[part 4 of 11: package /CANAnalyzer/CommunicationClusters]
AUTOSAR XML (schema 00051)
package /CANAnalyzer/CommunicationClusters  (continued)
  can cluster CAN_FD_IPB_41  (continued)
    can physical channel Channel  (continued)
      frame StatusBLEDeviceNameFBD_VR: id 0x28F, frame-length=32, can-addressing-mode=STANDARD, can-frame-rx-behavior=CAN-FD, can-frame-tx-behavior=CAN-FD
        pdu StatusBLEDeviceNameFBD_VR: length=32, unused-bit-pattern=0
          signal StatusBLEDeviceNameFBD_VR_Character00: start 0, 8 bit, little-endian, data-type-policy=OVERRIDE, base-type=uint8, compu {phys=raw}, range phys 0..252
          signal StatusBLEDeviceNameFBD_VR_Character01: start 8, 8 bit, little-endian, data-type-policy=OVERRIDE, base-type=uint8, compu {phys=raw}, range phys 0..252
          signal StatusBLEDeviceNameFBD_VR_Character02: start 16, 8 bit, little-endian, data-type-policy=OVERRIDE, base-type=uint8, compu {phys=raw}, range phys 0..252
          signal StatusBLEDeviceNameFBD_VR_Character03: start 24, 8 bit, little-endian, data-type-policy=OVERRIDE, base-type=uint8, compu {phys=raw}, range phys 0..252
          signal StatusBLEDeviceNameFBD_VR_Character04: start 32, 8 bit, little-endian, data-type-policy=OVERRIDE, base-type=uint8, compu {phys=raw}, range phys 0..252
          signal StatusBLEDeviceNameFBD_VR_Character05: start 40, 8 bit, little-endian, data-type-policy=OVERRIDE, base-type=uint8, compu {phys=raw}, range phys 0..252
          signal StatusBLEDeviceNameFBD_VR_Character06: start 48, 8 bit, little-endian, data-type-policy=OVERRIDE, base-type=uint8, compu {phys=raw}, range phys 0..252
          signal StatusBLEDeviceNameFBD_VR_Character07: start 56, 8 bit, little-endian, data-type-policy=OVERRIDE, base-type=uint8, compu {phys=raw}, range phys 0..252
          signal StatusBLEDeviceNameFBD_VR_Character08: start 64, 8 bit, little-endian, data-type-policy=OVERRIDE, base-type=uint8, compu {phys=raw}, range phys 0..252
          signal StatusBLEDeviceNameFBD_VR_Character09: start 72, 8 bit, little-endian, data-type-policy=OVERRIDE, base-type=uint8, compu {phys=raw}, range phys 0..252
          signal StatusBLEDeviceNameFBD_VR_Character10: start 80, 8 bit, little-endian, data-type-policy=OVERRIDE, base-type=uint8, compu {phys=raw}, range phys 0..252
          signal StatusBLEDeviceNameFBD_VR_Character11: start 88, 8 bit, little-endian, data-type-policy=OVERRIDE, base-type=uint8, compu {phys=raw}, range phys 0..252
          signal StatusBLEDeviceNameFBD_VR_Character12: start 96, 8 bit, little-endian, data-type-policy=OVERRIDE, base-type=uint8, compu {phys=raw}, range phys 0..252
          signal StatusBLEDeviceNameFBD_VR_Character13: start 104, 8 bit, little-endian, data-type-policy=OVERRIDE, base-type=uint8, compu {phys=raw}, range phys 0..252
          signal StatusBLEDeviceNameFBD_VR_Character14: start 112, 8 bit, little-endian, data-type-policy=OVERRIDE, base-type=uint8, compu {phys=raw}, range phys 0..252
          signal StatusBLEDeviceNameFBD_VR_Character15: start 120, 8 bit, little-endian, data-type-policy=OVERRIDE, base-type=uint8, compu {phys=raw}, range phys 0..252
          signal StatusBLEDeviceNameFBD_VR_Character16: start 128, 8 bit, little-endian, data-type-policy=OVERRIDE, base-type=uint8, compu {phys=raw}, range phys 0..252
          signal StatusBLEDeviceNameFBD_VR_Character17: start 136, 8 bit, little-endian, data-type-policy=OVERRIDE, base-type=uint8, compu {phys=raw}, range phys 0..252
          signal StatusBLEDeviceNameFBD_VR_Character18: start 144, 8 bit, little-endian, data-type-policy=OVERRIDE, base-type=uint8, compu {phys=raw}, range phys 0..252
          signal StatusBLEDeviceNameFBD_VR_Character19: start 152, 8 bit, little-endian, data-type-policy=OVERRIDE, base-type=uint8, compu {phys=raw}, range phys 0..252
          signal StatusBLEDeviceNameFBD_VR_Character20: start 160, 8 bit, little-endian, data-type-policy=OVERRIDE, base-type=uint8, compu {phys=raw}, range phys 0..252
          signal StatusBLEDeviceNameFBD_VR_Character21: start 168, 8 bit, little-endian, data-type-policy=OVERRIDE, base-type=uint8, compu {phys=raw}, range phys 0..252
          signal StatusBLEDeviceNameFBD_VR_Character22: start 176, 8 bit, little-endian, data-type-policy=OVERRIDE, base-type=uint8, compu {phys=raw}, range phys 0..252
          signal StatusBLEDeviceNameFBD_VR_Character23: start 184, 8 bit, little-endian, data-type-policy=OVERRIDE, base-type=uint8, compu {phys=raw}, range phys 0..252
          signal StatusBLEDeviceNameFBD_VR_Character24: start 192, 8 bit, little-endian, data-type-policy=OVERRIDE, base-type=uint8, compu {phys=raw}, range phys 0..252
          signal StatusBLEDeviceNameFBD_VR_Character25: start 200, 8 bit, little-endian, data-type-policy=OVERRIDE, base-type=uint8, compu {phys=raw}, range phys 0..252
          signal StatusBLEDeviceNameFBD_VR_Character26: start 208, 8 bit, little-endian, data-type-policy=OVERRIDE, base-type=uint8, compu {phys=raw}, range phys 0..252
          signal StatusBLEDeviceNameFBD_VR_Character27: start 216, 8 bit, little-endian, data-type-policy=OVERRIDE, base-type=uint8, compu {phys=raw}, range phys 0..252
          signal StatusBLEDeviceNameFBD_VR_Character28: start 224, 8 bit, little-endian, data-type-policy=OVERRIDE, base-type=uint8, compu {phys=raw}, range phys 0..252
          signal StatusBLEDeviceNameFBD_VR_Character29: start 232, 8 bit, little-endian, data-type-policy=OVERRIDE, base-type=uint8, compu {phys=raw}, range phys 0..252
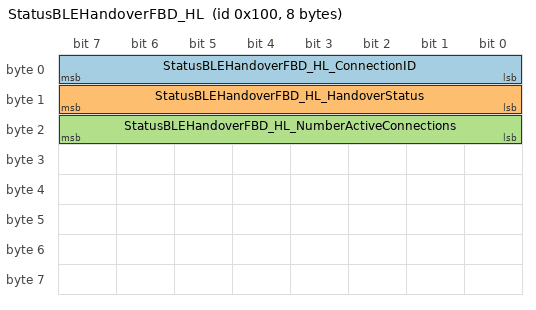
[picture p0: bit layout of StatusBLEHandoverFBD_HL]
      frame StatusBLEHandoverFBD_HL: id 0x100, frame-length=8, can-addressing-mode=STANDARD, can-frame-rx-behavior=CAN-20, can-frame-tx-behavior=CAN-20
        pdu StatusBLEHandoverFBD_HL: length=8, unused-bit-pattern=0
          signal StatusBLEHandoverFBD_HL_ConnectionID: start 0, 8 bit, little-endian, data-type-policy=OVERRIDE, base-type=uint8, compu {phys=raw}, range phys 0..252
          signal StatusBLEHandoverFBD_HL_HandoverStatus: start 8, 8 bit, little-endian, data-type-policy=OVERRIDE, compu {phys=raw}
          signal StatusBLEHandoverFBD_HL_NumberActiveConnections: start 16, 8 bit, little-endian, data-type-policy=OVERRIDE, base-type=uint8, compu {phys=raw}, range phys 0..252
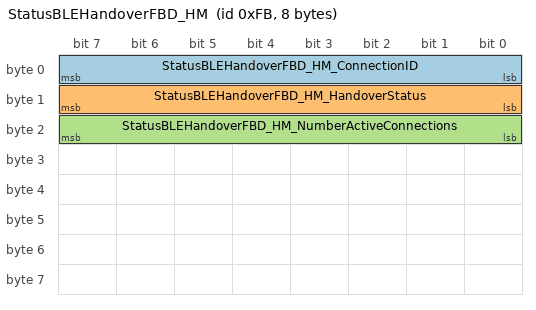
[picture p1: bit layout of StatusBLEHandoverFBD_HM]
      frame StatusBLEHandoverFBD_HM: id 0xFB, frame-length=8, can-addressing-mode=STANDARD, can-frame-rx-behavior=CAN-20, can-frame-tx-behavior=CAN-20
        pdu StatusBLEHandoverFBD_HM: length=8, unused-bit-pattern=0
          signal StatusBLEHandoverFBD_HM_ConnectionID: start 0, 8 bit, little-endian, data-type-policy=OVERRIDE, base-type=uint8, compu {phys=raw}, range phys 0..252
          signal StatusBLEHandoverFBD_HM_HandoverStatus: start 8, 8 bit, little-endian, data-type-policy=OVERRIDE, compu {phys=raw}
          signal StatusBLEHandoverFBD_HM_NumberActiveConnections: start 16, 8 bit, little-endian, data-type-policy=OVERRIDE, base-type=uint8, compu {phys=raw}, range phys 0..252
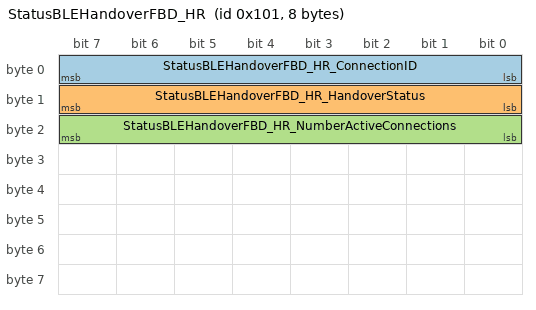
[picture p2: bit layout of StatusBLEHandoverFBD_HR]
      frame StatusBLEHandoverFBD_HR: id 0x101, frame-length=8, can-addressing-mode=STANDARD, can-frame-rx-behavior=CAN-20, can-frame-tx-behavior=CAN-20
        pdu StatusBLEHandoverFBD_HR: length=8, unused-bit-pattern=0
          signal StatusBLEHandoverFBD_HR_ConnectionID: start 0, 8 bit, little-endian, data-type-policy=OVERRIDE, base-type=uint8, compu {phys=raw}, range phys 0..252
          signal StatusBLEHandoverFBD_HR_HandoverStatus: start 8, 8 bit, little-endian, data-type-policy=OVERRIDE, compu {phys=raw}
          signal StatusBLEHandoverFBD_HR_NumberActiveConnections: start 16, 8 bit, little-endian, data-type-policy=OVERRIDE, base-type=uint8, compu {phys=raw}, range phys 0..252
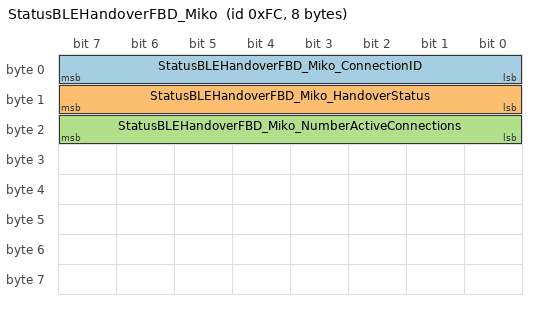
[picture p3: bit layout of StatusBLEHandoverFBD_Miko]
      frame StatusBLEHandoverFBD_Miko: id 0xFC, frame-length=8, can-addressing-mode=STANDARD, can-frame-rx-behavior=CAN-20, can-frame-tx-behavior=CAN-20
        pdu StatusBLEHandoverFBD_Miko: length=8, unused-bit-pattern=0
          signal StatusBLEHandoverFBD_Miko_ConnectionID: start 0, 8 bit, little-endian, data-type-policy=OVERRIDE, base-type=uint8, compu {phys=raw}, range phys 0..252
          signal StatusBLEHandoverFBD_Miko_HandoverStatus: start 8, 8 bit, little-endian, data-type-policy=OVERRIDE, compu {phys=raw}
          signal StatusBLEHandoverFBD_Miko_NumberActiveConnections: start 16, 8 bit, little-endian, data-type-policy=OVERRIDE, base-type=uint8, compu {phys=raw}, range phys 0..252
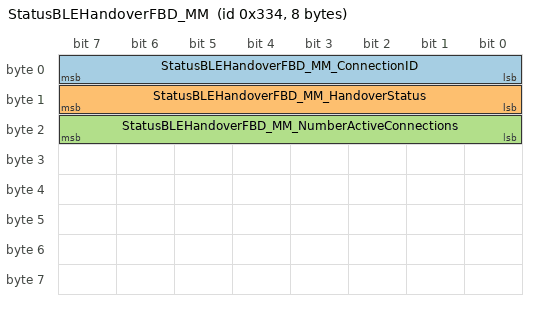
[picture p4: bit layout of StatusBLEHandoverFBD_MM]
      frame StatusBLEHandoverFBD_MM: id 0x334, frame-length=8, can-addressing-mode=STANDARD, can-frame-rx-behavior=CAN-20, can-frame-tx-behavior=CAN-20
        pdu StatusBLEHandoverFBD_MM: length=8, unused-bit-pattern=0
          signal StatusBLEHandoverFBD_MM_ConnectionID: start 0, 8 bit, little-endian, data-type-policy=OVERRIDE, base-type=uint8, compu {phys=raw}, range phys 0..252
          signal StatusBLEHandoverFBD_MM_HandoverStatus: start 8, 8 bit, little-endian, data-type-policy=OVERRIDE, compu {phys=raw}
          signal StatusBLEHandoverFBD_MM_NumberActiveConnections: start 16, 8 bit, little-endian, data-type-policy=OVERRIDE, base-type=uint8, compu {phys=raw}, range phys 0..252
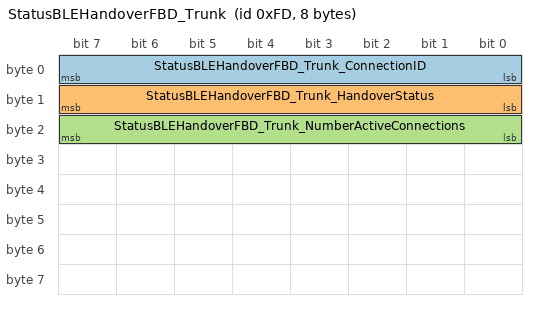
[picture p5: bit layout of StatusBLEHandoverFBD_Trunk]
      frame StatusBLEHandoverFBD_Trunk: id 0xFD, frame-length=8, can-addressing-mode=STANDARD, can-frame-rx-behavior=CAN-20, can-frame-tx-behavior=CAN-20
        pdu StatusBLEHandoverFBD_Trunk: length=8, unused-bit-pattern=0
          signal StatusBLEHandoverFBD_Trunk_ConnectionID: start 0, 8 bit, little-endian, data-type-policy=OVERRIDE, base-type=uint8, compu {phys=raw}, range phys 0..252
          signal StatusBLEHandoverFBD_Trunk_HandoverStatus: start 8, 8 bit, little-endian, data-type-policy=OVERRIDE, compu {phys=raw}
          signal StatusBLEHandoverFBD_Trunk_NumberActiveConnections: start 16, 8 bit, little-endian, data-type-policy=OVERRIDE, base-type=uint8, compu {phys=raw}, range phys 0..252
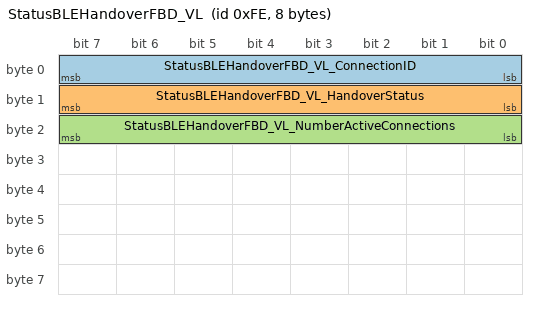
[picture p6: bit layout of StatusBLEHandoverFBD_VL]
      frame StatusBLEHandoverFBD_VL: id 0xFE, frame-length=8, can-addressing-mode=STANDARD, can-frame-rx-behavior=CAN-20, can-frame-tx-behavior=CAN-20
        pdu StatusBLEHandoverFBD_VL: length=8, unused-bit-pattern=0
          signal StatusBLEHandoverFBD_VL_ConnectionID: start 0, 8 bit, little-endian, data-type-policy=OVERRIDE, base-type=uint8, compu {phys=raw}, range phys 0..252
          signal StatusBLEHandoverFBD_VL_HandoverStatus: start 8, 8 bit, little-endian, data-type-policy=OVERRIDE, compu {phys=raw}
          signal StatusBLEHandoverFBD_VL_NumberActiveConnections: start 16, 8 bit, little-endian, data-type-policy=OVERRIDE, base-type=uint8, compu {phys=raw}, range phys 0..252
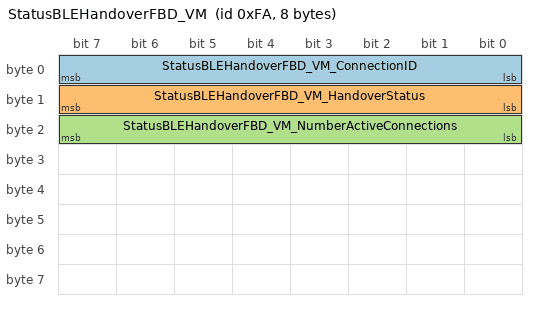
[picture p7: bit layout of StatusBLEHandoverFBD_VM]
      frame StatusBLEHandoverFBD_VM: id 0xFA, frame-length=8, can-addressing-mode=STANDARD, can-frame-rx-behavior=CAN-20, can-frame-tx-behavior=CAN-20
        pdu StatusBLEHandoverFBD_VM: length=8, unused-bit-pattern=0
          signal StatusBLEHandoverFBD_VM_ConnectionID: start 0, 8 bit, little-endian, data-type-policy=OVERRIDE, base-type=uint8, compu {phys=raw}, range phys 0..252
          signal StatusBLEHandoverFBD_VM_HandoverStatus: start 8, 8 bit, little-endian, data-type-policy=OVERRIDE, compu {phys=raw}
          signal StatusBLEHandoverFBD_VM_NumberActiveConnections: start 16, 8 bit, little-endian, data-type-policy=OVERRIDE, base-type=uint8, compu {phys=raw}, range phys 0..252
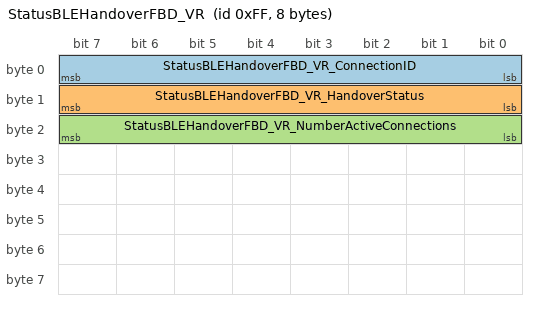
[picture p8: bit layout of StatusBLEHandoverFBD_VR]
      frame StatusBLEHandoverFBD_VR: id 0xFF, frame-length=8, can-addressing-mode=STANDARD, can-frame-rx-behavior=CAN-20, can-frame-tx-behavior=CAN-20
        pdu StatusBLEHandoverFBD_VR: length=8, unused-bit-pattern=0
          signal StatusBLEHandoverFBD_VR_ConnectionID: start 0, 8 bit, little-endian, data-type-policy=OVERRIDE, base-type=uint8, compu {phys=raw}, range phys 0..252
          signal StatusBLEHandoverFBD_VR_HandoverStatus: start 8, 8 bit, little-endian, data-type-policy=OVERRIDE, compu {phys=raw}
          signal StatusBLEHandoverFBD_VR_NumberActiveConnections: start 16, 8 bit, little-endian, data-type-policy=OVERRIDE, base-type=uint8, compu {phys=raw}, range phys 0..252
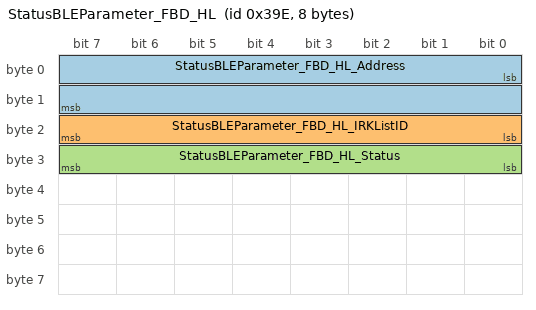
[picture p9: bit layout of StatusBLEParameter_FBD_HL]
      frame StatusBLEParameter_FBD_HL: id 0x39E, frame-length=8, can-addressing-mode=STANDARD, can-frame-rx-behavior=CAN-20, can-frame-tx-behavior=CAN-20
        pdu StatusBLEParameter_FBD_HL: length=8, unused-bit-pattern=0
          signal StatusBLEParameter_FBD_HL_Address: start 0, 16 bit, little-endian, data-type-policy=OVERRIDE, compu {phys=raw}
          signal StatusBLEParameter_FBD_HL_IRKListID: start 16, 8 bit, little-endian, data-type-policy=OVERRIDE, base-type=uint8, compu {phys=raw}, range phys 0..252
          signal StatusBLEParameter_FBD_HL_Status: start 24, 8 bit, little-endian, data-type-policy=OVERRIDE, base-type=uint8, compu {phys=raw}, range phys 0..255
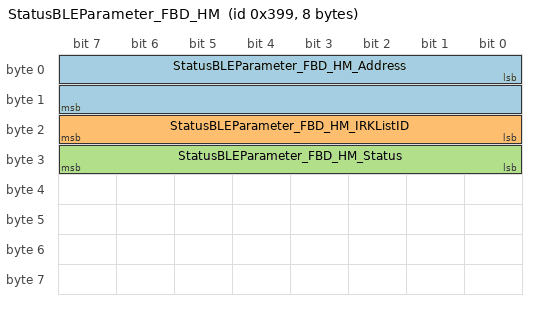
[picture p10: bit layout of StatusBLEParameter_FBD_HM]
      frame StatusBLEParameter_FBD_HM: id 0x399, frame-length=8, can-addressing-mode=STANDARD, can-frame-rx-behavior=CAN-20, can-frame-tx-behavior=CAN-20
        pdu StatusBLEParameter_FBD_HM: length=8, unused-bit-pattern=0
          signal StatusBLEParameter_FBD_HM_Address: start 0, 16 bit, little-endian, data-type-policy=OVERRIDE, compu {phys=raw}
          signal StatusBLEParameter_FBD_HM_IRKListID: start 16, 8 bit, little-endian, data-type-policy=OVERRIDE, base-type=uint8, compu {phys=raw}, range phys 0..252
          signal StatusBLEParameter_FBD_HM_Status: start 24, 8 bit, little-endian, data-type-policy=OVERRIDE, base-type=uint8, compu {phys=raw}, range phys 0..255
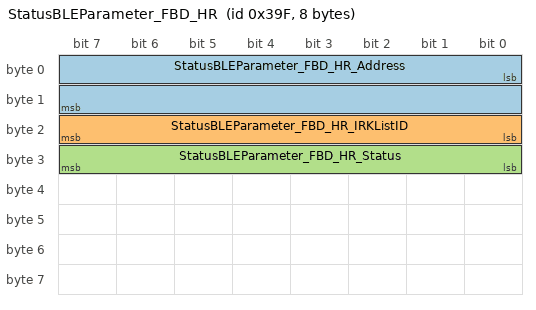
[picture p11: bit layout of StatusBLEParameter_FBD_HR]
      frame StatusBLEParameter_FBD_HR: id 0x39F, frame-length=8, can-addressing-mode=STANDARD, can-frame-rx-behavior=CAN-20, can-frame-tx-behavior=CAN-20
        pdu StatusBLEParameter_FBD_HR: length=8, unused-bit-pattern=0
          signal StatusBLEParameter_FBD_HR_Address: start 0, 16 bit, little-endian, data-type-policy=OVERRIDE, compu {phys=raw}
          signal StatusBLEParameter_FBD_HR_IRKListID: start 16, 8 bit, little-endian, data-type-policy=OVERRIDE, base-type=uint8, compu {phys=raw}, range phys 0..252
          signal StatusBLEParameter_FBD_HR_Status: start 24, 8 bit, little-endian, data-type-policy=OVERRIDE, base-type=uint8, compu {phys=raw}, range phys 0..255
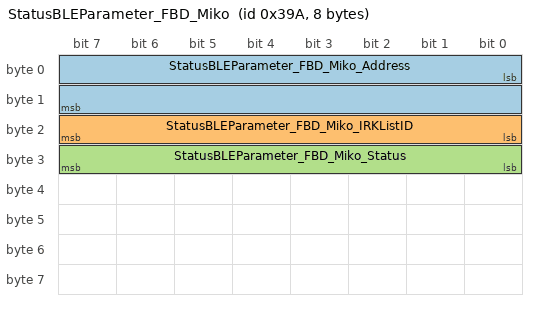
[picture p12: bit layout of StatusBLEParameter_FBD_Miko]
      frame StatusBLEParameter_FBD_Miko: id 0x39A, frame-length=8, can-addressing-mode=STANDARD, can-frame-rx-behavior=CAN-20, can-frame-tx-behavior=CAN-20
        pdu StatusBLEParameter_FBD_Miko: length=8, unused-bit-pattern=0
          signal StatusBLEParameter_FBD_Miko_Address: start 0, 16 bit, little-endian, data-type-policy=OVERRIDE, compu {phys=raw}
          signal StatusBLEParameter_FBD_Miko_IRKListID: start 16, 8 bit, little-endian, data-type-policy=OVERRIDE, base-type=uint8, compu {phys=raw}, range phys 0..252
          signal StatusBLEParameter_FBD_Miko_Status: start 24, 8 bit, little-endian, data-type-policy=OVERRIDE, base-type=uint8, compu {phys=raw}, range phys 0..255
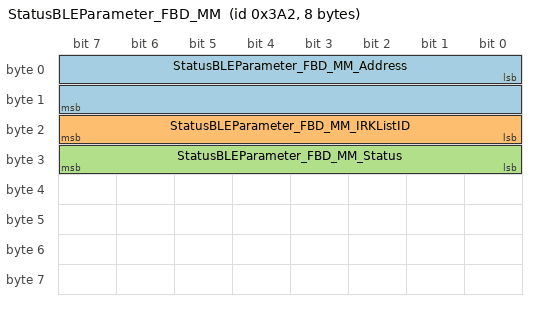
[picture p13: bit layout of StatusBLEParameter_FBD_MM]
      frame StatusBLEParameter_FBD_MM: id 0x3A2, frame-length=8, can-addressing-mode=STANDARD, can-frame-rx-behavior=CAN-20, can-frame-tx-behavior=CAN-20
        pdu StatusBLEParameter_FBD_MM: length=8, unused-bit-pattern=0
          signal StatusBLEParameter_FBD_MM_Address: start 0, 16 bit, little-endian, data-type-policy=OVERRIDE, compu {phys=raw}
          signal StatusBLEParameter_FBD_MM_IRKListID: start 16, 8 bit, little-endian, data-type-policy=OVERRIDE, base-type=uint8, compu {phys=raw}, range phys 0..252
          signal StatusBLEParameter_FBD_MM_Status: start 24, 8 bit, little-endian, data-type-policy=OVERRIDE, base-type=uint8, compu {phys=raw}, range phys 0..255
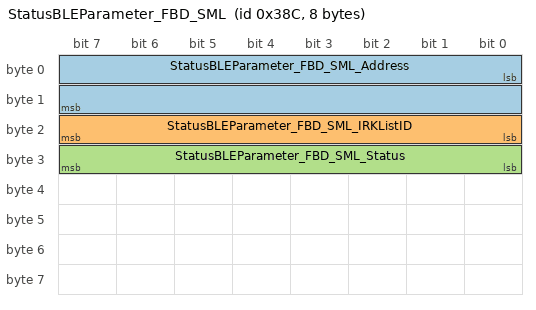
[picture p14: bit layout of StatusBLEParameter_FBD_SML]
      frame StatusBLEParameter_FBD_SML: id 0x38C, frame-length=8, can-addressing-mode=STANDARD, can-frame-rx-behavior=CAN-20, can-frame-tx-behavior=CAN-20
        pdu StatusBLEParameter_FBD_SML: length=8, unused-bit-pattern=0
          signal StatusBLEParameter_FBD_SML_Address: start 0, 16 bit, little-endian, data-type-policy=OVERRIDE, compu {phys=raw}
          signal StatusBLEParameter_FBD_SML_IRKListID: start 16, 8 bit, little-endian, data-type-policy=OVERRIDE, base-type=uint8, compu {phys=raw}, range phys 0..252
          signal StatusBLEParameter_FBD_SML_Status: start 24, 8 bit, little-endian, data-type-policy=OVERRIDE, base-type=uint8, compu {phys=raw}, range phys 0..255
      frame StatusBLEParameter_FBD_SMR: id 0x396, frame-length=8, can-addressing-mode=STANDARD, can-frame-rx-behavior=CAN-20, can-frame-tx-behavior=CAN-20
        pdu StatusBLEParameter_FBD_SMR: length=8, unused-bit-pattern=0
          signal StatusBLEParameter_FBD_SMR_Address: start 0, 16 bit, little-endian, data-type-policy=OVERRIDE, compu {phys=raw}
          signal StatusBLEParameter_FBD_SMR_IRKListID: start 16, 8 bit, little-endian, data-type-policy=OVERRIDE, base-type=uint8, compu {phys=raw}, range phys 0..252
          signal StatusBLEParameter_FBD_SMR_Status: start 24, 8 bit, little-endian, data-type-policy=OVERRIDE, base-type=uint8, compu {phys=raw}, range phys 0..255
      frame StatusBLEParameter_FBD_Trunk: id 0x39B, frame-length=8, can-addressing-mode=STANDARD, can-frame-rx-behavior=CAN-20, can-frame-tx-behavior=CAN-20
        pdu StatusBLEParameter_FBD_Trunk: length=8, unused-bit-pattern=0
          signal StatusBLEParameter_FBD_Trunk_Address: start 0, 16 bit, little-endian, data-type-policy=OVERRIDE, compu {phys=raw}
          signal StatusBLEParameter_FBD_Trunk_IRKListID: start 16, 8 bit, little-endian, data-type-policy=OVERRIDE, base-type=uint8, compu {phys=raw}, range phys 0..252
          signal StatusBLEParameter_FBD_Trunk_Status: start 24, 8 bit, little-endian, data-type-policy=OVERRIDE, base-type=uint8, compu {phys=raw}, range phys 0..255
      frame StatusBLEParameter_FBD_VL: id 0x39C, frame-length=8, can-addressing-mode=STANDARD, can-frame-rx-behavior=CAN-20, can-frame-tx-behavior=CAN-20
        pdu StatusBLEParameter_FBD_VL: length=8, unused-bit-pattern=0
          signal StatusBLEParameter_FBD_VL_Address: start 0, 16 bit, little-endian, data-type-policy=OVERRIDE, compu {phys=raw}
          signal StatusBLEParameter_FBD_VL_IRKListID: start 16, 8 bit, little-endian, data-type-policy=OVERRIDE, base-type=uint8, compu {phys=raw}, range phys 0..252
          signal StatusBLEParameter_FBD_VL_Status: start 24, 8 bit, little-endian, data-type-policy=OVERRIDE, base-type=uint8, compu {phys=raw}, range phys 0..255
      frame StatusBLEParameter_FBD_VM: id 0x398, frame-length=8, can-addressing-mode=STANDARD, can-frame-rx-behavior=CAN-20, can-frame-tx-behavior=CAN-20
        pdu StatusBLEParameter_FBD_VM: length=8, unused-bit-pattern=0
          signal StatusBLEParameter_FBD_VM_Address: start 0, 16 bit, little-endian, data-type-policy=OVERRIDE, compu {phys=raw}
          signal StatusBLEParameter_FBD_VM_IRKListID: start 16, 8 bit, little-endian, data-type-policy=OVERRIDE, base-type=uint8, compu {phys=raw}, range phys 0..252
          signal StatusBLEParameter_FBD_VM_Status: start 24, 8 bit, little-endian, data-type-policy=OVERRIDE, base-type=uint8, compu {phys=raw}, range phys 0..255
      frame StatusBLEParameter_FBD_VR: id 0x39D, frame-length=8, can-addressing-mode=STANDARD, can-frame-rx-behavior=CAN-20, can-frame-tx-behavior=CAN-20
        pdu StatusBLEParameter_FBD_VR: length=8, unused-bit-pattern=0
          signal StatusBLEParameter_FBD_VR_Address: start 0, 16 bit, little-endian, data-type-policy=OVERRIDE, compu {phys=raw}
          signal StatusBLEParameter_FBD_VR_IRKListID: start 16, 8 bit, little-endian, data-type-policy=OVERRIDE, base-type=uint8, compu {phys=raw}, range phys 0..252
          signal StatusBLEParameter_FBD_VR_Status: start 24, 8 bit, little-endian, data-type-policy=OVERRIDE, base-type=uint8, compu {phys=raw}, range phys 0..255
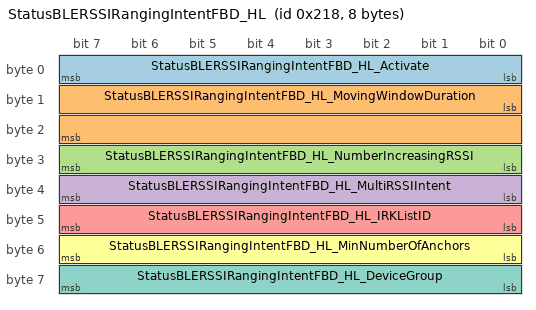
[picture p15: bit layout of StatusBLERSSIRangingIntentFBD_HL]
      frame StatusBLERSSIRangingIntentFBD_HL: id 0x218, frame-length=8, can-addressing-mode=STANDARD, can-frame-rx-behavior=CAN-20, can-frame-tx-behavior=CAN-20
        pdu StatusBLERSSIRangingIntentFBD_HL: length=8, unused-bit-pattern=0
          signal StatusBLERSSIRangingIntentFBD_HL_Activate: start 0, 8 bit, little-endian, data-type-policy=OVERRIDE, base-type=uint8, compu {phys=raw}, range phys 0..252
          signal StatusBLERSSIRangingIntentFBD_HL_MovingWindowDuration: start 8, 16 bit, little-endian, data-type-policy=OVERRIDE, base-type=uint16, compu {phys=raw; unit ms}, range phys 0..65532
          signal StatusBLERSSIRangingIntentFBD_HL_NumberIncreasingRSSI: start 24, 8 bit, little-endian, data-type-policy=OVERRIDE, base-type=uint8, compu {phys=raw}, range phys 0..252
          signal StatusBLERSSIRangingIntentFBD_HL_MultiRSSIIntent: start 32, 8 bit, little-endian, data-type-policy=OVERRIDE, base-type=uint8, compu {phys=raw}, range phys 0..252
          signal StatusBLERSSIRangingIntentFBD_HL_IRKListID: start 40, 8 bit, little-endian, data-type-policy=OVERRIDE, base-type=uint8, compu {phys=raw}, range phys 0..252
          signal StatusBLERSSIRangingIntentFBD_HL_MinNumberOfAnchors: start 48, 8 bit, little-endian, data-type-policy=OVERRIDE, base-type=uint8, compu {phys=raw}, range phys 0..252
          signal StatusBLERSSIRangingIntentFBD_HL_DeviceGroup: start 56, 8 bit, little-endian, data-type-policy=OVERRIDE, base-type=uint8, compu {phys=raw}, range phys 0..252
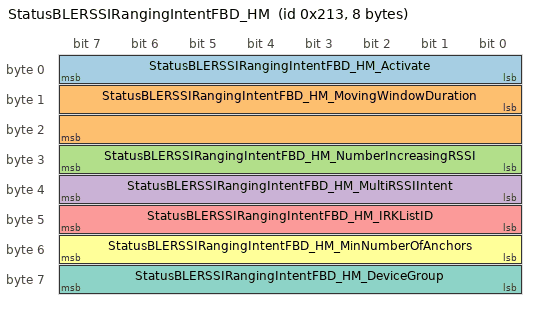
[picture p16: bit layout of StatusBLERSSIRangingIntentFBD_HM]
      frame StatusBLERSSIRangingIntentFBD_HM: id 0x213, frame-length=8, can-addressing-mode=STANDARD, can-frame-rx-behavior=CAN-20, can-frame-tx-behavior=CAN-20
        pdu StatusBLERSSIRangingIntentFBD_HM: length=8, unused-bit-pattern=0
          signal StatusBLERSSIRangingIntentFBD_HM_Activate: start 0, 8 bit, little-endian, data-type-policy=OVERRIDE, base-type=uint8, compu {phys=raw}, range phys 0..252
          signal StatusBLERSSIRangingIntentFBD_HM_MovingWindowDuration: start 8, 16 bit, little-endian, data-type-policy=OVERRIDE, base-type=uint16, compu {phys=raw; unit ms}, range phys 0..65532
          signal StatusBLERSSIRangingIntentFBD_HM_NumberIncreasingRSSI: start 24, 8 bit, little-endian, data-type-policy=OVERRIDE, base-type=uint8, compu {phys=raw}, range phys 0..252
          signal StatusBLERSSIRangingIntentFBD_HM_MultiRSSIIntent: start 32, 8 bit, little-endian, data-type-policy=OVERRIDE, base-type=uint8, compu {phys=raw}, range phys 0..252
          signal StatusBLERSSIRangingIntentFBD_HM_IRKListID: start 40, 8 bit, little-endian, data-type-policy=OVERRIDE, base-type=uint8, compu {phys=raw}, range phys 0..252
          signal StatusBLERSSIRangingIntentFBD_HM_MinNumberOfAnchors: start 48, 8 bit, little-endian, data-type-policy=OVERRIDE, base-type=uint8, compu {phys=raw}, range phys 0..252
          signal StatusBLERSSIRangingIntentFBD_HM_DeviceGroup: start 56, 8 bit, little-endian, data-type-policy=OVERRIDE, base-type=uint8, compu {phys=raw}, range phys 0..252
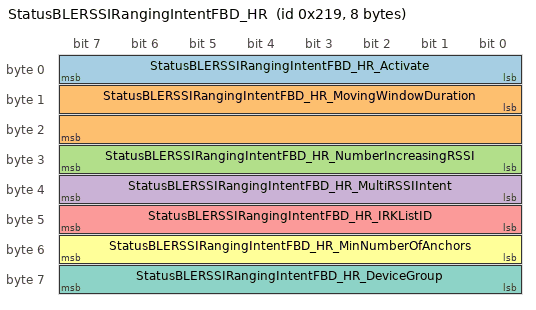
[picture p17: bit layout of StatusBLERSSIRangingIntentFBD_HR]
      frame StatusBLERSSIRangingIntentFBD_HR: id 0x219, frame-length=8, can-addressing-mode=STANDARD, can-frame-rx-behavior=CAN-20, can-frame-tx-behavior=CAN-20
        pdu StatusBLERSSIRangingIntentFBD_HR: length=8, unused-bit-pattern=0
          signal StatusBLERSSIRangingIntentFBD_HR_Activate: start 0, 8 bit, little-endian, data-type-policy=OVERRIDE, base-type=uint8, compu {phys=raw}, range phys 0..252
          signal StatusBLERSSIRangingIntentFBD_HR_MovingWindowDuration: start 8, 16 bit, little-endian, data-type-policy=OVERRIDE, base-type=uint16, compu {phys=raw; unit ms}, range phys 0..65532
          signal StatusBLERSSIRangingIntentFBD_HR_NumberIncreasingRSSI: start 24, 8 bit, little-endian, data-type-policy=OVERRIDE, base-type=uint8, compu {phys=raw}, range phys 0..252
          signal StatusBLERSSIRangingIntentFBD_HR_MultiRSSIIntent: start 32, 8 bit, little-endian, data-type-policy=OVERRIDE, base-type=uint8, compu {phys=raw}, range phys 0..252
          signal StatusBLERSSIRangingIntentFBD_HR_IRKListID: start 40, 8 bit, little-endian, data-type-policy=OVERRIDE, base-type=uint8, compu {phys=raw}, range phys 0..252
          signal StatusBLERSSIRangingIntentFBD_HR_MinNumberOfAnchors: start 48, 8 bit, little-endian, data-type-policy=OVERRIDE, base-type=uint8, compu {phys=raw}, range phys 0..252
          signal StatusBLERSSIRangingIntentFBD_HR_DeviceGroup: start 56, 8 bit, little-endian, data-type-policy=OVERRIDE, base-type=uint8, compu {phys=raw}, range phys 0..252
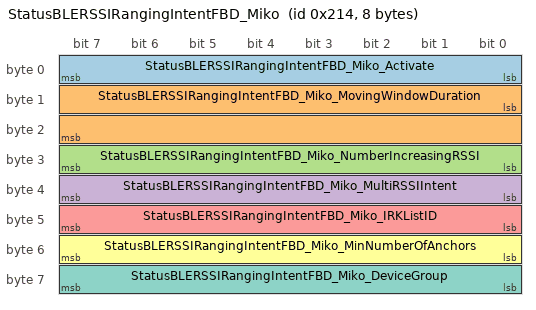
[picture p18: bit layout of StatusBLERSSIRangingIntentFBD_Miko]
      frame StatusBLERSSIRangingIntentFBD_Miko: id 0x214, frame-length=8, can-addressing-mode=STANDARD, can-frame-rx-behavior=CAN-20, can-frame-tx-behavior=CAN-20
        pdu StatusBLERSSIRangingIntentFBD_Miko: length=8, unused-bit-pattern=0
          signal StatusBLERSSIRangingIntentFBD_Miko_Activate: start 0, 8 bit, little-endian, data-type-policy=OVERRIDE, base-type=uint8, compu {phys=raw}, range phys 0..252
          signal StatusBLERSSIRangingIntentFBD_Miko_MovingWindowDuration: start 8, 16 bit, little-endian, data-type-policy=OVERRIDE, base-type=uint16, compu {phys=raw; unit ms}, range phys 0..65532
          signal StatusBLERSSIRangingIntentFBD_Miko_NumberIncreasingRSSI: start 24, 8 bit, little-endian, data-type-policy=OVERRIDE, base-type=uint8, compu {phys=raw}, range phys 0..252
          signal StatusBLERSSIRangingIntentFBD_Miko_MultiRSSIIntent: start 32, 8 bit, little-endian, data-type-policy=OVERRIDE, base-type=uint8, compu {phys=raw}, range phys 0..252
          signal StatusBLERSSIRangingIntentFBD_Miko_IRKListID: start 40, 8 bit, little-endian, data-type-policy=OVERRIDE, base-type=uint8, compu {phys=raw}, range phys 0..252
          signal StatusBLERSSIRangingIntentFBD_Miko_MinNumberOfAnchors: start 48, 8 bit, little-endian, data-type-policy=OVERRIDE, base-type=uint8, compu {phys=raw}, range phys 0..252
          signal StatusBLERSSIRangingIntentFBD_Miko_DeviceGroup: start 56, 8 bit, little-endian, data-type-policy=OVERRIDE, base-type=uint8, compu {phys=raw}, range phys 0..252
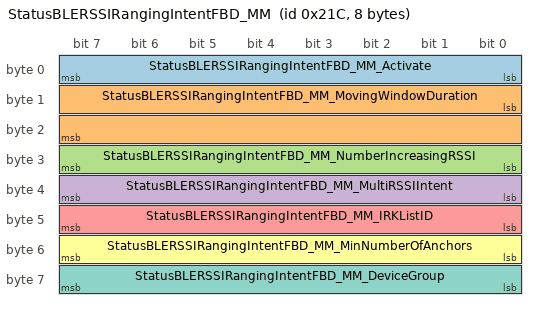
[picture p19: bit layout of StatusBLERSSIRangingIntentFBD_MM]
      frame StatusBLERSSIRangingIntentFBD_MM: id 0x21C, frame-length=8, can-addressing-mode=STANDARD, can-frame-rx-behavior=CAN-20, can-frame-tx-behavior=CAN-20
        pdu StatusBLERSSIRangingIntentFBD_MM: length=8, unused-bit-pattern=0
          signal StatusBLERSSIRangingIntentFBD_MM_Activate: start 0, 8 bit, little-endian, data-type-policy=OVERRIDE, base-type=uint8, compu {phys=raw}, range phys 0..252
          signal StatusBLERSSIRangingIntentFBD_MM_MovingWindowDuration: start 8, 16 bit, little-endian, data-type-policy=OVERRIDE, base-type=uint16, compu {phys=raw; unit ms}, range phys 0..65532
          signal StatusBLERSSIRangingIntentFBD_MM_NumberIncreasingRSSI: start 24, 8 bit, little-endian, data-type-policy=OVERRIDE, base-type=uint8, compu {phys=raw}, range phys 0..252
          signal StatusBLERSSIRangingIntentFBD_MM_MultiRSSIIntent: start 32, 8 bit, little-endian, data-type-policy=OVERRIDE, base-type=uint8, compu {phys=raw}, range phys 0..252
          signal StatusBLERSSIRangingIntentFBD_MM_IRKListID: start 40, 8 bit, little-endian, data-type-policy=OVERRIDE, base-type=uint8, compu {phys=raw}, range phys 0..252
          signal StatusBLERSSIRangingIntentFBD_MM_MinNumberOfAnchors: start 48, 8 bit, little-endian, data-type-policy=OVERRIDE, base-type=uint8, compu {phys=raw}, range phys 0..252
          signal StatusBLERSSIRangingIntentFBD_MM_DeviceGroup: start 56, 8 bit, little-endian, data-type-policy=OVERRIDE, base-type=uint8, compu {phys=raw}, range phys 0..252
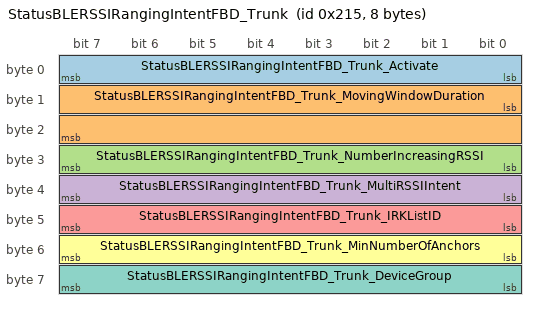
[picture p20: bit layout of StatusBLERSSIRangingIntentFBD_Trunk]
      frame StatusBLERSSIRangingIntentFBD_Trunk: id 0x215, frame-length=8, can-addressing-mode=STANDARD, can-frame-rx-behavior=CAN-20, can-frame-tx-behavior=CAN-20
        pdu StatusBLERSSIRangingIntentFBD_Trunk: length=8, unused-bit-pattern=0
          signal StatusBLERSSIRangingIntentFBD_Trunk_Activate: start 0, 8 bit, little-endian, data-type-policy=OVERRIDE, base-type=uint8, compu {phys=raw}, range phys 0..252
          signal StatusBLERSSIRangingIntentFBD_Trunk_MovingWindowDuration: start 8, 16 bit, little-endian, data-type-policy=OVERRIDE, base-type=uint16, compu {phys=raw; unit ms}, range phys 0..65532
          signal StatusBLERSSIRangingIntentFBD_Trunk_NumberIncreasingRSSI: start 24, 8 bit, little-endian, data-type-policy=OVERRIDE, base-type=uint8, compu {phys=raw}, range phys 0..252
          signal StatusBLERSSIRangingIntentFBD_Trunk_MultiRSSIIntent: start 32, 8 bit, little-endian, data-type-policy=OVERRIDE, base-type=uint8, compu {phys=raw}, range phys 0..252
          signal StatusBLERSSIRangingIntentFBD_Trunk_IRKListID: start 40, 8 bit, little-endian, data-type-policy=OVERRIDE, base-type=uint8, compu {phys=raw}, range phys 0..252
          signal StatusBLERSSIRangingIntentFBD_Trunk_MinNumberOfAnchors: start 48, 8 bit, little-endian, data-type-policy=OVERRIDE, base-type=uint8, compu {phys=raw}, range phys 0..252
          signal StatusBLERSSIRangingIntentFBD_Trunk_DeviceGroup: start 56, 8 bit, little-endian, data-type-policy=OVERRIDE, base-type=uint8, compu {phys=raw}, range phys 0..252
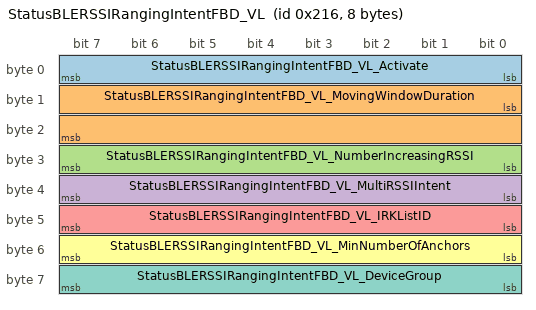
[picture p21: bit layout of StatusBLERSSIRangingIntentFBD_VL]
      frame StatusBLERSSIRangingIntentFBD_VL: id 0x216, frame-length=8, can-addressing-mode=STANDARD, can-frame-rx-behavior=CAN-20, can-frame-tx-behavior=CAN-20
        pdu StatusBLERSSIRangingIntentFBD_VL: length=8, unused-bit-pattern=0
          signal StatusBLERSSIRangingIntentFBD_VL_Activate: start 0, 8 bit, little-endian, data-type-policy=OVERRIDE, base-type=uint8, compu {phys=raw}, range phys 0..252
          signal StatusBLERSSIRangingIntentFBD_VL_MovingWindowDuration: start 8, 16 bit, little-endian, data-type-policy=OVERRIDE, base-type=uint16, compu {phys=raw; unit ms}, range phys 0..65532
          signal StatusBLERSSIRangingIntentFBD_VL_NumberIncreasingRSSI: start 24, 8 bit, little-endian, data-type-policy=OVERRIDE, base-type=uint8, compu {phys=raw}, range phys 0..252
          signal StatusBLERSSIRangingIntentFBD_VL_MultiRSSIIntent: start 32, 8 bit, little-endian, data-type-policy=OVERRIDE, base-type=uint8, compu {phys=raw}, range phys 0..252
          signal StatusBLERSSIRangingIntentFBD_VL_IRKListID: start 40, 8 bit, little-endian, data-type-policy=OVERRIDE, base-type=uint8, compu {phys=raw}, range phys 0..252
          signal StatusBLERSSIRangingIntentFBD_VL_MinNumberOfAnchors: start 48, 8 bit, little-endian, data-type-policy=OVERRIDE, base-type=uint8, compu {phys=raw}, range phys 0..252
          signal StatusBLERSSIRangingIntentFBD_VL_DeviceGroup: start 56, 8 bit, little-endian, data-type-policy=OVERRIDE, base-type=uint8, compu {phys=raw}, range phys 0..252
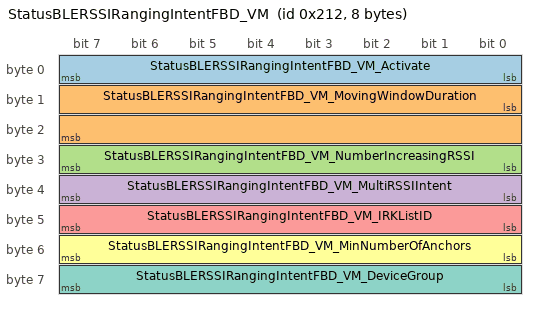
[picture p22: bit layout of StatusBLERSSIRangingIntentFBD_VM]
      frame StatusBLERSSIRangingIntentFBD_VM: id 0x212, frame-length=8, can-addressing-mode=STANDARD, can-frame-rx-behavior=CAN-20, can-frame-tx-behavior=CAN-20
        pdu StatusBLERSSIRangingIntentFBD_VM: length=8, unused-bit-pattern=0
          signal StatusBLERSSIRangingIntentFBD_VM_Activate: start 0, 8 bit, little-endian, data-type-policy=OVERRIDE, base-type=uint8, compu {phys=raw}, range phys 0..252
          signal StatusBLERSSIRangingIntentFBD_VM_MovingWindowDuration: start 8, 16 bit, little-endian, data-type-policy=OVERRIDE, base-type=uint16, compu {phys=raw; unit ms}, range phys 0..65532
          signal StatusBLERSSIRangingIntentFBD_VM_NumberIncreasingRSSI: start 24, 8 bit, little-endian, data-type-policy=OVERRIDE, base-type=uint8, compu {phys=raw}, range phys 0..252
          signal StatusBLERSSIRangingIntentFBD_VM_MultiRSSIIntent: start 32, 8 bit, little-endian, data-type-policy=OVERRIDE, base-type=uint8, compu {phys=raw}, range phys 0..252
          signal StatusBLERSSIRangingIntentFBD_VM_IRKListID: start 40, 8 bit, little-endian, data-type-policy=OVERRIDE, base-type=uint8, compu {phys=raw}, range phys 0..252
          signal StatusBLERSSIRangingIntentFBD_VM_MinNumberOfAnchors: start 48, 8 bit, little-endian, data-type-policy=OVERRIDE, base-type=uint8, compu {phys=raw}, range phys 0..252
          signal StatusBLERSSIRangingIntentFBD_VM_DeviceGroup: start 56, 8 bit, little-endian, data-type-policy=OVERRIDE, base-type=uint8, compu {phys=raw}, range phys 0..252
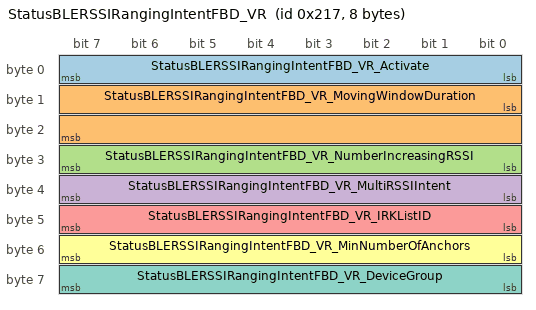
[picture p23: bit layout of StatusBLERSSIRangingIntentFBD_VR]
      frame StatusBLERSSIRangingIntentFBD_VR: id 0x217, frame-length=8, can-addressing-mode=STANDARD, can-frame-rx-behavior=CAN-20, can-frame-tx-behavior=CAN-20
        pdu StatusBLERSSIRangingIntentFBD_VR: length=8, unused-bit-pattern=0
          signal StatusBLERSSIRangingIntentFBD_VR_Activate: start 0, 8 bit, little-endian, data-type-policy=OVERRIDE, base-type=uint8, compu {phys=raw}, range phys 0..252
          signal StatusBLERSSIRangingIntentFBD_VR_MovingWindowDuration: start 8, 16 bit, little-endian, data-type-policy=OVERRIDE, base-type=uint16, compu {phys=raw; unit ms}, range phys 0..65532
          signal StatusBLERSSIRangingIntentFBD_VR_NumberIncreasingRSSI: start 24, 8 bit, little-endian, data-type-policy=OVERRIDE, base-type=uint8, compu {phys=raw}, range phys 0..252
          signal StatusBLERSSIRangingIntentFBD_VR_MultiRSSIIntent: start 32, 8 bit, little-endian, data-type-policy=OVERRIDE, base-type=uint8, compu {phys=raw}, range phys 0..252
          signal StatusBLERSSIRangingIntentFBD_VR_IRKListID: start 40, 8 bit, little-endian, data-type-policy=OVERRIDE, base-type=uint8, compu {phys=raw}, range phys 0..252
          signal StatusBLERSSIRangingIntentFBD_VR_MinNumberOfAnchors: start 48, 8 bit, little-endian, data-type-policy=OVERRIDE, base-type=uint8, compu {phys=raw}, range phys 0..252
          signal StatusBLERSSIRangingIntentFBD_VR_DeviceGroup: start 56, 8 bit, little-endian, data-type-policy=OVERRIDE, base-type=uint8, compu {phys=raw}, range phys 0..252
      frame StatusBLESettingsFBD_HL: id 0xD8, frame-length=20, can-addressing-mode=STANDARD, can-frame-rx-behavior=CAN-FD, can-frame-tx-behavior=CAN-FD
        pdu StatusBLESettingsFBD_HL: length=20, unused-bit-pattern=0
          signal StatusBLESettingsFBD_HL_BLEOperationMode: start 0, 8 bit, little-endian, data-type-policy=OVERRIDE, compu {phys=raw}
          signal StatusBLESettingsFBD_HL_AdvertisingInterval: start 8, 16 bit, little-endian, data-type-policy=OVERRIDE, base-type=uint16, compu {phys=raw}, range phys 0..65532
          signal StatusBLESettingsFBD_HL_ConnectionInterval: start 24, 16 bit, little-endian, data-type-policy=OVERRIDE, base-type=uint16, compu {phys=raw}, range phys 0..65532
          signal StatusBLESettingsFBD_HL_IRKListID: start 40, 8 bit, little-endian, data-type-policy=OVERRIDE, base-type=uint8, compu {phys=raw}, range phys 0..252
          signal StatusBLESettingsFBD_HL_SettingsBLELELRMode: start 48, 8 bit, little-endian, data-type-policy=OVERRIDE, compu {phys=raw}
          signal StatusBLESettingsFBD_HL_LR500_AdvertisingInterval: start 56, 16 bit, little-endian, data-type-policy=OVERRIDE, base-type=uint16, compu {phys=raw}, range phys 0..65532
          signal StatusBLESettingsFBD_HL_LR125_AdvertisingInterval: start 72, 16 bit, little-endian, data-type-policy=OVERRIDE, base-type=uint16, compu {phys=raw}, range phys 0..65532
          signal StatusBLESettingsFBD_HL_ExtendedAdvertising: start 88, 8 bit, little-endian, data-type-policy=OVERRIDE, compu {phys=raw}
          signal StatusBLESettingsFBD_HL_TxPower: start 96, 8 bit, little-endian, data-type-policy=OVERRIDE, base-type=uint8, compu {phys=raw}, range phys 0..252
          signal StatusBLESettingsFBD_HL_PSM: start 104, 8 bit, little-endian, data-type-policy=OVERRIDE, base-type=uint8, compu {phys=raw}, range phys 0..252
          signal StatusBLESettingsFBD_HL_RPAFrequency: start 112, 8 bit, little-endian, data-type-policy=OVERRIDE, base-type=uint8, compu {phys=raw}, range phys 0..252
          signal StatusBLESettingsFBD_HL_DCKVersion: start 120, 8 bit, little-endian, data-type-policy=OVERRIDE, base-type=uint8, compu {phys=raw}, range phys 0..252
          signal StatusBLESettingsFBD_HL_ScanRequest: start 128, 8 bit, little-endian, data-type-policy=OVERRIDE, compu {phys=raw}
      frame StatusBLESettingsFBD_HM: id 0xD3, frame-length=20, can-addressing-mode=STANDARD, can-frame-rx-behavior=CAN-FD, can-frame-tx-behavior=CAN-FD
        pdu StatusBLESettingsFBD_HM: length=20, unused-bit-pattern=0
          signal StatusBLESettingsFBD_HM_BLEOperationMode: start 0, 8 bit, little-endian, data-type-policy=OVERRIDE, compu {phys=raw}
          signal StatusBLESettingsFBD_HM_AdvertisingInterval: start 8, 16 bit, little-endian, data-type-policy=OVERRIDE, base-type=uint16, compu {phys=raw}, range phys 0..65532
          signal StatusBLESettingsFBD_HM_ConnectionInterval: start 24, 16 bit, little-endian, data-type-policy=OVERRIDE, base-type=uint16, compu {phys=raw}, range phys 0..65532
          signal StatusBLESettingsFBD_HM_IRKListID: start 40, 8 bit, little-endian, data-type-policy=OVERRIDE, base-type=uint8, compu {phys=raw}, range phys 0..252
          signal StatusBLESettingsFBD_HM_SettingsBLELELRMode: start 48, 8 bit, little-endian, data-type-policy=OVERRIDE, compu {phys=raw}
          signal StatusBLESettingsFBD_HM_LR500_AdvertisingInterval: start 56, 16 bit, little-endian, data-type-policy=OVERRIDE, base-type=uint16, compu {phys=raw}, range phys 0..65532
          signal StatusBLESettingsFBD_HM_LR125_AdvertisingInterval: start 72, 16 bit, little-endian, data-type-policy=OVERRIDE, base-type=uint16, compu {phys=raw}, range phys 0..65532
          signal StatusBLESettingsFBD_HM_ExtendedAdvertising: start 88, 8 bit, little-endian, data-type-policy=OVERRIDE, compu {phys=raw}
          signal StatusBLESettingsFBD_HM_TxPower: start 96, 8 bit, little-endian, data-type-policy=OVERRIDE, base-type=uint8, compu {phys=raw}, range phys 0..252
          signal StatusBLESettingsFBD_HM_PSM: start 104, 8 bit, little-endian, data-type-policy=OVERRIDE, base-type=uint8, compu {phys=raw}, range phys 0..252
          signal StatusBLESettingsFBD_HM_RPAFrequency: start 112, 8 bit, little-endian, data-type-policy=OVERRIDE, base-type=uint8, compu {phys=raw}, range phys 0..252
          signal StatusBLESettingsFBD_HM_DCKVersion: start 120, 8 bit, little-endian, data-type-policy=OVERRIDE, base-type=uint8, compu {phys=raw}, range phys 0..252
          signal StatusBLESettingsFBD_HM_ScanRequest: start 128, 8 bit, little-endian, data-type-policy=OVERRIDE, compu {phys=raw}
      frame StatusBLESettingsFBD_HR: id 0xD9, frame-length=20, can-addressing-mode=STANDARD, can-frame-rx-behavior=CAN-FD, can-frame-tx-behavior=CAN-FD
        pdu StatusBLESettingsFBD_HR: length=20, unused-bit-pattern=0
          signal StatusBLESettingsFBD_HR_BLEOperationMode: start 0, 8 bit, little-endian, data-type-policy=OVERRIDE, compu {phys=raw}
          signal StatusBLESettingsFBD_HR_AdvertisingInterval: start 8, 16 bit, little-endian, data-type-policy=OVERRIDE, base-type=uint16, compu {phys=raw}, range phys 0..65532
          signal StatusBLESettingsFBD_HR_ConnectionInterval: start 24, 16 bit, little-endian, data-type-policy=OVERRIDE, base-type=uint16, compu {phys=raw}, range phys 0..65532
          signal StatusBLESettingsFBD_HR_IRKListID: start 40, 8 bit, little-endian, data-type-policy=OVERRIDE, base-type=uint8, compu {phys=raw}, range phys 0..252
          signal StatusBLESettingsFBD_HR_SettingsBLELELRMode: start 48, 8 bit, little-endian, data-type-policy=OVERRIDE, compu {phys=raw}
          signal StatusBLESettingsFBD_HR_LR500_AdvertisingInterval: start 56, 16 bit, little-endian, data-type-policy=OVERRIDE, base-type=uint16, compu {phys=raw}, range phys 0..65532
          signal StatusBLESettingsFBD_HR_LR125_AdvertisingInterval: start 72, 16 bit, little-endian, data-type-policy=OVERRIDE, base-type=uint16, compu {phys=raw}, range phys 0..65532
          signal StatusBLESettingsFBD_HR_ExtendedAdvertising: start 88, 8 bit, little-endian, data-type-policy=OVERRIDE, compu {phys=raw}
          signal StatusBLESettingsFBD_HR_TxPower: start 96, 8 bit, little-endian, data-type-policy=OVERRIDE, base-type=uint8, compu {phys=raw}, range phys 0..252
          signal StatusBLESettingsFBD_HR_PSM: start 104, 8 bit, little-endian, data-type-policy=OVERRIDE, base-type=uint8, compu {phys=raw}, range phys 0..252
          signal StatusBLESettingsFBD_HR_RPAFrequency: start 112, 8 bit, little-endian, data-type-policy=OVERRIDE, base-type=uint8, compu {phys=raw}, range phys 0..252
          signal StatusBLESettingsFBD_HR_DCKVersion: start 120, 8 bit, little-endian, data-type-policy=OVERRIDE, base-type=uint8, compu {phys=raw}, range phys 0..252
          signal StatusBLESettingsFBD_HR_ScanRequest: start 128, 8 bit, little-endian, data-type-policy=OVERRIDE, compu {phys=raw}
      frame StatusBLESettingsFBD_Miko: id 0xD4, frame-length=20, can-addressing-mode=STANDARD, can-frame-rx-behavior=CAN-FD, can-frame-tx-behavior=CAN-FD
        pdu StatusBLESettingsFBD_Miko: length=20, unused-bit-pattern=0
          signal StatusBLESettingsFBD_Miko_BLEOperationMode: start 0, 8 bit, little-endian, data-type-policy=OVERRIDE, compu {phys=raw}
          signal StatusBLESettingsFBD_Miko_AdvertisingInterval: start 8, 16 bit, little-endian, data-type-policy=OVERRIDE, base-type=uint16, compu {phys=raw}, range phys 0..65532
          signal StatusBLESettingsFBD_Miko_ConnectionInterval: start 24, 16 bit, little-endian, data-type-policy=OVERRIDE, base-type=uint16, compu {phys=raw}, range phys 0..65532
          signal StatusBLESettingsFBD_Miko_IRKListID: start 40, 8 bit, little-endian, data-type-policy=OVERRIDE, compu {phys=raw}
          signal StatusBLESettingsFBD_Miko_SettingsBLELELRMode: start 48, 8 bit, little-endian, data-type-policy=OVERRIDE, base-type=uint8, compu {phys=raw}, range phys 0..252
          signal StatusBLESettingsFBD_Miko_LR500_AdvertisingInterval: start 56, 16 bit, little-endian, data-type-policy=OVERRIDE, base-type=uint16, compu {phys=raw}, range phys 0..65532
          signal StatusBLESettingsFBD_Miko_LR125_AdvertisingInterval: start 72, 16 bit, little-endian, data-type-policy=OVERRIDE, base-type=uint16, compu {phys=raw}, range phys 0..65532
          signal StatusBLESettingsFBD_Miko_ExtendedAdvertising: start 88, 8 bit, little-endian, data-type-policy=OVERRIDE, compu {phys=raw}
          signal StatusBLESettingsFBD_Miko_TxPower: start 96, 8 bit, little-endian, data-type-policy=OVERRIDE, base-type=uint8, compu {phys=raw}, range phys 0..252
          signal StatusBLESettingsFBD_Miko_PSM: start 104, 8 bit, little-endian, data-type-policy=OVERRIDE, base-type=uint8, compu {phys=raw}, range phys 0..252
          signal StatusBLESettingsFBD_Miko_RPAFrequency: start 112, 8 bit, little-endian, data-type-policy=OVERRIDE, base-type=uint8, compu {phys=raw}, range phys 0..252
          signal StatusBLESettingsFBD_Miko_DCKVersion: start 120, 8 bit, little-endian, data-type-policy=OVERRIDE, base-type=uint8, compu {phys=raw}, range phys 0..252
          signal StatusBLESettingsFBD_Miko_ScanRequest: start 128, 8 bit, little-endian, data-type-policy=OVERRIDE, compu {phys=raw}
      frame StatusBLESettingsFBD_MM: id 0xF0, frame-length=20, can-addressing-mode=STANDARD, can-frame-rx-behavior=CAN-FD, can-frame-tx-behavior=CAN-FD
        pdu StatusBLESettingsFBD_MM: length=20, unused-bit-pattern=0
          signal StatusBLESettingsFBD_MM_BLEOperationMode: start 0, 8 bit, little-endian, data-type-policy=OVERRIDE, compu {phys=raw}
          signal StatusBLESettingsFBD_MM_AdvertisingInterval: start 8, 16 bit, little-endian, data-type-policy=OVERRIDE, base-type=uint16, compu {phys=raw}, range phys 0..65532
          signal StatusBLESettingsFBD_MM_ConnectionInterval: start 24, 16 bit, little-endian, data-type-policy=OVERRIDE, base-type=uint16, compu {phys=raw}, range phys 0..65532
          signal StatusBLESettingsFBD_MM_IRKListID: start 40, 8 bit, little-endian, data-type-policy=OVERRIDE, base-type=uint8, compu {phys=raw}, range phys 0..252
          signal StatusBLESettingsFBD_MM_SettingsBLELELRMode: start 48, 8 bit, little-endian, data-type-policy=OVERRIDE, compu {phys=raw}
          signal StatusBLESettingsFBD_MM_LR500_AdvertisingInterval: start 56, 16 bit, little-endian, data-type-policy=OVERRIDE, base-type=uint16, compu {phys=raw}, range phys 0..65532
          signal StatusBLESettingsFBD_MM_LR125_AdvertisingInterval: start 72, 16 bit, little-endian, data-type-policy=OVERRIDE, base-type=uint16, compu {phys=raw}, range phys 0..65532
          signal StatusBLESettingsFBD_MM_ExtendedAdvertising: start 88, 8 bit, little-endian, data-type-policy=OVERRIDE, compu {phys=raw}
          signal StatusBLESettingsFBD_MM_TxPower: start 96, 8 bit, little-endian, data-type-policy=OVERRIDE, base-type=uint8, compu {phys=raw}, range phys 0..252
          signal StatusBLESettingsFBD_MM_PSM: start 104, 8 bit, little-endian, data-type-policy=OVERRIDE, base-type=uint8, compu {phys=raw}, range phys 0..252
          signal StatusBLESettingsFBD_MM_RPAFrequency: start 112, 8 bit, little-endian, data-type-policy=OVERRIDE, base-type=uint8, compu {phys=raw}, range phys 0..252
          signal StatusBLESettingsFBD_MM_DCKVersion: start 120, 8 bit, little-endian, data-type-policy=OVERRIDE, base-type=uint8, compu {phys=raw}, range phys 0..252
          signal StatusBLESettingsFBD_MM_ScanRequest: start 128, 8 bit, little-endian, data-type-policy=OVERRIDE, compu {phys=raw}
      frame StatusBLESettingsFBD_Trunk: id 0xD5, frame-length=20, can-addressing-mode=STANDARD, can-frame-rx-behavior=CAN-FD, can-frame-tx-behavior=CAN-FD
        pdu StatusBLESettingsFBD_Trunk: length=20, unused-bit-pattern=0
          signal StatusBLESettingsFBD_Trunk_BLEOperationMode: start 0, 8 bit, little-endian, data-type-policy=OVERRIDE, compu {phys=raw}
          signal StatusBLESettingsFBD_Trunk_AdvertisingInterval: start 8, 16 bit, little-endian, data-type-policy=OVERRIDE, base-type=uint16, compu {phys=raw}, range phys 0..65532
          signal StatusBLESettingsFBD_Trunk_ConnectionInterval: start 24, 16 bit, little-endian, data-type-policy=OVERRIDE, base-type=uint16, compu {phys=raw}, range phys 0..65532
          signal StatusBLESettingsFBD_Trunk_IRKListID: start 40, 8 bit, little-endian, data-type-policy=OVERRIDE, compu {phys=raw}
          signal StatusBLESettingsFBD_Trunk_SettingsBLELELRMode: start 48, 8 bit, little-endian, data-type-policy=OVERRIDE, base-type=uint8, compu {phys=raw}, range phys 0..252
          signal StatusBLESettingsFBD_Trunk_LR500_AdvertisingInterval: start 56, 16 bit, little-endian, data-type-policy=OVERRIDE, base-type=uint16, compu {phys=raw}, range phys 0..65532
          signal StatusBLESettingsFBD_Trunk_LR125_AdvertisingInterval: start 72, 16 bit, little-endian, data-type-policy=OVERRIDE, base-type=uint16, compu {phys=raw}, range phys 0..65532
          signal StatusBLESettingsFBD_Trunk_ExtendedAdvertising: start 88, 8 bit, little-endian, data-type-policy=OVERRIDE, compu {phys=raw}
          signal StatusBLESettingsFBD_Trunk_TxPower: start 96, 8 bit, little-endian, data-type-policy=OVERRIDE, base-type=uint8, compu {phys=raw}, range phys 0..252
          signal StatusBLESettingsFBD_Trunk_PSM: start 104, 8 bit, little-endian, data-type-policy=OVERRIDE, base-type=uint8, compu {phys=raw}, range phys 0..252
          signal StatusBLESettingsFBD_Trunk_RPAFrequency: start 112, 8 bit, little-endian, data-type-policy=OVERRIDE, base-type=uint8, compu {phys=raw}, range phys 0..252
          signal StatusBLESettingsFBD_Trunk_DCKVersion: start 120, 8 bit, little-endian, data-type-policy=OVERRIDE, base-type=uint8, compu {phys=raw}, range phys 0..252
          signal StatusBLESettingsFBD_Trunk_ScanRequest: start 128, 8 bit, little-endian, data-type-policy=OVERRIDE, compu {phys=raw}
      frame StatusBLESettingsFBD_VL: id 0xD6, frame-length=20, can-addressing-mode=STANDARD, can-frame-rx-behavior=CAN-FD, can-frame-tx-behavior=CAN-FD
        pdu StatusBLESettingsFBD_VL: length=20, unused-bit-pattern=0
          signal StatusBLESettingsFBD_VL_BLEOperationMode: start 0, 8 bit, little-endian, data-type-policy=OVERRIDE, compu {phys=raw}
          signal StatusBLESettingsFBD_VL_AdvertisingInterval: start 8, 16 bit, little-endian, data-type-policy=OVERRIDE, base-type=uint16, compu {phys=raw}, range phys 0..65532
          signal StatusBLESettingsFBD_VL_ConnectionInterval: start 24, 16 bit, little-endian, data-type-policy=OVERRIDE, base-type=uint16, compu {phys=raw}, range phys 0..65532
          signal StatusBLESettingsFBD_VL_IRKListID: start 40, 8 bit, little-endian, data-type-policy=OVERRIDE, base-type=uint8, compu {phys=raw}, range phys 0..252
          signal StatusBLESettingsFBD_VL_SettingsBLELELRMode: start 48, 8 bit, little-endian, data-type-policy=OVERRIDE, compu {phys=raw}
          signal StatusBLESettingsFBD_VL_LR500_AdvertisingInterval: start 56, 16 bit, little-endian, data-type-policy=OVERRIDE, base-type=uint16, compu {phys=raw}, range phys 0..65532
          signal StatusBLESettingsFBD_VL_LR125_AdvertisingInterval: start 72, 16 bit, little-endian, data-type-policy=OVERRIDE, base-type=uint16, compu {phys=raw}, range phys 0..65532
          signal StatusBLESettingsFBD_VL_ExtendedAdvertising: start 88, 8 bit, little-endian, data-type-policy=OVERRIDE, compu {phys=raw}
          signal StatusBLESettingsFBD_VL_TxPower: start 96, 8 bit, little-endian, data-type-policy=OVERRIDE, base-type=uint8, compu {phys=raw}, range phys 0..252
          signal StatusBLESettingsFBD_VL_PSM: start 104, 8 bit, little-endian, data-type-policy=OVERRIDE, base-type=uint8, compu {phys=raw}, range phys 0..252
          signal StatusBLESettingsFBD_VL_RPAFrequency: start 112, 8 bit, little-endian, data-type-policy=OVERRIDE, base-type=uint8, compu {phys=raw}, range phys 0..252
          signal StatusBLESettingsFBD_VL_DCKVersion: start 120, 8 bit, little-endian, data-type-policy=OVERRIDE, base-type=uint8, compu {phys=raw}, range phys 0..252
          signal StatusBLESettingsFBD_VL_ScanRequest: start 128, 8 bit, little-endian, data-type-policy=OVERRIDE, compu {phys=raw}
      frame StatusBLESettingsFBD_VM: id 0xD2, frame-length=20, can-addressing-mode=STANDARD, can-frame-rx-behavior=CAN-FD, can-frame-tx-behavior=CAN-FD
        pdu StatusBLESettingsFBD_VM: length=20, unused-bit-pattern=0
          signal StatusBLESettingsFBD_VM_BLEOperationMode: start 0, 8 bit, little-endian, data-type-policy=OVERRIDE, compu {phys=raw}
          signal StatusBLESettingsFBD_VM_AdvertisingInterval: start 8, 16 bit, little-endian, data-type-policy=OVERRIDE, base-type=uint16, compu {phys=raw}, range phys 0..65532
          signal StatusBLESettingsFBD_VM_ConnectionInterval: start 24, 16 bit, little-endian, data-type-policy=OVERRIDE, base-type=uint16, compu {phys=raw}, range phys 0..65532
          signal StatusBLESettingsFBD_VM_IRKListID: start 40, 8 bit, little-endian, data-type-policy=OVERRIDE, compu {phys=raw}
          signal StatusBLESettingsFBD_VM_SettingsBLELELRMode: start 48, 8 bit, little-endian, data-type-policy=OVERRIDE, compu {phys=raw}
          signal StatusBLESettingsFBD_VM_LR500_AdvertisingInterval: start 56, 16 bit, little-endian, data-type-policy=OVERRIDE, base-type=uint16, compu {phys=raw}, range phys 0..65532
          signal StatusBLESettingsFBD_VM_LR125_AdvertisingInterval: start 72, 16 bit, little-endian, data-type-policy=OVERRIDE, base-type=uint16, compu {phys=raw}, range phys 0..65532
          signal StatusBLESettingsFBD_VM_ExtendedAdvertising: start 88, 8 bit, little-endian, data-type-policy=OVERRIDE, compu {phys=raw}
          signal StatusBLESettingsFBD_VM_TxPower: start 96, 8 bit, little-endian, data-type-policy=OVERRIDE, base-type=uint8, compu {phys=raw}, range phys 0..252
          signal StatusBLESettingsFBD_VM_PSM: start 104, 8 bit, little-endian, data-type-policy=OVERRIDE, base-type=uint8, compu {phys=raw}, range phys 0..252
          signal StatusBLESettingsFBD_VM_RPAFrequency: start 112, 8 bit, little-endian, data-type-policy=OVERRIDE, base-type=uint8, compu {phys=raw}, range phys 0..252
          signal StatusBLESettingsFBD_VM_DCKVersion: start 120, 8 bit, little-endian, data-type-policy=OVERRIDE, base-type=uint8, compu {phys=raw}, range phys 0..252
          signal StatusBLESettingsFBD_VM_ScanRequest: start 128, 8 bit, little-endian, data-type-policy=OVERRIDE, compu {phys=raw}
      frame StatusBLESettingsFBD_VR: id 0xD7, frame-length=20, can-addressing-mode=STANDARD, can-frame-rx-behavior=CAN-FD, can-frame-tx-behavior=CAN-FD
        pdu StatusBLESettingsFBD_VR: length=20, unused-bit-pattern=0
          signal StatusBLESettingsFBD_VR_BLEOperationMode: start 0, 8 bit, little-endian, data-type-policy=OVERRIDE, compu {phys=raw}
          signal StatusBLESettingsFBD_VR_AdvertisingInterval: start 8, 16 bit, little-endian, data-type-policy=OVERRIDE, base-type=uint16, compu {phys=raw}, range phys 0..65532
          signal StatusBLESettingsFBD_VR_ConnectionInterval: start 24, 16 bit, little-endian, data-type-policy=OVERRIDE, base-type=uint16, compu {phys=raw}, range phys 0..65532
          signal StatusBLESettingsFBD_VR_IRKListID: start 40, 8 bit, little-endian, data-type-policy=OVERRIDE, compu {phys=raw}
          signal StatusBLESettingsFBD_VR_SettingsBLELELRMode: start 48, 8 bit, little-endian, data-type-policy=OVERRIDE, compu {phys=raw}
          signal StatusBLESettingsFBD_VR_LR500_AdvertisingInterval: start 56, 16 bit, little-endian, data-type-policy=OVERRIDE, base-type=uint16, compu {phys=raw}, range phys 0..65532
          signal StatusBLESettingsFBD_VR_LR125_AdvertisingInterval: start 72, 16 bit, little-endian, data-type-policy=OVERRIDE, base-type=uint16, compu {phys=raw}, range phys 0..65532
          signal StatusBLESettingsFBD_VR_ExtendedAdvertising: start 88, 8 bit, little-endian, data-type-policy=OVERRIDE, compu {phys=raw}
          signal StatusBLESettingsFBD_VR_TxPower: start 96, 8 bit, little-endian, data-type-policy=OVERRIDE, base-type=uint8, compu {phys=raw}, range phys 0..252
          signal StatusBLESettingsFBD_VR_PSM: start 104, 8 bit, little-endian, data-type-policy=OVERRIDE, base-type=uint8, compu {phys=raw}, range phys 0..252
          signal StatusBLESettingsFBD_VR_RPAFrequency: start 112, 8 bit, little-endian, data-type-policy=OVERRIDE, base-type=uint8, compu {phys=raw}, range phys 0..252
          signal StatusBLESettingsFBD_VR_DCKVersion: start 120, 8 bit, little-endian, data-type-policy=OVERRIDE, base-type=uint8, compu {phys=raw}, range phys 0..252
          signal StatusBLESettingsFBD_VR_ScanRequest: start 128, 8 bit, little-endian, data-type-policy=OVERRIDE, compu {phys=raw}
      frame StatusBLESettingsPriorityFBD_HL: id 0x18C, frame-length=20, can-addressing-mode=STANDARD, can-frame-rx-behavior=CAN-FD, can-frame-tx-behavior=CAN-FD
        pdu StatusBLESettingsPriorityFBD_HL: length=20, unused-bit-pattern=0
          signal StatusBLESettingsPriorityFBD_HL_NumberActiveConnections: start 0, 8 bit, little-endian, data-type-policy=OVERRIDE, base-type=uint8, compu {phys=raw}, range phys 0..252
          signal StatusBLESettingsPriorityFBD_HL_ConnectionID1: start 8, 8 bit, little-endian, data-type-policy=OVERRIDE, base-type=uint8, compu {phys=raw}, range phys 0..252
          signal StatusBLESettingsPriorityFBD_HL_Level1: start 16, 8 bit, little-endian, data-type-policy=OVERRIDE, compu {phys=raw}
          signal StatusBLESettingsPriorityFBD_HL_ConnectionID2: start 24, 8 bit, little-endian, data-type-policy=OVERRIDE, base-type=uint8, compu {phys=raw}, range phys 0..252
          signal StatusBLESettingsPriorityFBD_HL_Level2: start 32, 8 bit, little-endian, data-type-policy=OVERRIDE, compu {phys=raw}
          signal StatusBLESettingsPriorityFBD_HL_ConnectionID3: start 40, 8 bit, little-endian, data-type-policy=OVERRIDE, base-type=uint8, compu {phys=raw}, range phys 0..252
          signal StatusBLESettingsPriorityFBD_HL_Level3: start 48, 8 bit, little-endian, data-type-policy=OVERRIDE, compu {phys=raw}
          signal StatusBLESettingsPriorityFBD_HL_ConnectionID4: start 56, 8 bit, little-endian, data-type-policy=OVERRIDE, base-type=uint8, compu {phys=raw}, range phys 0..252
          signal StatusBLESettingsPriorityFBD_HL_Level4: start 64, 8 bit, little-endian, data-type-policy=OVERRIDE, compu {phys=raw}
          signal StatusBLESettingsPriorityFBD_HL_ConnectionID5: start 72, 8 bit, little-endian, data-type-policy=OVERRIDE, base-type=uint8, compu {phys=raw}, range phys 0..252
          signal StatusBLESettingsPriorityFBD_HL_Level5: start 80, 8 bit, little-endian, data-type-policy=OVERRIDE, compu {phys=raw}
          signal StatusBLESettingsPriorityFBD_HL_ConnectionID6: start 88, 8 bit, little-endian, data-type-policy=OVERRIDE, base-type=uint8, compu {phys=raw}, range phys 0..252
          signal StatusBLESettingsPriorityFBD_HL_Level6: start 96, 8 bit, little-endian, data-type-policy=OVERRIDE, compu {phys=raw}
          signal StatusBLESettingsPriorityFBD_HL_ConnectionID7: start 104, 8 bit, little-endian, data-type-policy=OVERRIDE, base-type=uint8, compu {phys=raw}, range phys 0..252
          signal StatusBLESettingsPriorityFBD_HL_Level7: start 112, 8 bit, little-endian, data-type-policy=OVERRIDE, compu {phys=raw}
          signal StatusBLESettingsPriorityFBD_HL_ConnectionID8: start 120, 8 bit, little-endian, data-type-policy=OVERRIDE, base-type=uint8, compu {phys=raw}, range phys 0..252
          signal StatusBLESettingsPriorityFBD_HL_Level8: start 128, 8 bit, little-endian, data-type-policy=OVERRIDE, compu {phys=raw}
      frame StatusBLESettingsPriorityFBD_HM: id 0x187, frame-length=20, can-addressing-mode=STANDARD, can-frame-rx-behavior=CAN-FD, can-frame-tx-behavior=CAN-FD
        pdu StatusBLESettingsPriorityFBD_HM: length=20, unused-bit-pattern=0
          signal StatusBLESettingsPriorityFBD_HM_NumberActiveConnections: start 0, 8 bit, little-endian, data-type-policy=OVERRIDE, base-type=uint8, compu {phys=raw}, range phys 0..252
          signal StatusBLESettingsPriorityFBD_HM_ConnectionID1: start 8, 8 bit, little-endian, data-type-policy=OVERRIDE, base-type=uint8, compu {phys=raw}, range phys 0..252
          signal StatusBLESettingsPriorityFBD_HM_Level1: start 16, 8 bit, little-endian, data-type-policy=OVERRIDE, compu {phys=raw}
          signal StatusBLESettingsPriorityFBD_HM_ConnectionID2: start 24, 8 bit, little-endian, data-type-policy=OVERRIDE, base-type=uint8, compu {phys=raw}, range phys 0..252
          signal StatusBLESettingsPriorityFBD_HM_Level2: start 32, 8 bit, little-endian, data-type-policy=OVERRIDE, compu {phys=raw}
          signal StatusBLESettingsPriorityFBD_HM_ConnectionID3: start 40, 8 bit, little-endian, data-type-policy=OVERRIDE, base-type=uint8, compu {phys=raw}, range phys 0..252
          signal StatusBLESettingsPriorityFBD_HM_Level3: start 48, 8 bit, little-endian, data-type-policy=OVERRIDE, compu {phys=raw}
          signal StatusBLESettingsPriorityFBD_HM_ConnectionID4: start 56, 8 bit, little-endian, data-type-policy=OVERRIDE, base-type=uint8, compu {phys=raw}, range phys 0..252
          signal StatusBLESettingsPriorityFBD_HM_Level4: start 64, 8 bit, little-endian, data-type-policy=OVERRIDE, compu {phys=raw}
          signal StatusBLESettingsPriorityFBD_HM_ConnectionID5: start 72, 8 bit, little-endian, data-type-policy=OVERRIDE, base-type=uint8, compu {phys=raw}, range phys 0..252
          signal StatusBLESettingsPriorityFBD_HM_Level5: start 80, 8 bit, little-endian, data-type-policy=OVERRIDE, compu {phys=raw}
          signal StatusBLESettingsPriorityFBD_HM_ConnectionID6: start 88, 8 bit, little-endian, data-type-policy=OVERRIDE, base-type=uint8, compu {phys=raw}, range phys 0..252
          signal StatusBLESettingsPriorityFBD_HM_Level6: start 96, 8 bit, little-endian, data-type-policy=OVERRIDE, compu {phys=raw}
          signal StatusBLESettingsPriorityFBD_HM_ConnectionID7: start 104, 8 bit, little-endian, data-type-policy=OVERRIDE, base-type=uint8, compu {phys=raw}, range phys 0..252
          signal StatusBLESettingsPriorityFBD_HM_Level7: start 112, 8 bit, little-endian, data-type-policy=OVERRIDE, compu {phys=raw}
          signal StatusBLESettingsPriorityFBD_HM_ConnectionID8: start 120, 8 bit, little-endian, data-type-policy=OVERRIDE, base-type=uint8, compu {phys=raw}, range phys 0..252
          signal StatusBLESettingsPriorityFBD_HM_Level8: start 128, 8 bit, little-endian, data-type-policy=OVERRIDE, compu {phys=raw}
      frame StatusBLESettingsPriorityFBD_HR: id 0x18D, frame-length=20, can-addressing-mode=STANDARD, can-frame-rx-behavior=CAN-FD, can-frame-tx-behavior=CAN-FD
        pdu StatusBLESettingsPriorityFBD_HR: length=20, unused-bit-pattern=0
          signal StatusBLESettingsPriorityFBD_HR_NumberActiveConnections: start 0, 8 bit, little-endian, data-type-policy=OVERRIDE, base-type=uint8, compu {phys=raw}, range phys 0..252
          signal StatusBLESettingsPriorityFBD_HR_ConnectionID1: start 8, 8 bit, little-endian, data-type-policy=OVERRIDE, base-type=uint8, compu {phys=raw}, range phys 0..252
          signal StatusBLESettingsPriorityFBD_HR_Level1: start 16, 8 bit, little-endian, data-type-policy=OVERRIDE, compu {phys=raw}
          signal StatusBLESettingsPriorityFBD_HR_ConnectionID2: start 24, 8 bit, little-endian, data-type-policy=OVERRIDE, base-type=uint8, compu {phys=raw}, range phys 0..252
          signal StatusBLESettingsPriorityFBD_HR_Level2: start 32, 8 bit, little-endian, data-type-policy=OVERRIDE, compu {phys=raw}
          signal StatusBLESettingsPriorityFBD_HR_ConnectionID3: start 40, 8 bit, little-endian, data-type-policy=OVERRIDE, base-type=uint8, compu {phys=raw}, range phys 0..252
          signal StatusBLESettingsPriorityFBD_HR_Level3: start 48, 8 bit, little-endian, data-type-policy=OVERRIDE, compu {phys=raw}
          signal StatusBLESettingsPriorityFBD_HR_ConnectionID4: start 56, 8 bit, little-endian, data-type-policy=OVERRIDE, base-type=uint8, compu {phys=raw}, range phys 0..252
          signal StatusBLESettingsPriorityFBD_HR_Level4: start 64, 8 bit, little-endian, data-type-policy=OVERRIDE, compu {phys=raw}
          signal StatusBLESettingsPriorityFBD_HR_ConnectionID5: start 72, 8 bit, little-endian, data-type-policy=OVERRIDE, base-type=uint8, compu {phys=raw}, range phys 0..252
          signal StatusBLESettingsPriorityFBD_HR_Level5: start 80, 8 bit, little-endian, data-type-policy=OVERRIDE, compu {phys=raw}
          signal StatusBLESettingsPriorityFBD_HR_ConnectionID6: start 88, 8 bit, little-endian, data-type-policy=OVERRIDE, base-type=uint8, compu {phys=raw}, range phys 0..252
          signal StatusBLESettingsPriorityFBD_HR_Level6: start 96, 8 bit, little-endian, data-type-policy=OVERRIDE, compu {phys=raw}
          signal StatusBLESettingsPriorityFBD_HR_ConnectionID7: start 104, 8 bit, little-endian, data-type-policy=OVERRIDE, base-type=uint8, compu {phys=raw}, range phys 0..252
          signal StatusBLESettingsPriorityFBD_HR_Level7: start 112, 8 bit, little-endian, data-type-policy=OVERRIDE, compu {phys=raw}
          signal StatusBLESettingsPriorityFBD_HR_ConnectionID8: start 120, 8 bit, little-endian, data-type-policy=OVERRIDE, base-type=uint8, compu {phys=raw}, range phys 0..252
          signal StatusBLESettingsPriorityFBD_HR_Level8: start 128, 8 bit, little-endian, data-type-policy=OVERRIDE, compu {phys=raw}
      frame StatusBLESettingsPriorityFBD_Miko: id 0x188, frame-length=20, can-addressing-mode=STANDARD, can-frame-rx-behavior=CAN-FD, can-frame-tx-behavior=CAN-FD
        pdu StatusBLESettingsPriorityFBD_Miko: length=20, unused-bit-pattern=0
          signal StatusBLESettingsPriorityFBD_Miko_NumberActiveConnections: start 0, 8 bit, little-endian, data-type-policy=OVERRIDE, base-type=uint8, compu {phys=raw}, range phys 0..252
          signal StatusBLESettingsPriorityFBD_Miko_ConnectionID1: start 8, 8 bit, little-endian, data-type-policy=OVERRIDE, base-type=uint8, compu {phys=raw}, range phys 0..252
          signal StatusBLESettingsPriorityFBD_Miko_Level1: start 16, 8 bit, little-endian, data-type-policy=OVERRIDE, compu {phys=raw}
          signal StatusBLESettingsPriorityFBD_Miko_ConnectionID2: start 24, 8 bit, little-endian, data-type-policy=OVERRIDE, base-type=uint8, compu {phys=raw}, range phys 0..252
          signal StatusBLESettingsPriorityFBD_Miko_Level2: start 32, 8 bit, little-endian, data-type-policy=OVERRIDE, compu {phys=raw}
          signal StatusBLESettingsPriorityFBD_Miko_ConnectionID3: start 40, 8 bit, little-endian, data-type-policy=OVERRIDE, base-type=uint8, compu {phys=raw}, range phys 0..252
          signal StatusBLESettingsPriorityFBD_Miko_Level3: start 48, 8 bit, little-endian, data-type-policy=OVERRIDE, compu {phys=raw}
          signal StatusBLESettingsPriorityFBD_Miko_ConnectionID4: start 56, 8 bit, little-endian, data-type-policy=OVERRIDE, base-type=uint8, compu {phys=raw}, range phys 0..252
          signal StatusBLESettingsPriorityFBD_Miko_Level4: start 64, 8 bit, little-endian, data-type-policy=OVERRIDE, compu {phys=raw}
          signal StatusBLESettingsPriorityFBD_Miko_ConnectionID5: start 72, 8 bit, little-endian, data-type-policy=OVERRIDE, base-type=uint8, compu {phys=raw}, range phys 0..252
          signal StatusBLESettingsPriorityFBD_Miko_Level5: start 80, 8 bit, little-endian, data-type-policy=OVERRIDE, compu {phys=raw}
          signal StatusBLESettingsPriorityFBD_Miko_ConnectionID6: start 88, 8 bit, little-endian, data-type-policy=OVERRIDE, base-type=uint8, compu {phys=raw}, range phys 0..252
          signal StatusBLESettingsPriorityFBD_Miko_Level6: start 96, 8 bit, little-endian, data-type-policy=OVERRIDE, compu {phys=raw}
          signal StatusBLESettingsPriorityFBD_Miko_ConnectionID7: start 104, 8 bit, little-endian, data-type-policy=OVERRIDE, base-type=uint8, compu {phys=raw}, range phys 0..252
          signal StatusBLESettingsPriorityFBD_Miko_Level7: start 112, 8 bit, little-endian, data-type-policy=OVERRIDE, compu {phys=raw}
          signal StatusBLESettingsPriorityFBD_Miko_ConnectionID8: start 120, 8 bit, little-endian, data-type-policy=OVERRIDE, base-type=uint8, compu {phys=raw}, range phys 0..252
          signal StatusBLESettingsPriorityFBD_Miko_Level8: start 128, 8 bit, little-endian, data-type-policy=OVERRIDE, compu {phys=raw}
      frame StatusBLESettingsPriorityFBD_MM: id 0x337, frame-length=20, can-addressing-mode=STANDARD, can-frame-rx-behavior=CAN-FD, can-frame-tx-behavior=CAN-FD
        pdu StatusBLESettingsPriorityFBD_MM: length=20, unused-bit-pattern=0
          signal StatusBLESettingsPriorityFBD_MM_NumberActiveConnections: start 0, 8 bit, little-endian, data-type-policy=OVERRIDE, base-type=uint8, compu {phys=raw}, range phys 0..252
          signal StatusBLESettingsPriorityFBD_MM_ConnectionID1: start 8, 8 bit, little-endian, data-type-policy=OVERRIDE, base-type=uint8, compu {phys=raw}, range phys 0..252
          signal StatusBLESettingsPriorityFBD_MM_Level1: start 16, 8 bit, little-endian, data-type-policy=OVERRIDE, compu {phys=raw}
          signal StatusBLESettingsPriorityFBD_MM_ConnectionID2: start 24, 8 bit, little-endian, data-type-policy=OVERRIDE, base-type=uint8, compu {phys=raw}, range phys 0..252
          signal StatusBLESettingsPriorityFBD_MM_Level2: start 32, 8 bit, little-endian, data-type-policy=OVERRIDE, compu {phys=raw}
          signal StatusBLESettingsPriorityFBD_MM_ConnectionID3: start 40, 8 bit, little-endian, data-type-policy=OVERRIDE, base-type=uint8, compu {phys=raw}, range phys 0..252
          signal StatusBLESettingsPriorityFBD_MM_Level3: start 48, 8 bit, little-endian, data-type-policy=OVERRIDE, compu {phys=raw}
          signal StatusBLESettingsPriorityFBD_MM_ConnectionID4: start 56, 8 bit, little-endian, data-type-policy=OVERRIDE, base-type=uint8, compu {phys=raw}, range phys 0..252
          signal StatusBLESettingsPriorityFBD_MM_Level4: start 64, 8 bit, little-endian, data-type-policy=OVERRIDE, compu {phys=raw}
          signal StatusBLESettingsPriorityFBD_MM_ConnectionID5: start 72, 8 bit, little-endian, data-type-policy=OVERRIDE, base-type=uint8, compu {phys=raw}, range phys 0..252
          signal StatusBLESettingsPriorityFBD_MM_Level5: start 80, 8 bit, little-endian, data-type-policy=OVERRIDE, compu {phys=raw}
          signal StatusBLESettingsPriorityFBD_MM_ConnectionID6: start 88, 8 bit, little-endian, data-type-policy=OVERRIDE, base-type=uint8, compu {phys=raw}, range phys 0..252
          signal StatusBLESettingsPriorityFBD_MM_Level6: start 96, 8 bit, little-endian, data-type-policy=OVERRIDE, compu {phys=raw}
          signal StatusBLESettingsPriorityFBD_MM_ConnectionID7: start 104, 8 bit, little-endian, data-type-policy=OVERRIDE, base-type=uint8, compu {phys=raw}, range phys 0..252
          signal StatusBLESettingsPriorityFBD_MM_Level7: start 112, 8 bit, little-endian, data-type-policy=OVERRIDE, compu {phys=raw}
          signal StatusBLESettingsPriorityFBD_MM_ConnectionID8: start 120, 8 bit, little-endian, data-type-policy=OVERRIDE, base-type=uint8, compu {phys=raw}, range phys 0..252
          signal StatusBLESettingsPriorityFBD_MM_Level8: start 128, 8 bit, little-endian, data-type-policy=OVERRIDE, compu {phys=raw}
      frame StatusBLESettingsPriorityFBD_Trunk: id 0x189, frame-length=20, can-addressing-mode=STANDARD, can-frame-rx-behavior=CAN-FD, can-frame-tx-behavior=CAN-FD
        pdu StatusBLESettingsPriorityFBD_Trunk: length=20, unused-bit-pattern=0
          signal StatusBLESettingsPriorityFBD_Trunk_NumberActiveConnections: start 0, 8 bit, little-endian, data-type-policy=OVERRIDE, base-type=uint8, compu {phys=raw}, range phys 0..252
          signal StatusBLESettingsPriorityFBD_Trunk_ConnectionID1: start 8, 8 bit, little-endian, data-type-policy=OVERRIDE, base-type=uint8, compu {phys=raw}, range phys 0..252
          signal StatusBLESettingsPriorityFBD_Trunk_Level1: start 16, 8 bit, little-endian, data-type-policy=OVERRIDE, compu {phys=raw}
          signal StatusBLESettingsPriorityFBD_Trunk_ConnectionID2: start 24, 8 bit, little-endian, data-type-policy=OVERRIDE, base-type=uint8, compu {phys=raw}, range phys 0..252
          signal StatusBLESettingsPriorityFBD_Trunk_Level2: start 32, 8 bit, little-endian, data-type-policy=OVERRIDE, compu {phys=raw}
          signal StatusBLESettingsPriorityFBD_Trunk_ConnectionID3: start 40, 8 bit, little-endian, data-type-policy=OVERRIDE, base-type=uint8, compu {phys=raw}, range phys 0..252
          signal StatusBLESettingsPriorityFBD_Trunk_Level3: start 48, 8 bit, little-endian, data-type-policy=OVERRIDE, compu {phys=raw}
          signal StatusBLESettingsPriorityFBD_Trunk_ConnectionID4: start 56, 8 bit, little-endian, data-type-policy=OVERRIDE, base-type=uint8, compu {phys=raw}, range phys 0..252
          signal StatusBLESettingsPriorityFBD_Trunk_Level4: start 64, 8 bit, little-endian, data-type-policy=OVERRIDE, compu {phys=raw}
          signal StatusBLESettingsPriorityFBD_Trunk_ConnectionID5: start 72, 8 bit, little-endian, data-type-policy=OVERRIDE, base-type=uint8, compu {phys=raw}, range phys 0..252
          signal StatusBLESettingsPriorityFBD_Trunk_Level5: start 80, 8 bit, little-endian, data-type-policy=OVERRIDE, compu {phys=raw}
          signal StatusBLESettingsPriorityFBD_Trunk_ConnectionID6: start 88, 8 bit, little-endian, data-type-policy=OVERRIDE, base-type=uint8, compu {phys=raw}, range phys 0..252
          signal StatusBLESettingsPriorityFBD_Trunk_Level6: start 96, 8 bit, little-endian, data-type-policy=OVERRIDE, compu {phys=raw}
          signal StatusBLESettingsPriorityFBD_Trunk_ConnectionID7: start 104, 8 bit, little-endian, data-type-policy=OVERRIDE, base-type=uint8, compu {phys=raw}, range phys 0..252
          signal StatusBLESettingsPriorityFBD_Trunk_Level7: start 112, 8 bit, little-endian, data-type-policy=OVERRIDE, compu {phys=raw}
          signal StatusBLESettingsPriorityFBD_Trunk_ConnectionID8: start 120, 8 bit, little-endian, data-type-policy=OVERRIDE, base-type=uint8, compu {phys=raw}, range phys 0..252
          signal StatusBLESettingsPriorityFBD_Trunk_Level8: start 128, 8 bit, little-endian, data-type-policy=OVERRIDE, compu {phys=raw}
      frame StatusBLESettingsPriorityFBD_VL: id 0x18A, frame-length=20, can-addressing-mode=STANDARD, can-frame-rx-behavior=CAN-FD, can-frame-tx-behavior=CAN-FD
        pdu StatusBLESettingsPriorityFBD_VL: length=20, unused-bit-pattern=0
          signal StatusBLESettingsPriorityFBD_VL_NumberActiveConnections: start 0, 8 bit, little-endian, data-type-policy=OVERRIDE, base-type=uint8, compu {phys=raw}, range phys 0..252
          signal StatusBLESettingsPriorityFBD_VL_ConnectionID1: start 8, 8 bit, little-endian, data-type-policy=OVERRIDE, base-type=uint8, compu {phys=raw}, range phys 0..252
          signal StatusBLESettingsPriorityFBD_VL_Level1: start 16, 8 bit, little-endian, data-type-policy=OVERRIDE, compu {phys=raw}
          signal StatusBLESettingsPriorityFBD_VL_ConnectionID2: start 24, 8 bit, little-endian, data-type-policy=OVERRIDE, base-type=uint8, compu {phys=raw}, range phys 0..252
          signal StatusBLESettingsPriorityFBD_VL_Level2: start 32, 8 bit, little-endian, data-type-policy=OVERRIDE, compu {phys=raw}
          signal StatusBLESettingsPriorityFBD_VL_ConnectionID3: start 40, 8 bit, little-endian, data-type-policy=OVERRIDE, base-type=uint8, compu {phys=raw}, range phys 0..252
          signal StatusBLESettingsPriorityFBD_VL_Level3: start 48, 8 bit, little-endian, data-type-policy=OVERRIDE, compu {phys=raw}
          signal StatusBLESettingsPriorityFBD_VL_ConnectionID4: start 56, 8 bit, little-endian, data-type-policy=OVERRIDE, base-type=uint8, compu {phys=raw}, range phys 0..252
          signal StatusBLESettingsPriorityFBD_VL_Level4: start 64, 8 bit, little-endian, data-type-policy=OVERRIDE, compu {phys=raw}
          signal StatusBLESettingsPriorityFBD_VL_ConnectionID5: start 72, 8 bit, little-endian, data-type-policy=OVERRIDE, base-type=uint8, compu {phys=raw}, range phys 0..252
          signal StatusBLESettingsPriorityFBD_VL_Level5: start 80, 8 bit, little-endian, data-type-policy=OVERRIDE, compu {phys=raw}
          signal StatusBLESettingsPriorityFBD_VL_ConnectionID6: start 88, 8 bit, little-endian, data-type-policy=OVERRIDE, base-type=uint8, compu {phys=raw}, range phys 0..252
          signal StatusBLESettingsPriorityFBD_VL_Level6: start 96, 8 bit, little-endian, data-type-policy=OVERRIDE, compu {phys=raw}
          signal StatusBLESettingsPriorityFBD_VL_ConnectionID7: start 104, 8 bit, little-endian, data-type-policy=OVERRIDE, base-type=uint8, compu {phys=raw}, range phys 0..252
          signal StatusBLESettingsPriorityFBD_VL_Level7: start 112, 8 bit, little-endian, data-type-policy=OVERRIDE, compu {phys=raw}
          signal StatusBLESettingsPriorityFBD_VL_ConnectionID8: start 120, 8 bit, little-endian, data-type-policy=OVERRIDE, base-type=uint8, compu {phys=raw}, range phys 0..252
          signal StatusBLESettingsPriorityFBD_VL_Level8: start 128, 8 bit, little-endian, data-type-policy=OVERRIDE, compu {phys=raw}
      frame StatusBLESettingsPriorityFBD_VM: id 0x186, frame-length=20, can-addressing-mode=STANDARD, can-frame-rx-behavior=CAN-FD, can-frame-tx-behavior=CAN-FD
        pdu StatusBLESettingsPriorityFBD_VM: length=20, unused-bit-pattern=0
          signal StatusBLESettingsPriorityFBD_VM_NumberActiveConnections: start 0, 8 bit, little-endian, data-type-policy=OVERRIDE, base-type=uint8, compu {phys=raw}, range phys 0..252
          signal StatusBLESettingsPriorityFBD_VM_ConnectionID1: start 8, 8 bit, little-endian, data-type-policy=OVERRIDE, base-type=uint8, compu {phys=raw}, range phys 0..252
          signal StatusBLESettingsPriorityFBD_VM_Level1: start 16, 8 bit, little-endian, data-type-policy=OVERRIDE, compu {phys=raw}
          signal StatusBLESettingsPriorityFBD_VM_ConnectionID2: start 24, 8 bit, little-endian, data-type-policy=OVERRIDE, base-type=uint8, compu {phys=raw}, range phys 0..252
          signal StatusBLESettingsPriorityFBD_VM_Level2: start 32, 8 bit, little-endian, data-type-policy=OVERRIDE, compu {phys=raw}
          signal StatusBLESettingsPriorityFBD_VM_ConnectionID3: start 40, 8 bit, little-endian, data-type-policy=OVERRIDE, base-type=uint8, compu {phys=raw}, range phys 0..252
          signal StatusBLESettingsPriorityFBD_VM_Level3: start 48, 8 bit, little-endian, data-type-policy=OVERRIDE, compu {phys=raw}
          signal StatusBLESettingsPriorityFBD_VM_ConnectionID4: start 56, 8 bit, little-endian, data-type-policy=OVERRIDE, base-type=uint8, compu {phys=raw}, range phys 0..252
          signal StatusBLESettingsPriorityFBD_VM_Level4: start 64, 8 bit, little-endian, data-type-policy=OVERRIDE, compu {phys=raw}
          signal StatusBLESettingsPriorityFBD_VM_ConnectionID5: start 72, 8 bit, little-endian, data-type-policy=OVERRIDE, base-type=uint8, compu {phys=raw}, range phys 0..252
          signal StatusBLESettingsPriorityFBD_VM_Level5: start 80, 8 bit, little-endian, data-type-policy=OVERRIDE, compu {phys=raw}
          signal StatusBLESettingsPriorityFBD_VM_ConnectionID6: start 88, 8 bit, little-endian, data-type-policy=OVERRIDE, base-type=uint8, compu {phys=raw}, range phys 0..252
          signal StatusBLESettingsPriorityFBD_VM_Level6: start 96, 8 bit, little-endian, data-type-policy=OVERRIDE, compu {phys=raw}
          signal StatusBLESettingsPriorityFBD_VM_ConnectionID7: start 104, 8 bit, little-endian, data-type-policy=OVERRIDE, base-type=uint8, compu {phys=raw}, range phys 0..252
          signal StatusBLESettingsPriorityFBD_VM_Level7: start 112, 8 bit, little-endian, data-type-policy=OVERRIDE, compu {phys=raw}
          signal StatusBLESettingsPriorityFBD_VM_ConnectionID8: start 120, 8 bit, little-endian, data-type-policy=OVERRIDE, base-type=uint8, compu {phys=raw}, range phys 0..252
          signal StatusBLESettingsPriorityFBD_VM_Level8: start 128, 8 bit, little-endian, data-type-policy=OVERRIDE, compu {phys=raw}
      frame StatusBLESettingsPriorityFBD_VR: id 0x18B, frame-length=20, can-addressing-mode=STANDARD, can-frame-rx-behavior=CAN-FD, can-frame-tx-behavior=CAN-FD
        pdu StatusBLESettingsPriorityFBD_VR: length=20, unused-bit-pattern=0
          signal StatusBLESettingsPriorityFBD_VR_NumberActiveConnections: start 0, 8 bit, little-endian, data-type-policy=OVERRIDE, base-type=uint8, compu {phys=raw}, range phys 0..252
          signal StatusBLESettingsPriorityFBD_VR_ConnectionID1: start 8, 8 bit, little-endian, data-type-policy=OVERRIDE, base-type=uint8, compu {phys=raw}, range phys 0..252
          signal StatusBLESettingsPriorityFBD_VR_Level1: start 16, 8 bit, little-endian, data-type-policy=OVERRIDE, compu {phys=raw}
          signal StatusBLESettingsPriorityFBD_VR_ConnectionID2: start 24, 8 bit, little-endian, data-type-policy=OVERRIDE, base-type=uint8, compu {phys=raw}, range phys 0..252
          signal StatusBLESettingsPriorityFBD_VR_Level2: start 32, 8 bit, little-endian, data-type-policy=OVERRIDE, compu {phys=raw}
          signal StatusBLESettingsPriorityFBD_VR_ConnectionID3: start 40, 8 bit, little-endian, data-type-policy=OVERRIDE, base-type=uint8, compu {phys=raw}, range phys 0..252
          signal StatusBLESettingsPriorityFBD_VR_Level3: start 48, 8 bit, little-endian, data-type-policy=OVERRIDE, compu {phys=raw}
          signal StatusBLESettingsPriorityFBD_VR_ConnectionID4: start 56, 8 bit, little-endian, data-type-policy=OVERRIDE, base-type=uint8, compu {phys=raw}, range phys 0..252
          signal StatusBLESettingsPriorityFBD_VR_Level4: start 64, 8 bit, little-endian, data-type-policy=OVERRIDE, compu {phys=raw}
          signal StatusBLESettingsPriorityFBD_VR_ConnectionID5: start 72, 8 bit, little-endian, data-type-policy=OVERRIDE, base-type=uint8, compu {phys=raw}, range phys 0..252
          signal StatusBLESettingsPriorityFBD_VR_Level5: start 80, 8 bit, little-endian, data-type-policy=OVERRIDE, compu {phys=raw}
          signal StatusBLESettingsPriorityFBD_VR_ConnectionID6: start 88, 8 bit, little-endian, data-type-policy=OVERRIDE, base-type=uint8, compu {phys=raw}, range phys 0..252
          signal StatusBLESettingsPriorityFBD_VR_Level6: start 96, 8 bit, little-endian, data-type-policy=OVERRIDE, compu {phys=raw}
          signal StatusBLESettingsPriorityFBD_VR_ConnectionID7: start 104, 8 bit, little-endian, data-type-policy=OVERRIDE, base-type=uint8, compu {phys=raw}, range phys 0..252
          signal StatusBLESettingsPriorityFBD_VR_Level7: start 112, 8 bit, little-endian, data-type-policy=OVERRIDE, compu {phys=raw}
          signal StatusBLESettingsPriorityFBD_VR_ConnectionID8: start 120, 8 bit, little-endian, data-type-policy=OVERRIDE, base-type=uint8, compu {phys=raw}, range phys 0..252
          signal StatusBLESettingsPriorityFBD_VR_Level8: start 128, 8 bit, little-endian, data-type-policy=OVERRIDE, compu {phys=raw}
      frame StatusConfigurationFBD_HL: id 0x268, frame-length=16, can-addressing-mode=STANDARD, can-frame-rx-behavior=CAN-FD, can-frame-tx-behavior=CAN-FD
        pdu StatusConfigurationFBD_HL: length=16, unused-bit-pattern=0
          signal StatusConfigurationFBD_HL_UWBAntenna: start 0, 8 bit, little-endian, data-type-policy=OVERRIDE, base-type=uint8, compu {phys=raw}, range phys 0..252
          signal StatusConfigurationFBD_HL_UWBDutyCycleLimitSec: start 8, 8 bit, little-endian, data-type-policy=OVERRIDE, base-type=uint8, compu {phys=raw*0.5; unit ms}, range phys 0..126
          signal StatusConfigurationFBD_HL_UWBDutyCycleLimitHour: start 16, 8 bit, little-endian, data-type-policy=OVERRIDE, base-type=uint8, compu {phys=raw*0.1; unit s}, range phys 0..25.2
          signal StatusConfigurationFBD_HL_UWBDutyCycleLimitOffMeanSec: start 24, 8 bit, little-endian, data-type-policy=OVERRIDE, base-type=uint8, compu {phys=raw*0.5; unit ms}, range phys 0..126
          signal StatusConfigurationFBD_HL_FBDonlyWUT: start 32, 8 bit, little-endian, data-type-policy=OVERRIDE, base-type=uint8, compu {phys=raw*0.1; unit m}, range phys 0..25.2
          signal StatusConfigurationFBD_HL_FBDonlyRIT: start 40, 8 bit, little-endian, data-type-policy=OVERRIDE, compu {phys=raw}
          signal StatusConfigurationFBD_HL_FBDonlyRSU: start 48, 8 bit, little-endian, data-type-policy=OVERRIDE, base-type=uint8, compu {phys=raw; unit s}, range phys 0..252
          signal StatusConfigurationFBD_HL_FBDonlyRSE: start 56, 8 bit, little-endian, data-type-policy=OVERRIDE, base-type=uint8, compu {phys=raw}, range phys 0..252
          signal StatusConfigurationFBD_HL_FBDonlyRSI: start 64, 8 bit, little-endian, data-type-policy=OVERRIDE, base-type=uint8, compu {phys=raw; unit s}, range phys 0..252
          signal StatusConfigurationFBD_HL_FBDonlyRSM: start 72, 8 bit, little-endian, data-type-policy=OVERRIDE, base-type=uint8, compu {phys=raw; unit s}, range phys 0..252
          signal StatusConfigurationFBD_HL_FBDonlyRTM: start 80, 8 bit, little-endian, data-type-policy=OVERRIDE, base-type=uint8, compu {phys=raw; unit min}, range phys 0..252
          signal StatusConfigurationFBD_HL_FBDonlyRAN: start 88, 8 bit, little-endian, data-type-policy=OVERRIDE, base-type=uint8, compu {phys=raw}, range phys 0..255
          signal StatusConfigurationFBD_HL_FBDonlyDataCollectionState: start 96, 8 bit, little-endian, data-type-policy=OVERRIDE, compu {phys=raw}
          signal StatusConfigurationFBD_HL_DeviceGroup: start 104, 8 bit, little-endian, data-type-policy=OVERRIDE, base-type=uint8, compu {phys=raw}, range phys 0..252
          signal StatusConfigurationFBD_HL_IRKListID: start 112, 8 bit, little-endian, data-type-policy=OVERRIDE, base-type=uint8, compu {phys=raw}, range phys 0..252
      frame StatusConfigurationFBD_HM: id 0x263, frame-length=16, can-addressing-mode=STANDARD, can-frame-rx-behavior=CAN-FD, can-frame-tx-behavior=CAN-FD
        pdu StatusConfigurationFBD_HM: length=16, unused-bit-pattern=0
          signal StatusConfigurationFBD_HM_UWBAntenna: start 0, 8 bit, little-endian, data-type-policy=OVERRIDE, base-type=uint8, compu {phys=raw}, range phys 0..252
          signal StatusConfigurationFBD_HM_UWBDutyCycleLimitSec: start 8, 8 bit, little-endian, data-type-policy=OVERRIDE, base-type=uint8, compu {phys=raw*0.5; unit ms}, range phys 0..126
          signal StatusConfigurationFBD_HM_UWBDutyCycleLimitHour: start 16, 8 bit, little-endian, data-type-policy=OVERRIDE, base-type=uint8, compu {phys=raw*0.1; unit s}, range phys 0..25.2
          signal StatusConfigurationFBD_HM_UWBDutyCycleLimitOffMeanSec: start 24, 8 bit, little-endian, data-type-policy=OVERRIDE, base-type=uint8, compu {phys=raw*0.5; unit ms}, range phys 0..126
          signal StatusConfigurationFBD_HM_FBDonlyWUT: start 32, 8 bit, little-endian, data-type-policy=OVERRIDE, base-type=uint8, compu {phys=raw*0.1; unit m}, range phys 0..25.2
          signal StatusConfigurationFBD_HM_FBDonlyRIT: start 40, 8 bit, little-endian, data-type-policy=OVERRIDE, compu {phys=raw}
          signal StatusConfigurationFBD_HM_FBDonlyRSU: start 48, 8 bit, little-endian, data-type-policy=OVERRIDE, base-type=uint8, compu {phys=raw; unit s}, range phys 0..252
          signal StatusConfigurationFBD_HM_FBDonlyRSE: start 56, 8 bit, little-endian, data-type-policy=OVERRIDE, base-type=uint8, compu {phys=raw}, range phys 0..252
          signal StatusConfigurationFBD_HM_FBDonlyRSI: start 64, 8 bit, little-endian, data-type-policy=OVERRIDE, base-type=uint8, compu {phys=raw; unit s}, range phys 0..252
          signal StatusConfigurationFBD_HM_FBDonlyRSM: start 72, 8 bit, little-endian, data-type-policy=OVERRIDE, base-type=uint8, compu {phys=raw; unit s}, range phys 0..252
          signal StatusConfigurationFBD_HM_FBDonlyRTM: start 80, 8 bit, little-endian, data-type-policy=OVERRIDE, base-type=uint8, compu {phys=raw; unit min}, range phys 0..252
          signal StatusConfigurationFBD_HM_FBDonlyRAN: start 88, 8 bit, little-endian, data-type-policy=OVERRIDE, base-type=uint8, compu {phys=raw}, range phys 0..255
          signal StatusConfigurationFBD_HM_FBDonlyDataCollectionState: start 96, 8 bit, little-endian, data-type-policy=OVERRIDE, compu {phys=raw}
          signal StatusConfigurationFBD_HM_DeviceGroup: start 104, 8 bit, little-endian, data-type-policy=OVERRIDE, base-type=uint8, compu {phys=raw}, range phys 0..252
          signal StatusConfigurationFBD_HM_IRKListID: start 112, 8 bit, little-endian, data-type-policy=OVERRIDE, base-type=uint8, compu {phys=raw}, range phys 0..252
      frame StatusConfigurationFBD_HR: id 0x269, frame-length=16, can-addressing-mode=STANDARD, can-frame-rx-behavior=CAN-FD, can-frame-tx-behavior=CAN-FD
        pdu StatusConfigurationFBD_HR: length=16, unused-bit-pattern=0
          signal StatusConfigurationFBD_HR_UWBAntenna: start 0, 8 bit, little-endian, data-type-policy=OVERRIDE, base-type=uint8, compu {phys=raw}, range phys 0..252
          signal StatusConfigurationFBD_HR_UWBDutyCycleLimitSec: start 8, 8 bit, little-endian, data-type-policy=OVERRIDE, base-type=uint8, compu {phys=raw*0.5; unit ms}, range phys 0..126
          signal StatusConfigurationFBD_HR_UWBDutyCycleLimitHour: start 16, 8 bit, little-endian, data-type-policy=OVERRIDE, base-type=uint8, compu {phys=raw*0.1; unit s}, range phys 0..25.2
          signal StatusConfigurationFBD_HR_UWBDutyCycleLimitOffMeanSec: start 24, 8 bit, little-endian, data-type-policy=OVERRIDE, base-type=uint8, compu {phys=raw*0.5; unit ms}, range phys 0..126
          signal StatusConfigurationFBD_HR_FBDonlyWUT: start 32, 8 bit, little-endian, data-type-policy=OVERRIDE, base-type=uint8, compu {phys=raw*0.1; unit m}, range phys 0..25.2
          signal StatusConfigurationFBD_HR_FBDonlyRIT: start 40, 8 bit, little-endian, data-type-policy=OVERRIDE, compu {phys=raw}
          signal StatusConfigurationFBD_HR_FBDonlyRSU: start 48, 8 bit, little-endian, data-type-policy=OVERRIDE, base-type=uint8, compu {phys=raw; unit s}, range phys 0..252
          signal StatusConfigurationFBD_HR_FBDonlyRSE: start 56, 8 bit, little-endian, data-type-policy=OVERRIDE, base-type=uint8, compu {phys=raw}, range phys 0..252
          signal StatusConfigurationFBD_HR_FBDonlyRSI: start 64, 8 bit, little-endian, data-type-policy=OVERRIDE, base-type=uint8, compu {phys=raw; unit s}, range phys 0..252
          signal StatusConfigurationFBD_HR_FBDonlyRSM: start 72, 8 bit, little-endian, data-type-policy=OVERRIDE, base-type=uint8, compu {phys=raw; unit s}, range phys 0..252
          signal StatusConfigurationFBD_HR_FBDonlyRTM: start 80, 8 bit, little-endian, data-type-policy=OVERRIDE, base-type=uint8, compu {phys=raw; unit min}, range phys 0..252
          signal StatusConfigurationFBD_HR_FBDonlyRAN: start 88, 8 bit, little-endian, data-type-policy=OVERRIDE, base-type=uint8, compu {phys=raw}, range phys 0..255
          signal StatusConfigurationFBD_HR_FBDonlyDataCollectionState: start 96, 8 bit, little-endian, data-type-policy=OVERRIDE, compu {phys=raw}
          signal StatusConfigurationFBD_HR_DeviceGroup: start 104, 8 bit, little-endian, data-type-policy=OVERRIDE, base-type=uint8, compu {phys=raw}, range phys 0..252
          signal StatusConfigurationFBD_HR_IRKListID: start 112, 8 bit, little-endian, data-type-policy=OVERRIDE, base-type=uint8, compu {phys=raw}, range phys 0..252
      frame StatusConfigurationFBD_Miko: id 0x264, frame-length=16, can-addressing-mode=STANDARD, can-frame-rx-behavior=CAN-FD, can-frame-tx-behavior=CAN-FD
        pdu StatusConfigurationFBD_Miko: length=16, unused-bit-pattern=0
          signal StatusConfigurationFBD_Miko_UWBAntenna: start 0, 8 bit, little-endian, data-type-policy=OVERRIDE, base-type=uint8, compu {phys=raw}, range phys 0..252
          signal StatusConfigurationFBD_Miko_UWBDutyCycleLimitSec: start 8, 8 bit, little-endian, data-type-policy=OVERRIDE, base-type=uint8, compu {phys=raw*0.5; unit ms}, range phys 0..126
          signal StatusConfigurationFBD_Miko_UWBDutyCycleLimitHour: start 16, 8 bit, little-endian, data-type-policy=OVERRIDE, base-type=uint8, compu {phys=raw*0.1; unit s}, range phys 0..25.2
          signal StatusConfigurationFBD_Miko_UWBDutyCycleLimitOffMeanSec: start 24, 8 bit, little-endian, data-type-policy=OVERRIDE, base-type=uint8, compu {phys=raw*0.5; unit ms}, range phys 0..126
          signal StatusConfigurationFBD_Miko_FBDonlyWUT: start 32, 8 bit, little-endian, data-type-policy=OVERRIDE, base-type=uint8, compu {phys=raw*0.1; unit m}, range phys 0..25.2
          signal StatusConfigurationFBD_Miko_FBDonlyRIT: start 40, 8 bit, little-endian, data-type-policy=OVERRIDE, compu {phys=raw}
          signal StatusConfigurationFBD_Miko_FBDonlyRSU: start 48, 8 bit, little-endian, data-type-policy=OVERRIDE, base-type=uint8, compu {phys=raw; unit s}, range phys 0..252
          signal StatusConfigurationFBD_Miko_FBDonlyRSE: start 56, 8 bit, little-endian, data-type-policy=OVERRIDE, base-type=uint8, compu {phys=raw}, range phys 0..252
          signal StatusConfigurationFBD_Miko_FBDonlyRSI: start 64, 8 bit, little-endian, data-type-policy=OVERRIDE, base-type=uint8, compu {phys=raw; unit s}, range phys 0..252
          signal StatusConfigurationFBD_Miko_FBDonlyRSM: start 72, 8 bit, little-endian, data-type-policy=OVERRIDE, base-type=uint8, compu {phys=raw; unit s}, range phys 0..252
          signal StatusConfigurationFBD_Miko_FBDonlyRTM: start 80, 8 bit, little-endian, data-type-policy=OVERRIDE, base-type=uint8, compu {phys=raw; unit min}, range phys 0..252
          signal StatusConfigurationFBD_Miko_FBDonlyRAN: start 88, 8 bit, little-endian, data-type-policy=OVERRIDE, base-type=uint8, compu {phys=raw}, range phys 0..255
          signal StatusConfigurationFBD_Miko_FBDonlyDataCollectionState: start 96, 8 bit, little-endian, data-type-policy=OVERRIDE, compu {phys=raw}
          signal StatusConfigurationFBD_Miko_DeviceGroup: start 104, 8 bit, little-endian, data-type-policy=OVERRIDE, base-type=uint8, compu {phys=raw}, range phys 0..252
          signal StatusConfigurationFBD_Miko_IRKListID: start 112, 8 bit, little-endian, data-type-policy=OVERRIDE, base-type=uint8, compu {phys=raw}, range phys 0..252
      frame StatusConfigurationFBD_MM: id 0x2B3, frame-length=16, can-addressing-mode=STANDARD, can-frame-rx-behavior=CAN-FD, can-frame-tx-behavior=CAN-FD
        pdu StatusConfigurationFBD_MM: length=16, unused-bit-pattern=0
          signal StatusConfigurationFBD_MM_UWBAntenna: start 0, 8 bit, little-endian, data-type-policy=OVERRIDE, base-type=uint8, compu {phys=raw}, range phys 0..252
          signal StatusConfigurationFBD_MM_UWBDutyCycleLimitSec: start 8, 8 bit, little-endian, data-type-policy=OVERRIDE, base-type=uint8, compu {phys=raw*0.5; unit ms}, range phys 0..126
          signal StatusConfigurationFBD_MM_UWBDutyCycleLimitHour: start 16, 8 bit, little-endian, data-type-policy=OVERRIDE, base-type=uint8, compu {phys=raw*0.1; unit s}, range phys 0..25.2
          signal StatusConfigurationFBD_MM_UWBDutyCycleLimitOffMeanSec: start 24, 8 bit, little-endian, data-type-policy=OVERRIDE, base-type=uint8, compu {phys=raw*0.5; unit ms}, range phys 0..126
          signal StatusConfigurationFBD_MM_FBDonlyWUT: start 32, 8 bit, little-endian, data-type-policy=OVERRIDE, base-type=uint8, compu {phys=raw*0.1; unit m}, range phys 0..25.2
          signal StatusConfigurationFBD_MM_FBDonlyRIT: start 40, 8 bit, little-endian, data-type-policy=OVERRIDE, compu {phys=raw}
          signal StatusConfigurationFBD_MM_FBDonlyRSU: start 48, 8 bit, little-endian, data-type-policy=OVERRIDE, base-type=uint8, compu {phys=raw; unit s}, range phys 0..252
          signal StatusConfigurationFBD_MM_FBDonlyRSE: start 56, 8 bit, little-endian, data-type-policy=OVERRIDE, base-type=uint8, compu {phys=raw; unit s}, range phys 0..252
          signal StatusConfigurationFBD_MM_FBDonlyRSI: start 64, 8 bit, little-endian, data-type-policy=OVERRIDE, base-type=uint8, compu {phys=raw; unit s}, range phys 0..252
          signal StatusConfigurationFBD_MM_FBDonlyRSM: start 72, 8 bit, little-endian, data-type-policy=OVERRIDE, base-type=uint8, compu {phys=raw; unit s}, range phys 0..252
          signal StatusConfigurationFBD_MM_FBDonlyRTM: start 80, 8 bit, little-endian, data-type-policy=OVERRIDE, base-type=uint8, compu {phys=raw; unit min}, range phys 0..252
          signal StatusConfigurationFBD_MM_FBDonlyRAN: start 88, 8 bit, little-endian, data-type-policy=OVERRIDE, base-type=uint8, compu {phys=raw}, range phys 0..255
          signal StatusConfigurationFBD_MM_FBDonlyDataCollectionState: start 96, 8 bit, little-endian, data-type-policy=OVERRIDE, compu {phys=raw}
          signal StatusConfigurationFBD_MM_DeviceGroup: start 104, 8 bit, little-endian, data-type-policy=OVERRIDE, base-type=uint8, compu {phys=raw}, range phys 0..252
          signal StatusConfigurationFBD_MM_IRKListID: start 112, 8 bit, little-endian, data-type-policy=OVERRIDE, base-type=uint8, compu {phys=raw}, range phys 0..252
      frame StatusConfigurationFBD_Trunk: id 0x265, frame-length=16, can-addressing-mode=STANDARD, can-frame-rx-behavior=CAN-FD, can-frame-tx-behavior=CAN-FD
        pdu StatusConfigurationFBD_Trunk: length=16, unused-bit-pattern=0
          signal StatusConfigurationFBD_Trunk_UWBAntenna: start 0, 8 bit, little-endian, data-type-policy=OVERRIDE, base-type=uint8, compu {phys=raw}, range phys 0..252
          signal StatusConfigurationFBD_Trunk_UWBDutyCycleLimitSec: start 8, 8 bit, little-endian, data-type-policy=OVERRIDE, base-type=uint8, compu {phys=raw*0.5; unit ms}, range phys 0..126
          signal StatusConfigurationFBD_Trunk_UWBDutyCycleLimitHour: start 16, 8 bit, little-endian, data-type-policy=OVERRIDE, base-type=uint8, compu {phys=raw*0.1; unit s}, range phys 0..25.2
          signal StatusConfigurationFBD_Trunk_UWBDutyCycleLimitOffMeanSec: start 24, 8 bit, little-endian, data-type-policy=OVERRIDE, base-type=uint8, compu {phys=raw*0.5; unit ms}, range phys 0..126
          signal StatusConfigurationFBD_Trunk_FBDonlyWUT: start 32, 8 bit, little-endian, data-type-policy=OVERRIDE, base-type=uint8, compu {phys=raw*0.1; unit m}, range phys 0..25.2
          signal StatusConfigurationFBD_Trunk_FBDonlyRIT: start 40, 8 bit, little-endian, data-type-policy=OVERRIDE, compu {phys=raw}
          signal StatusConfigurationFBD_Trunk_FBDonlyRSU: start 48, 8 bit, little-endian, data-type-policy=OVERRIDE, base-type=uint8, compu {phys=raw; unit s}, range phys 0..252
          signal StatusConfigurationFBD_Trunk_FBDonlyRSE: start 56, 8 bit, little-endian, data-type-policy=OVERRIDE, base-type=uint8, compu {phys=raw}, range phys 0..252
          signal StatusConfigurationFBD_Trunk_FBDonlyRSI: start 64, 8 bit, little-endian, data-type-policy=OVERRIDE, base-type=uint8, compu {phys=raw; unit s}, range phys 0..252
          signal StatusConfigurationFBD_Trunk_FBDonlyRSM: start 72, 8 bit, little-endian, data-type-policy=OVERRIDE, base-type=uint8, compu {phys=raw; unit s}, range phys 0..252
          signal StatusConfigurationFBD_Trunk_FBDonlyRTM: start 80, 8 bit, little-endian, data-type-policy=OVERRIDE, base-type=uint8, compu {phys=raw; unit min}, range phys 0..252
          signal StatusConfigurationFBD_Trunk_FBDonlyRAN: start 88, 8 bit, little-endian, data-type-policy=OVERRIDE, base-type=uint8, compu {phys=raw}, range phys 0..255
          signal StatusConfigurationFBD_Trunk_FBDonlyDataCollectionState: start 96, 8 bit, little-endian, data-type-policy=OVERRIDE, compu {phys=raw}
          signal StatusConfigurationFBD_Trunk_DeviceGroup: start 104, 8 bit, little-endian, data-type-policy=OVERRIDE, base-type=uint8, compu {phys=raw}, range phys 0..252
          signal StatusConfigurationFBD_Trunk_IRKListID: start 112, 8 bit, little-endian, data-type-policy=OVERRIDE, base-type=uint8, compu {phys=raw}, range phys 0..252
      frame StatusConfigurationFBD_VL: id 0x266, frame-length=16, can-addressing-mode=STANDARD, can-frame-rx-behavior=CAN-FD, can-frame-tx-behavior=CAN-FD
        pdu StatusConfigurationFBD_VL: length=16, unused-bit-pattern=0
          signal StatusConfigurationFBD_VL_UWBAntenna: start 0, 8 bit, little-endian, data-type-policy=OVERRIDE, base-type=uint8, compu {phys=raw}, range phys 0..252
          signal StatusConfigurationFBD_VL_UWBDutyCycleLimitSec: start 8, 8 bit, little-endian, data-type-policy=OVERRIDE, base-type=uint8, compu {phys=raw*0.5; unit ms}, range phys 0..126
          signal StatusConfigurationFBD_VL_UWBDutyCycleLimitHour: start 16, 8 bit, little-endian, data-type-policy=OVERRIDE, base-type=uint8, compu {phys=raw*0.1; unit s}, range phys 0..25.2
          signal StatusConfigurationFBD_VL_UWBDutyCycleLimitOffMeanSec: start 24, 8 bit, little-endian, data-type-policy=OVERRIDE, base-type=uint8, compu {phys=raw*0.5; unit ms}, range phys 0..126
          signal StatusConfigurationFBD_VL_FBDonlyWUT: start 32, 8 bit, little-endian, data-type-policy=OVERRIDE, base-type=uint8, compu {phys=raw*0.1; unit m}, range phys 0..25.2
          signal StatusConfigurationFBD_VL_FBDonlyRIT: start 40, 8 bit, little-endian, data-type-policy=OVERRIDE, compu {phys=raw}
          signal StatusConfigurationFBD_VL_FBDonlyRSU: start 48, 8 bit, little-endian, data-type-policy=OVERRIDE, base-type=uint8, compu {phys=raw; unit s}, range phys 0..252
          signal StatusConfigurationFBD_VL_FBDonlyRSE: start 56, 8 bit, little-endian, data-type-policy=OVERRIDE, base-type=uint8, compu {phys=raw}, range phys 0..252
          signal StatusConfigurationFBD_VL_FBDonlyRSI: start 64, 8 bit, little-endian, data-type-policy=OVERRIDE, base-type=uint8, compu {phys=raw; unit s}, range phys 0..252
          signal StatusConfigurationFBD_VL_FBDonlyRSM: start 72, 8 bit, little-endian, data-type-policy=OVERRIDE, base-type=uint8, compu {phys=raw; unit s}, range phys 0..252
          signal StatusConfigurationFBD_VL_FBDonlyRTM: start 80, 8 bit, little-endian, data-type-policy=OVERRIDE, base-type=uint8, compu {phys=raw; unit min}, range phys 0..252
          signal StatusConfigurationFBD_VL_FBDonlyRAN: start 88, 8 bit, little-endian, data-type-policy=OVERRIDE, base-type=uint8, compu {phys=raw}, range phys 0..255
          signal StatusConfigurationFBD_VL_FBDonlyDataCollectionState: start 96, 8 bit, little-endian, data-type-policy=OVERRIDE, compu {phys=raw}
          signal StatusConfigurationFBD_VL_DeviceGroup: start 104, 8 bit, little-endian, data-type-policy=OVERRIDE, base-type=uint8, compu {phys=raw}, range phys 0..252
          signal StatusConfigurationFBD_VL_IRKListID: start 112, 8 bit, little-endian, data-type-policy=OVERRIDE, base-type=uint8, compu {phys=raw}, range phys 0..252
      frame StatusConfigurationFBD_VM: id 0x262, frame-length=16, can-addressing-mode=STANDARD, can-frame-rx-behavior=CAN-FD, can-frame-tx-behavior=CAN-FD
        pdu StatusConfigurationFBD_VM: length=16, unused-bit-pattern=0
          signal StatusConfigurationFBD_VM_UWBAntenna: start 0, 8 bit, little-endian, data-type-policy=OVERRIDE, base-type=uint8, compu {phys=raw}, range phys 0..252
          signal StatusConfigurationFBD_VM_UWBDutyCycleLimitSec: start 8, 8 bit, little-endian, data-type-policy=OVERRIDE, base-type=uint8, compu {phys=raw*0.5; unit ms}, range phys 0..126
          signal StatusConfigurationFBD_VM_UWBDutyCycleLimitHour: start 16, 8 bit, little-endian, data-type-policy=OVERRIDE, base-type=uint8, compu {phys=raw*0.1; unit s}, range phys 0..25.2
          signal StatusConfigurationFBD_VM_UWBDutyCycleLimitOffMeanSec: start 24, 8 bit, little-endian, data-type-policy=OVERRIDE, base-type=uint8, compu {phys=raw*0.5; unit ms}, range phys 0..126
          signal StatusConfigurationFBD_VM_FBDonlyWUT: start 32, 8 bit, little-endian, data-type-policy=OVERRIDE, base-type=uint8, compu {phys=raw*0.1; unit m}, range phys 0..25.2
          signal StatusConfigurationFBD_VM_FBDonlyRIT: start 40, 8 bit, little-endian, data-type-policy=OVERRIDE, compu {phys=raw}
          signal StatusConfigurationFBD_VM_FBDonlyRSU: start 48, 8 bit, little-endian, data-type-policy=OVERRIDE, base-type=uint8, compu {phys=raw; unit s}, range phys 0..252
          signal StatusConfigurationFBD_VM_FBDonlyRSE: start 56, 8 bit, little-endian, data-type-policy=OVERRIDE, base-type=uint8, compu {phys=raw}, range phys 0..252
          signal StatusConfigurationFBD_VM_FBDonlyRSI: start 64, 8 bit, little-endian, data-type-policy=OVERRIDE, base-type=uint8, compu {phys=raw; unit s}, range phys 0..252
          signal StatusConfigurationFBD_VM_FBDonlyRSM: start 72, 8 bit, little-endian, data-type-policy=OVERRIDE, base-type=uint8, compu {phys=raw; unit s}, range phys 0..252
          signal StatusConfigurationFBD_VM_FBDonlyRTM: start 80, 8 bit, little-endian, data-type-policy=OVERRIDE, base-type=uint8, compu {phys=raw; unit min}, range phys 0..252
          signal StatusConfigurationFBD_VM_FBDonlyRAN: start 88, 8 bit, little-endian, data-type-policy=OVERRIDE, base-type=uint8, compu {phys=raw}, range phys 0..255
          signal StatusConfigurationFBD_VM_FBDonlyDataCollectionState: start 96, 8 bit, little-endian, data-type-policy=OVERRIDE, compu {phys=raw}
          signal StatusConfigurationFBD_VM_DeviceGroup: start 104, 8 bit, little-endian, data-type-policy=OVERRIDE, base-type=uint8, compu {phys=raw}, range phys 0..252
          signal StatusConfigurationFBD_VM_IRKListID: start 112, 8 bit, little-endian, data-type-policy=OVERRIDE, base-type=uint8, compu {phys=raw}, range phys 0..252
      frame StatusConfigurationFBD_VR: id 0x267, frame-length=16, can-addressing-mode=STANDARD, can-frame-rx-behavior=CAN-FD, can-frame-tx-behavior=CAN-FD
        pdu StatusConfigurationFBD_VR: length=16, unused-bit-pattern=0
          signal StatusConfigurationFBD_VR_UWBAntenna: start 0, 8 bit, little-endian, data-type-policy=OVERRIDE, base-type=uint8, compu {phys=raw}, range phys 0..252
          signal StatusConfigurationFBD_VR_UWBDutyCycleLimitSec: start 8, 8 bit, little-endian, data-type-policy=OVERRIDE, base-type=uint8, compu {phys=raw*0.5; unit ms}, range phys 0..126
          signal StatusConfigurationFBD_VR_UWBDutyCycleLimitHour: start 16, 8 bit, little-endian, data-type-policy=OVERRIDE, base-type=uint8, compu {phys=raw*0.1; unit s}, range phys 0..25.2
          signal StatusConfigurationFBD_VR_UWBDutyCycleLimitOffMeanSec: start 24, 8 bit, little-endian, data-type-policy=OVERRIDE, base-type=uint8, compu {phys=raw*0.5; unit ms}, range phys 0..126
          signal StatusConfigurationFBD_VR_FBDonlyWUT: start 32, 8 bit, little-endian, data-type-policy=OVERRIDE, base-type=uint8, compu {phys=raw*0.1; unit m}, range phys 0..25.2
          signal StatusConfigurationFBD_VR_FBDonlyRIT: start 40, 8 bit, little-endian, data-type-policy=OVERRIDE, compu {phys=raw}
          signal StatusConfigurationFBD_VR_FBDonlyRSU: start 48, 8 bit, little-endian, data-type-policy=OVERRIDE, base-type=uint8, compu {phys=raw; unit s}, range phys 0..252
          signal StatusConfigurationFBD_VR_FBDonlyRSE: start 56, 8 bit, little-endian, data-type-policy=OVERRIDE, base-type=uint8, compu {phys=raw}, range phys 0..252
          signal StatusConfigurationFBD_VR_FBDonlyRSI: start 64, 8 bit, little-endian, data-type-policy=OVERRIDE, base-type=uint8, compu {phys=raw; unit s}, range phys 0..252
          signal StatusConfigurationFBD_VR_FBDonlyRSM: start 72, 8 bit, little-endian, data-type-policy=OVERRIDE, base-type=uint8, compu {phys=raw; unit s}, range phys 0..252
          signal StatusConfigurationFBD_VR_FBDonlyRTM: start 80, 8 bit, little-endian, data-type-policy=OVERRIDE, base-type=uint8, compu {phys=raw; unit min}, range phys 0..252
          signal StatusConfigurationFBD_VR_FBDonlyRAN: start 88, 8 bit, little-endian, data-type-policy=OVERRIDE, base-type=uint8, compu {phys=raw}, range phys 0..255
          signal StatusConfigurationFBD_VR_FBDonlyDataCollectionState: start 96, 8 bit, little-endian, data-type-policy=OVERRIDE, compu {phys=raw}
          signal StatusConfigurationFBD_VR_DeviceGroup: start 104, 8 bit, little-endian, data-type-policy=OVERRIDE, base-type=uint8, compu {phys=raw}, range phys 0..252
          signal StatusConfigurationFBD_VR_IRKListID: start 112, 8 bit, little-endian, data-type-policy=OVERRIDE, base-type=uint8, compu {phys=raw}, range phys 0..252
      frame StatusCoordinatesFBD_HL: id 0x27C, frame-length=12, can-addressing-mode=STANDARD, can-frame-rx-behavior=CAN-FD, can-frame-tx-behavior=CAN-FD
        pdu StatusCoordinatesFBD_HL: length=12, unused-bit-pattern=0
          signal StatusCoordinatesFBD_HL_BodyFrontLeft_X: start 0, 10 bit, little-endian, data-type-policy=OVERRIDE, base-type=uint16, compu {phys=raw-250; unit cm}, range phys -250..770
          signal StatusCoordinatesFBD_HL_BodyFrontLeft_Y: start 10, 10 bit, little-endian, data-type-policy=OVERRIDE, base-type=uint16, compu {phys=raw-250; unit cm}, range phys -250..770
          signal StatusCoordinatesFBD_HL_BodyRearRight_X: start 20, 10 bit, little-endian, data-type-policy=OVERRIDE, base-type=uint16, compu {phys=raw-250; unit cm}, range phys -250..770
          signal StatusCoordinatesFBD_HL_BodyRearRight_Y: start 30, 10 bit, little-endian, data-type-policy=OVERRIDE, base-type=uint16, compu {phys=raw-250; unit cm}, range phys -250..770
          signal StatusCoordinatesFBD_HL_X: start 40, 10 bit, little-endian, data-type-policy=OVERRIDE, base-type=uint16, compu {phys=raw-250; unit cm}, range phys -250..770
          signal StatusCoordinatesFBD_HL_Y: start 50, 10 bit, little-endian, data-type-policy=OVERRIDE, base-type=uint16, compu {phys=raw-250; unit cm}, range phys -250..770
          signal StatusCoordinatesFBD_HL_Z: start 60, 10 bit, little-endian, data-type-policy=OVERRIDE, base-type=uint16, compu {phys=raw-250; unit cm}, range phys -250..770
          signal StatusCoordinatesFBD_HL_azimuth: start 70, 9 bit, little-endian, data-type-policy=OVERRIDE, base-type=uint16, compu {phys=raw-180; unit °}, range phys -180..180
          signal StatusCoordinatesFBD_HL_elevation: start 79, 8 bit, little-endian, data-type-policy=OVERRIDE, base-type=uint8, compu {phys=raw-100; unit °}, range phys -100..100
          signal StatusCoordinatesFBD_HL_InvalidConfiguration: start 88, 8 bit, little-endian, data-type-policy=OVERRIDE, base-type=uint8, compu {phys=raw}, range phys 0..252
      frame StatusCoordinatesFBD_HM: id 0x277, frame-length=12, can-addressing-mode=STANDARD, can-frame-rx-behavior=CAN-FD, can-frame-tx-behavior=CAN-FD
        pdu StatusCoordinatesFBD_HM: length=12, unused-bit-pattern=0
          signal StatusCoordinatesFBD_HM_BodyFrontLeft_X: start 0, 10 bit, little-endian, data-type-policy=OVERRIDE, base-type=uint16, compu {phys=raw-250; unit cm}, range phys -250..770
          signal StatusCoordinatesFBD_HM_BodyFrontLeft_Y: start 10, 10 bit, little-endian, data-type-policy=OVERRIDE, base-type=uint16, compu {phys=raw-250; unit cm}, range phys -250..770
          signal StatusCoordinatesFBD_HM_BodyRearRight_X: start 20, 10 bit, little-endian, data-type-policy=OVERRIDE, base-type=uint16, compu {phys=raw-250; unit cm}, range phys -250..770
          signal StatusCoordinatesFBD_HM_BodyRearRight_Y: start 30, 10 bit, little-endian, data-type-policy=OVERRIDE, base-type=uint16, compu {phys=raw-250; unit cm}, range phys -250..770
          signal StatusCoordinatesFBD_HM_X: start 40, 10 bit, little-endian, data-type-policy=OVERRIDE, base-type=uint16, compu {phys=raw-250; unit cm}, range phys -250..770
          signal StatusCoordinatesFBD_HM_Y: start 50, 10 bit, little-endian, data-type-policy=OVERRIDE, base-type=uint16, compu {phys=raw-250; unit cm}, range phys -250..770
          signal StatusCoordinatesFBD_HM_Z: start 60, 10 bit, little-endian, data-type-policy=OVERRIDE, base-type=uint16, compu {phys=raw-250; unit cm}, range phys -250..770
          signal StatusCoordinatesFBD_HM_azimuth: start 70, 9 bit, little-endian, data-type-policy=OVERRIDE, base-type=uint16, compu {phys=raw-180; unit °}, range phys -180..180
          signal StatusCoordinatesFBD_HM_elevation: start 79, 8 bit, little-endian, data-type-policy=OVERRIDE, base-type=uint8, compu {phys=raw-100; unit °}, range phys -100..100
          signal StatusCoordinatesFBD_HM_InvalidConfiguration: start 88, 8 bit, little-endian, data-type-policy=OVERRIDE, base-type=uint8, compu {phys=raw}, range phys 0..252
      frame StatusCoordinatesFBD_HR: id 0x27D, frame-length=12, can-addressing-mode=STANDARD, can-frame-rx-behavior=CAN-FD, can-frame-tx-behavior=CAN-FD
        pdu StatusCoordinatesFBD_HR: length=12, unused-bit-pattern=0
          signal StatusCoordinatesFBD_HR_BodyFrontLeft_X: start 0, 10 bit, little-endian, data-type-policy=OVERRIDE, base-type=uint16, compu {phys=raw-250; unit cm}, range phys -250..770
          signal StatusCoordinatesFBD_HR_BodyFrontLeft_Y: start 10, 10 bit, little-endian, data-type-policy=OVERRIDE, base-type=uint16, compu {phys=raw-250; unit cm}, range phys -250..770
          signal StatusCoordinatesFBD_HR_BodyRearRight_X: start 20, 10 bit, little-endian, data-type-policy=OVERRIDE, base-type=uint16, compu {phys=raw-250; unit cm}, range phys -250..770
          signal StatusCoordinatesFBD_HR_BodyRearRight_Y: start 30, 10 bit, little-endian, data-type-policy=OVERRIDE, base-type=uint16, compu {phys=raw-250; unit cm}, range phys -250..770
          signal StatusCoordinatesFBD_HR_X: start 40, 10 bit, little-endian, data-type-policy=OVERRIDE, base-type=uint16, compu {phys=raw-250; unit cm}, range phys -250..770
          signal StatusCoordinatesFBD_HR_Y: start 50, 10 bit, little-endian, data-type-policy=OVERRIDE, base-type=uint16, compu {phys=raw-250; unit cm}, range phys -250..770
          signal StatusCoordinatesFBD_HR_Z: start 60, 10 bit, little-endian, data-type-policy=OVERRIDE, base-type=uint16, compu {phys=raw-250; unit cm}, range phys -250..770
          signal StatusCoordinatesFBD_HR_azimuth: start 70, 9 bit, little-endian, data-type-policy=OVERRIDE, base-type=uint16, compu {phys=raw-180; unit °}, range phys -180..180
          signal StatusCoordinatesFBD_HR_elevation: start 79, 8 bit, little-endian, data-type-policy=OVERRIDE, base-type=uint8, compu {phys=raw-100; unit °}, range phys -100..100
          signal StatusCoordinatesFBD_HR_InvalidConfiguration: start 88, 8 bit, little-endian, data-type-policy=OVERRIDE, base-type=uint8, compu {phys=raw}, range phys 0..252
      frame StatusCoordinatesFBD_Miko: id 0x278, frame-length=12, can-addressing-mode=STANDARD, can-frame-rx-behavior=CAN-FD, can-frame-tx-behavior=CAN-FD
        pdu StatusCoordinatesFBD_Miko: length=12, unused-bit-pattern=0
          signal StatusCoordinatesFBD_Miko_BodyFrontLeft_X: start 0, 10 bit, little-endian, data-type-policy=OVERRIDE, base-type=uint16, compu {phys=raw-250; unit cm}, range phys -250..770
          signal StatusCoordinatesFBD_Miko_BodyFrontLeft_Y: start 10, 10 bit, little-endian, data-type-policy=OVERRIDE, base-type=uint16, compu {phys=raw-250; unit cm}, range phys -250..770
          signal StatusCoordinatesFBD_Miko_BodyRearRight_X: start 20, 10 bit, little-endian, data-type-policy=OVERRIDE, base-type=uint16, compu {phys=raw-250; unit cm}, range phys -250..770
          signal StatusCoordinatesFBD_Miko_BodyRearRight_Y: start 30, 10 bit, little-endian, data-type-policy=OVERRIDE, base-type=uint16, compu {phys=raw-250; unit cm}, range phys -250..770
          signal StatusCoordinatesFBD_Miko_X: start 40, 10 bit, little-endian, data-type-policy=OVERRIDE, base-type=uint16, compu {phys=raw-250; unit cm}, range phys -250..770
          signal StatusCoordinatesFBD_Miko_Y: start 50, 10 bit, little-endian, data-type-policy=OVERRIDE, base-type=uint16, compu {phys=raw-250; unit cm}, range phys -250..770
          signal StatusCoordinatesFBD_Miko_Z: start 60, 10 bit, little-endian, data-type-policy=OVERRIDE, base-type=uint16, compu {phys=raw-250; unit cm}, range phys -250..770
          signal StatusCoordinatesFBD_Miko_azimuth: start 70, 9 bit, little-endian, data-type-policy=OVERRIDE, base-type=uint16, compu {phys=raw-180; unit °}, range phys -180..180
          signal StatusCoordinatesFBD_Miko_elevation: start 79, 8 bit, little-endian, data-type-policy=OVERRIDE, base-type=uint8, compu {phys=raw-100; unit °}, range phys -100..100
          signal StatusCoordinatesFBD_Miko_InvalidConfiguration: start 88, 8 bit, little-endian, data-type-policy=OVERRIDE, base-type=uint8, compu {phys=raw}, range phys 0..252
      frame StatusCoordinatesFBD_MM: id 0x2B4, frame-length=12, can-addressing-mode=STANDARD, can-frame-rx-behavior=CAN-FD, can-frame-tx-behavior=CAN-FD
        pdu StatusCoordinatesFBD_MM: length=12, unused-bit-pattern=0
          signal StatusCoordinatesFBD_MM_BodyFrontLeft_X: start 0, 10 bit, little-endian, data-type-policy=OVERRIDE, base-type=uint16, compu {phys=raw-250; unit cm}, range phys -250..770
          signal StatusCoordinatesFBD_MM_BodyFrontLeft_Y: start 10, 10 bit, little-endian, data-type-policy=OVERRIDE, base-type=uint16, compu {phys=raw-250; unit cm}, range phys -250..770
          signal StatusCoordinatesFBD_MM_BodyRearRight_X: start 20, 10 bit, little-endian, data-type-policy=OVERRIDE, base-type=uint16, compu {phys=raw-250; unit cm}, range phys -250..770
          signal StatusCoordinatesFBD_MM_BodyRearRight_Y: start 30, 10 bit, little-endian, data-type-policy=OVERRIDE, base-type=uint16, compu {phys=raw-250; unit cm}, range phys -250..770
          signal StatusCoordinatesFBD_MM_X: start 40, 10 bit, little-endian, data-type-policy=OVERRIDE, base-type=uint16, compu {phys=raw-250; unit cm}, range phys -250..770
          signal StatusCoordinatesFBD_MM_Y: start 50, 10 bit, little-endian, data-type-policy=OVERRIDE, base-type=uint16, compu {phys=raw-250; unit cm}, range phys -250..770
          signal StatusCoordinatesFBD_MM_Z: start 60, 10 bit, little-endian, data-type-policy=OVERRIDE, base-type=uint16, compu {phys=raw-250; unit cm}, range phys -250..770
          signal StatusCoordinatesFBD_MM_azimuth: start 70, 9 bit, little-endian, data-type-policy=OVERRIDE, base-type=uint16, compu {phys=raw-180; unit °}, range phys -180..180
          signal StatusCoordinatesFBD_MM_elevation: start 79, 8 bit, little-endian, data-type-policy=OVERRIDE, base-type=uint8, compu {phys=raw-100; unit °}, range phys -100..100
          signal StatusCoordinatesFBD_MM_InvalidConfiguration: start 88, 8 bit, little-endian, data-type-policy=OVERRIDE, base-type=uint8, compu {phys=raw}, range phys 0..252
      frame StatusCoordinatesFBD_Trunk: id 0x279, frame-length=12, can-addressing-mode=STANDARD, can-frame-rx-behavior=CAN-FD, can-frame-tx-behavior=CAN-FD
        pdu StatusCoordinatesFBD_Trunk: length=12, unused-bit-pattern=0
          signal StatusCoordinatesFBD_Trunk_BodyFrontLeft_X: start 0, 10 bit, little-endian, data-type-policy=OVERRIDE, base-type=uint16, compu {phys=raw-250; unit cm}, range phys -250..770
          signal StatusCoordinatesFBD_Trunk_BodyFrontLeft_Y: start 10, 10 bit, little-endian, data-type-policy=OVERRIDE, base-type=uint16, compu {phys=raw-250; unit cm}, range phys -250..770
          signal StatusCoordinatesFBD_Trunk_BodyRearRight_X: start 20, 10 bit, little-endian, data-type-policy=OVERRIDE, base-type=uint16, compu {phys=raw-250; unit cm}, range phys -250..770
          signal StatusCoordinatesFBD_Trunk_BodyRearRight_Y: start 30, 10 bit, little-endian, data-type-policy=OVERRIDE, base-type=uint16, compu {phys=raw-250; unit cm}, range phys -250..770
          signal StatusCoordinatesFBD_Trunk_X: start 40, 10 bit, little-endian, data-type-policy=OVERRIDE, base-type=uint16, compu {phys=raw-250; unit cm}, range phys -250..770
          signal StatusCoordinatesFBD_Trunk_Y: start 50, 10 bit, little-endian, data-type-policy=OVERRIDE, base-type=uint16, compu {phys=raw-250; unit cm}, range phys -250..770
          signal StatusCoordinatesFBD_Trunk_Z: start 60, 10 bit, little-endian, data-type-policy=OVERRIDE, base-type=uint16, compu {phys=raw-250; unit cm}, range phys -250..770
          signal StatusCoordinatesFBD_Trunk_azimuth: start 70, 9 bit, little-endian, data-type-policy=OVERRIDE, base-type=uint16, compu {phys=raw-180; unit °}, range phys -180..180
          signal StatusCoordinatesFBD_Trunk_elevation: start 79, 8 bit, little-endian, data-type-policy=OVERRIDE, base-type=uint8, compu {phys=raw-100; unit °}, range phys -100..100
          signal StatusCoordinatesFBD_Trunk_InvalidConfiguration: start 88, 8 bit, little-endian, data-type-policy=OVERRIDE, base-type=uint8, compu {phys=raw}, range phys 0..252
      frame StatusCoordinatesFBD_VL: id 0x27A, frame-length=12, can-addressing-mode=STANDARD, can-frame-rx-behavior=CAN-FD, can-frame-tx-behavior=CAN-FD
        pdu StatusCoordinatesFBD_VL: length=12, unused-bit-pattern=0
          signal StatusCoordinatesFBD_VL_BodyFrontLeft_X: start 0, 10 bit, little-endian, data-type-policy=OVERRIDE, base-type=uint16, compu {phys=raw-250; unit cm}, range phys -250..770
          signal StatusCoordinatesFBD_VL_BodyFrontLeft_Y: start 10, 10 bit, little-endian, data-type-policy=OVERRIDE, base-type=uint16, compu {phys=raw-250; unit cm}, range phys -250..770
          signal StatusCoordinatesFBD_VL_BodyRearRight_X: start 20, 10 bit, little-endian, data-type-policy=OVERRIDE, base-type=uint16, compu {phys=raw-250; unit cm}, range phys -250..770
          signal StatusCoordinatesFBD_VL_BodyRearRight_Y: start 30, 10 bit, little-endian, data-type-policy=OVERRIDE, base-type=uint16, compu {phys=raw-250; unit cm}, range phys -250..770
          signal StatusCoordinatesFBD_VL_X: start 40, 10 bit, little-endian, data-type-policy=OVERRIDE, base-type=uint16, compu {phys=raw-250; unit cm}, range phys -250..770
          signal StatusCoordinatesFBD_VL_Y: start 50, 10 bit, little-endian, data-type-policy=OVERRIDE, base-type=uint16, compu {phys=raw-250; unit cm}, range phys -250..770
          signal StatusCoordinatesFBD_VL_Z: start 60, 10 bit, little-endian, data-type-policy=OVERRIDE, base-type=uint16, compu {phys=raw-250; unit cm}, range phys -250..770
          signal StatusCoordinatesFBD_VL_azimuth: start 70, 9 bit, little-endian, data-type-policy=OVERRIDE, base-type=uint16, compu {phys=raw-180; unit °}, range phys -180..180
          signal StatusCoordinatesFBD_VL_elevation: start 79, 8 bit, little-endian, data-type-policy=OVERRIDE, base-type=uint8, compu {phys=raw-100; unit °}, range phys -100..100
          signal StatusCoordinatesFBD_VL_InvalidConfiguration: start 88, 8 bit, little-endian, data-type-policy=OVERRIDE, base-type=uint8, compu {phys=raw}, range phys 0..252
      frame StatusCoordinatesFBD_VM: id 0x276, frame-length=12, can-addressing-mode=STANDARD, can-frame-rx-behavior=CAN-FD, can-frame-tx-behavior=CAN-FD
        pdu StatusCoordinatesFBD_VM: length=12, unused-bit-pattern=0
          signal StatusCoordinatesFBD_VM_BodyFrontLeft_X: start 0, 10 bit, little-endian, data-type-policy=OVERRIDE, base-type=uint16, compu {phys=raw-250; unit cm}, range phys -250..770
          signal StatusCoordinatesFBD_VM_BodyFrontLeft_Y: start 10, 10 bit, little-endian, data-type-policy=OVERRIDE, base-type=uint16, compu {phys=raw-250; unit cm}, range phys -250..770
          signal StatusCoordinatesFBD_VM_BodyRearRight_X: start 20, 10 bit, little-endian, data-type-policy=OVERRIDE, base-type=uint16, compu {phys=raw-250; unit cm}, range phys -250..770
          signal StatusCoordinatesFBD_VM_BodyRearRight_Y: start 30, 10 bit, little-endian, data-type-policy=OVERRIDE, base-type=uint16, compu {phys=raw-250; unit cm}, range phys -250..770
          signal StatusCoordinatesFBD_VM_X: start 40, 10 bit, little-endian, data-type-policy=OVERRIDE, base-type=uint16, compu {phys=raw-250; unit cm}, range phys -250..770
          signal StatusCoordinatesFBD_VM_Y: start 50, 10 bit, little-endian, data-type-policy=OVERRIDE, base-type=uint16, compu {phys=raw-250; unit cm}, range phys -250..770
          signal StatusCoordinatesFBD_VM_Z: start 60, 10 bit, little-endian, data-type-policy=OVERRIDE, base-type=uint16, compu {phys=raw-250; unit cm}, range phys -250..770
          signal StatusCoordinatesFBD_VM_azimuth: start 70, 9 bit, little-endian, data-type-policy=OVERRIDE, base-type=uint16, compu {phys=raw-180; unit °}, range phys -180..180
          signal StatusCoordinatesFBD_VM_elevation: start 79, 8 bit, little-endian, data-type-policy=OVERRIDE, base-type=uint8, compu {phys=raw-100; unit °}, range phys -100..100
          signal StatusCoordinatesFBD_VM_InvalidConfiguration: start 88, 8 bit, little-endian, data-type-policy=OVERRIDE, base-type=uint8, compu {phys=raw}, range phys 0..252
      frame StatusCoordinatesFBD_VR: id 0x27B, frame-length=12, can-addressing-mode=STANDARD, can-frame-rx-behavior=CAN-FD, can-frame-tx-behavior=CAN-FD
        pdu StatusCoordinatesFBD_VR: length=12, unused-bit-pattern=0
          signal StatusCoordinatesFBD_VR_BodyFrontLeft_X: start 0, 10 bit, little-endian, data-type-policy=OVERRIDE, base-type=uint16, compu {phys=raw-250; unit cm}, range phys -250..770
          signal StatusCoordinatesFBD_VR_BodyFrontLeft_Y: start 10, 10 bit, little-endian, data-type-policy=OVERRIDE, base-type=uint16, compu {phys=raw-250; unit cm}, range phys -250..770
          signal StatusCoordinatesFBD_VR_BodyRearRight_X: start 20, 10 bit, little-endian, data-type-policy=OVERRIDE, base-type=uint16, compu {phys=raw-250; unit cm}, range phys -250..770
          signal StatusCoordinatesFBD_VR_BodyRearRight_Y: start 30, 10 bit, little-endian, data-type-policy=OVERRIDE, base-type=uint16, compu {phys=raw-250; unit cm}, range phys -250..770
          signal StatusCoordinatesFBD_VR_X: start 40, 10 bit, little-endian, data-type-policy=OVERRIDE, base-type=uint16, compu {phys=raw-250; unit cm}, range phys -250..770
          signal StatusCoordinatesFBD_VR_Y: start 50, 10 bit, little-endian, data-type-policy=OVERRIDE, base-type=uint16, compu {phys=raw-250; unit cm}, range phys -250..770
          signal StatusCoordinatesFBD_VR_Z: start 60, 10 bit, little-endian, data-type-policy=OVERRIDE, base-type=uint16, compu {phys=raw-250; unit cm}, range phys -250..770
          signal StatusCoordinatesFBD_VR_azimuth: start 70, 9 bit, little-endian, data-type-policy=OVERRIDE, base-type=uint16, compu {phys=raw-180; unit °}, range phys -180..180
          signal StatusCoordinatesFBD_VR_elevation: start 79, 8 bit, little-endian, data-type-policy=OVERRIDE, base-type=uint8, compu {phys=raw-100; unit °}, range phys -100..100
          signal StatusCoordinatesFBD_VR_InvalidConfiguration: start 88, 8 bit, little-endian, data-type-policy=OVERRIDE, base-type=uint8, compu {phys=raw}, range phys 0..252
      frame StatusCPDData1FBD_HL: id 0x150, frame-length=64, can-addressing-mode=STANDARD, can-frame-rx-behavior=CAN-FD, can-frame-tx-behavior=CAN-FD
        pdu StatusCPDData1FBD_HL: length=64, unused-bit-pattern=0
          signal StatusCPDData1FBD_HL_MsgCounter: start 0, 8 bit, little-endian, data-type-policy=OVERRIDE, base-type=uint8, compu {phys=raw}, range phys 0..252
          signal StatusCPDData1FBD_HL_LinkID: start 8, 8 bit, little-endian, data-type-policy=OVERRIDE, base-type=uint8, compu {phys=raw}, range phys 0..252
          signal StatusCPDData1FBD_HL_AGCValue: start 16, 8 bit, little-endian, data-type-policy=OVERRIDE, base-type=uint8, compu {phys=raw}, range phys 0..252
          signal StatusCPDData1FBD_HL_Channel: start 24, 8 bit, little-endian, data-type-policy=OVERRIDE, base-type=uint8, compu {phys=raw}, range phys 0..252
          signal StatusCPDData1FBD_HL_CIRData00: start 32, 8 bit, little-endian, data-type-policy=OVERRIDE, base-type=uint8, compu {phys=raw}, range phys 0..255
          signal StatusCPDData1FBD_HL_CIRData01: start 40, 8 bit, little-endian, data-type-policy=OVERRIDE, base-type=uint8, compu {phys=raw}, range phys 0..255
          signal StatusCPDData1FBD_HL_CIRData02: start 48, 8 bit, little-endian, data-type-policy=OVERRIDE, base-type=uint8, compu {phys=raw}, range phys 0..255
          signal StatusCPDData1FBD_HL_CIRData03: start 56, 8 bit, little-endian, data-type-policy=OVERRIDE, base-type=uint8, compu {phys=raw}, range phys 0..255
          signal StatusCPDData1FBD_HL_CIRData04: start 64, 8 bit, little-endian, data-type-policy=OVERRIDE, base-type=uint8, compu {phys=raw}, range phys 0..255
          signal StatusCPDData1FBD_HL_CIRData05: start 72, 8 bit, little-endian, data-type-policy=OVERRIDE, base-type=uint8, compu {phys=raw}, range phys 0..255
          signal StatusCPDData1FBD_HL_CIRData06: start 80, 8 bit, little-endian, data-type-policy=OVERRIDE, base-type=uint8, compu {phys=raw}, range phys 0..255
          signal StatusCPDData1FBD_HL_CIRData07: start 88, 8 bit, little-endian, data-type-policy=OVERRIDE, base-type=uint8, compu {phys=raw}, range phys 0..255
          signal StatusCPDData1FBD_HL_CIRData08: start 96, 8 bit, little-endian, data-type-policy=OVERRIDE, base-type=uint8, compu {phys=raw}, range phys 0..255
          signal StatusCPDData1FBD_HL_CIRData09: start 104, 8 bit, little-endian, data-type-policy=OVERRIDE, base-type=uint8, compu {phys=raw}, range phys 0..255
          signal StatusCPDData1FBD_HL_CIRData10: start 112, 8 bit, little-endian, data-type-policy=OVERRIDE, base-type=uint8, compu {phys=raw}, range phys 0..255
          signal StatusCPDData1FBD_HL_CIRData11: start 120, 8 bit, little-endian, data-type-policy=OVERRIDE, base-type=uint8, compu {phys=raw}, range phys 0..255
          signal StatusCPDData1FBD_HL_CIRData12: start 128, 8 bit, little-endian, data-type-policy=OVERRIDE, base-type=uint8, compu {phys=raw}, range phys 0..255
          signal StatusCPDData1FBD_HL_CIRData13: start 136, 8 bit, little-endian, data-type-policy=OVERRIDE, base-type=uint8, compu {phys=raw}, range phys 0..255
          signal StatusCPDData1FBD_HL_CIRData14: start 144, 8 bit, little-endian, data-type-policy=OVERRIDE, base-type=uint8, compu {phys=raw}, range phys 0..255
          signal StatusCPDData1FBD_HL_CIRData15: start 152, 8 bit, little-endian, data-type-policy=OVERRIDE, base-type=uint8, compu {phys=raw}, range phys 0..255
          signal StatusCPDData1FBD_HL_CIRData16: start 160, 8 bit, little-endian, data-type-policy=OVERRIDE, base-type=uint8, compu {phys=raw}, range phys 0..255
          signal StatusCPDData1FBD_HL_CIRData17: start 168, 8 bit, little-endian, data-type-policy=OVERRIDE, base-type=uint8, compu {phys=raw}, range phys 0..255
          signal StatusCPDData1FBD_HL_CIRData18: start 176, 8 bit, little-endian, data-type-policy=OVERRIDE, base-type=uint8, compu {phys=raw}, range phys 0..255
          signal StatusCPDData1FBD_HL_CIRData19: start 184, 8 bit, little-endian, data-type-policy=OVERRIDE, base-type=uint8, compu {phys=raw}, range phys 0..255
          signal StatusCPDData1FBD_HL_CIRData20: start 192, 8 bit, little-endian, data-type-policy=OVERRIDE, base-type=uint8, compu {phys=raw}, range phys 0..255
          signal StatusCPDData1FBD_HL_CIRData21: start 200, 8 bit, little-endian, data-type-policy=OVERRIDE, base-type=uint8, compu {phys=raw}, range phys 0..255
          signal StatusCPDData1FBD_HL_CIRData22: start 208, 8 bit, little-endian, data-type-policy=OVERRIDE, base-type=uint8, compu {phys=raw}, range phys 0..255
          signal StatusCPDData1FBD_HL_CIRData23: start 216, 8 bit, little-endian, data-type-policy=OVERRIDE, base-type=uint8, compu {phys=raw}, range phys 0..255
          signal StatusCPDData1FBD_HL_CIRData24: start 224, 8 bit, little-endian, data-type-policy=OVERRIDE, base-type=uint8, compu {phys=raw}, range phys 0..255
          signal StatusCPDData1FBD_HL_CIRData25: start 232, 8 bit, little-endian, data-type-policy=OVERRIDE, base-type=uint8, compu {phys=raw}, range phys 0..255
          signal StatusCPDData1FBD_HL_CIRData26: start 240, 8 bit, little-endian, data-type-policy=OVERRIDE, base-type=uint8, compu {phys=raw}, range phys 0..255
          signal StatusCPDData1FBD_HL_CIRData27: start 248, 8 bit, little-endian, data-type-policy=OVERRIDE, base-type=uint8, compu {phys=raw}, range phys 0..255
          signal StatusCPDData1FBD_HL_CIRData28: start 256, 8 bit, little-endian, data-type-policy=OVERRIDE, base-type=uint8, compu {phys=raw}, range phys 0..255
          signal StatusCPDData1FBD_HL_CIRData29: start 264, 8 bit, little-endian, data-type-policy=OVERRIDE, base-type=uint8, compu {phys=raw}, range phys 0..255
          signal StatusCPDData1FBD_HL_CIRData30: start 272, 8 bit, little-endian, data-type-policy=OVERRIDE, base-type=uint8, compu {phys=raw}, range phys 0..255
          signal StatusCPDData1FBD_HL_CIRData31: start 280, 8 bit, little-endian, data-type-policy=OVERRIDE, base-type=uint8, compu {phys=raw}, range phys 0..255
          signal StatusCPDData1FBD_HL_CIRData32: start 288, 8 bit, little-endian, data-type-policy=OVERRIDE, base-type=uint8, compu {phys=raw}, range phys 0..255
          signal StatusCPDData1FBD_HL_CIRData33: start 296, 8 bit, little-endian, data-type-policy=OVERRIDE, base-type=uint8, compu {phys=raw}, range phys 0..255
          signal StatusCPDData1FBD_HL_CIRData34: start 304, 8 bit, little-endian, data-type-policy=OVERRIDE, base-type=uint8, compu {phys=raw}, range phys 0..255
          signal StatusCPDData1FBD_HL_CIRData35: start 312, 8 bit, little-endian, data-type-policy=OVERRIDE, base-type=uint8, compu {phys=raw}, range phys 0..255
          signal StatusCPDData1FBD_HL_CIRData36: start 320, 8 bit, little-endian, data-type-policy=OVERRIDE, base-type=uint8, compu {phys=raw}, range phys 0..255
          signal StatusCPDData1FBD_HL_CIRData37: start 328, 8 bit, little-endian, data-type-policy=OVERRIDE, base-type=uint8, compu {phys=raw}, range phys 0..255
          signal StatusCPDData1FBD_HL_CIRData38: start 336, 8 bit, little-endian, data-type-policy=OVERRIDE, base-type=uint8, compu {phys=raw}, range phys 0..255
          signal StatusCPDData1FBD_HL_CIRData39: start 344, 8 bit, little-endian, data-type-policy=OVERRIDE, base-type=uint8, compu {phys=raw}, range phys 0..255
          signal StatusCPDData1FBD_HL_CIRData40: start 352, 8 bit, little-endian, data-type-policy=OVERRIDE, base-type=uint8, compu {phys=raw}, range phys 0..255
          signal StatusCPDData1FBD_HL_CIRData41: start 360, 8 bit, little-endian, data-type-policy=OVERRIDE, base-type=uint8, compu {phys=raw}, range phys 0..255
          signal StatusCPDData1FBD_HL_CIRData42: start 368, 8 bit, little-endian, data-type-policy=OVERRIDE, base-type=uint8, compu {phys=raw}, range phys 0..255
          signal StatusCPDData1FBD_HL_CIRData43: start 376, 8 bit, little-endian, data-type-policy=OVERRIDE, base-type=uint8, compu {phys=raw}, range phys 0..255
          signal StatusCPDData1FBD_HL_CIRData44: start 384, 8 bit, little-endian, data-type-policy=OVERRIDE, base-type=uint8, compu {phys=raw}, range phys 0..255
          signal StatusCPDData1FBD_HL_CIRData45: start 392, 8 bit, little-endian, data-type-policy=OVERRIDE, base-type=uint8, compu {phys=raw}, range phys 0..255
          signal StatusCPDData1FBD_HL_CIRData46: start 400, 8 bit, little-endian, data-type-policy=OVERRIDE, base-type=uint8, compu {phys=raw}, range phys 0..255
          signal StatusCPDData1FBD_HL_CIRData47: start 408, 8 bit, little-endian, data-type-policy=OVERRIDE, base-type=uint8, compu {phys=raw}, range phys 0..255
          signal StatusCPDData1FBD_HL_CIRData48: start 416, 8 bit, little-endian, data-type-policy=OVERRIDE, base-type=uint8, compu {phys=raw}, range phys 0..255
          signal StatusCPDData1FBD_HL_CIRData49: start 424, 8 bit, little-endian, data-type-policy=OVERRIDE, base-type=uint8, compu {phys=raw}, range phys 0..255
          signal StatusCPDData1FBD_HL_CIRData50: start 432, 8 bit, little-endian, data-type-policy=OVERRIDE, base-type=uint8, compu {phys=raw}, range phys 0..255
          signal StatusCPDData1FBD_HL_CIRData51: start 440, 8 bit, little-endian, data-type-policy=OVERRIDE, base-type=uint8, compu {phys=raw}, range phys 0..255
          signal StatusCPDData1FBD_HL_CIRData52: start 448, 8 bit, little-endian, data-type-policy=OVERRIDE, base-type=uint8, compu {phys=raw}, range phys 0..255
          signal StatusCPDData1FBD_HL_CIRData53: start 456, 8 bit, little-endian, data-type-policy=OVERRIDE, base-type=uint8, compu {phys=raw}, range phys 0..255
          signal StatusCPDData1FBD_HL_CIRData54: start 464, 8 bit, little-endian, data-type-policy=OVERRIDE, base-type=uint8, compu {phys=raw}, range phys 0..255
          signal StatusCPDData1FBD_HL_CIRData55: start 472, 8 bit, little-endian, data-type-policy=OVERRIDE, base-type=uint8, compu {phys=raw}, range phys 0..255
          signal StatusCPDData1FBD_HL_CIRData56: start 480, 8 bit, little-endian, data-type-policy=OVERRIDE, base-type=uint8, compu {phys=raw}, range phys 0..255
          signal StatusCPDData1FBD_HL_CIRData57: start 488, 8 bit, little-endian, data-type-policy=OVERRIDE, base-type=uint8, compu {phys=raw}, range phys 0..255
          signal StatusCPDData1FBD_HL_CIRData58: start 496, 8 bit, little-endian, data-type-policy=OVERRIDE, base-type=uint8, compu {phys=raw}, range phys 0..255
          signal StatusCPDData1FBD_HL_CIRData59: start 504, 8 bit, little-endian, data-type-policy=OVERRIDE, base-type=uint8, compu {phys=raw}, range phys 0..255
      frame StatusCPDData1FBD_HM: id 0x14B, frame-length=64, can-addressing-mode=STANDARD, can-frame-rx-behavior=CAN-FD, can-frame-tx-behavior=CAN-FD
        pdu StatusCPDData1FBD_HM: length=64, unused-bit-pattern=0
          signal StatusCPDData1FBD_HM_MsgCounter: start 0, 8 bit, little-endian, data-type-policy=OVERRIDE, base-type=uint8, compu {phys=raw}, range phys 0..252
          signal StatusCPDData1FBD_HM_LinkID: start 8, 8 bit, little-endian, data-type-policy=OVERRIDE, base-type=uint8, compu {phys=raw}, range phys 0..252
          signal StatusCPDData1FBD_HM_AGCValue: start 16, 8 bit, little-endian, data-type-policy=OVERRIDE, base-type=uint8, compu {phys=raw}, range phys 0..252
          signal StatusCPDData1FBD_HM_Channel: start 24, 8 bit, little-endian, data-type-policy=OVERRIDE, base-type=uint8, compu {phys=raw}, range phys 0..252
          signal StatusCPDData1FBD_HM_CIRData00: start 32, 8 bit, little-endian, data-type-policy=OVERRIDE, base-type=uint8, compu {phys=raw}, range phys 0..255
          signal StatusCPDData1FBD_HM_CIRData01: start 40, 8 bit, little-endian, data-type-policy=OVERRIDE, base-type=uint8, compu {phys=raw}, range phys 0..255
          signal StatusCPDData1FBD_HM_CIRData02: start 48, 8 bit, little-endian, data-type-policy=OVERRIDE, base-type=uint8, compu {phys=raw}, range phys 0..255
          signal StatusCPDData1FBD_HM_CIRData03: start 56, 8 bit, little-endian, data-type-policy=OVERRIDE, base-type=uint8, compu {phys=raw}, range phys 0..255
          signal StatusCPDData1FBD_HM_CIRData04: start 64, 8 bit, little-endian, data-type-policy=OVERRIDE, base-type=uint8, compu {phys=raw}, range phys 0..255
          signal StatusCPDData1FBD_HM_CIRData05: start 72, 8 bit, little-endian, data-type-policy=OVERRIDE, base-type=uint8, compu {phys=raw}, range phys 0..255
          signal StatusCPDData1FBD_HM_CIRData06: start 80, 8 bit, little-endian, data-type-policy=OVERRIDE, base-type=uint8, compu {phys=raw}, range phys 0..255
          signal StatusCPDData1FBD_HM_CIRData07: start 88, 8 bit, little-endian, data-type-policy=OVERRIDE, base-type=uint8, compu {phys=raw}, range phys 0..255
          signal StatusCPDData1FBD_HM_CIRData08: start 96, 8 bit, little-endian, data-type-policy=OVERRIDE, base-type=uint8, compu {phys=raw}, range phys 0..255
          signal StatusCPDData1FBD_HM_CIRData09: start 104, 8 bit, little-endian, data-type-policy=OVERRIDE, base-type=uint8, compu {phys=raw}, range phys 0..255
          signal StatusCPDData1FBD_HM_CIRData10: start 112, 8 bit, little-endian, data-type-policy=OVERRIDE, base-type=uint8, compu {phys=raw}, range phys 0..255
          signal StatusCPDData1FBD_HM_CIRData11: start 120, 8 bit, little-endian, data-type-policy=OVERRIDE, base-type=uint8, compu {phys=raw}, range phys 0..255
          signal StatusCPDData1FBD_HM_CIRData12: start 128, 8 bit, little-endian, data-type-policy=OVERRIDE, base-type=uint8, compu {phys=raw}, range phys 0..255
          signal StatusCPDData1FBD_HM_CIRData13: start 136, 8 bit, little-endian, data-type-policy=OVERRIDE, base-type=uint8, compu {phys=raw}, range phys 0..255
          signal StatusCPDData1FBD_HM_CIRData14: start 144, 8 bit, little-endian, data-type-policy=OVERRIDE, base-type=uint8, compu {phys=raw}, range phys 0..255
          signal StatusCPDData1FBD_HM_CIRData15: start 152, 8 bit, little-endian, data-type-policy=OVERRIDE, base-type=uint8, compu {phys=raw}, range phys 0..255
          signal StatusCPDData1FBD_HM_CIRData16: start 160, 8 bit, little-endian, data-type-policy=OVERRIDE, base-type=uint8, compu {phys=raw}, range phys 0..255
          signal StatusCPDData1FBD_HM_CIRData17: start 168, 8 bit, little-endian, data-type-policy=OVERRIDE, base-type=uint8, compu {phys=raw}, range phys 0..255
          signal StatusCPDData1FBD_HM_CIRData18: start 176, 8 bit, little-endian, data-type-policy=OVERRIDE, base-type=uint8, compu {phys=raw}, range phys 0..255
          signal StatusCPDData1FBD_HM_CIRData19: start 184, 8 bit, little-endian, data-type-policy=OVERRIDE, base-type=uint8, compu {phys=raw}, range phys 0..255
          signal StatusCPDData1FBD_HM_CIRData20: start 192, 8 bit, little-endian, data-type-policy=OVERRIDE, base-type=uint8, compu {phys=raw}, range phys 0..255
          signal StatusCPDData1FBD_HM_CIRData21: start 200, 8 bit, little-endian, data-type-policy=OVERRIDE, base-type=uint8, compu {phys=raw}, range phys 0..255
          signal StatusCPDData1FBD_HM_CIRData22: start 208, 8 bit, little-endian, data-type-policy=OVERRIDE, base-type=uint8, compu {phys=raw}, range phys 0..255
          signal StatusCPDData1FBD_HM_CIRData23: start 216, 8 bit, little-endian, data-type-policy=OVERRIDE, base-type=uint8, compu {phys=raw}, range phys 0..255
          signal StatusCPDData1FBD_HM_CIRData24: start 224, 8 bit, little-endian, data-type-policy=OVERRIDE, base-type=uint8, compu {phys=raw}, range phys 0..255
          signal StatusCPDData1FBD_HM_CIRData25: start 232, 8 bit, little-endian, data-type-policy=OVERRIDE, base-type=uint8, compu {phys=raw}, range phys 0..255
          signal StatusCPDData1FBD_HM_CIRData26: start 240, 8 bit, little-endian, data-type-policy=OVERRIDE, base-type=uint8, compu {phys=raw}, range phys 0..255
          signal StatusCPDData1FBD_HM_CIRData27: start 248, 8 bit, little-endian, data-type-policy=OVERRIDE, base-type=uint8, compu {phys=raw}, range phys 0..255
          signal StatusCPDData1FBD_HM_CIRData28: start 256, 8 bit, little-endian, data-type-policy=OVERRIDE, base-type=uint8, compu {phys=raw}, range phys 0..255
          signal StatusCPDData1FBD_HM_CIRData29: start 264, 8 bit, little-endian, data-type-policy=OVERRIDE, base-type=uint8, compu {phys=raw}, range phys 0..255
          signal StatusCPDData1FBD_HM_CIRData30: start 272, 8 bit, little-endian, data-type-policy=OVERRIDE, base-type=uint8, compu {phys=raw}, range phys 0..255
          signal StatusCPDData1FBD_HM_CIRData31: start 280, 8 bit, little-endian, data-type-policy=OVERRIDE, base-type=uint8, compu {phys=raw}, range phys 0..255
          signal StatusCPDData1FBD_HM_CIRData32: start 288, 8 bit, little-endian, data-type-policy=OVERRIDE, base-type=uint8, compu {phys=raw}, range phys 0..255
          signal StatusCPDData1FBD_HM_CIRData33: start 296, 8 bit, little-endian, data-type-policy=OVERRIDE, base-type=uint8, compu {phys=raw}, range phys 0..255
          signal StatusCPDData1FBD_HM_CIRData34: start 304, 8 bit, little-endian, data-type-policy=OVERRIDE, base-type=uint8, compu {phys=raw}, range phys 0..255
          signal StatusCPDData1FBD_HM_CIRData35: start 312, 8 bit, little-endian, data-type-policy=OVERRIDE, base-type=uint8, compu {phys=raw}, range phys 0..255
          signal StatusCPDData1FBD_HM_CIRData36: start 320, 8 bit, little-endian, data-type-policy=OVERRIDE, base-type=uint8, compu {phys=raw}, range phys 0..255
          signal StatusCPDData1FBD_HM_CIRData37: start 328, 8 bit, little-endian, data-type-policy=OVERRIDE, base-type=uint8, compu {phys=raw}, range phys 0..255
          signal StatusCPDData1FBD_HM_CIRData38: start 336, 8 bit, little-endian, data-type-policy=OVERRIDE, base-type=uint8, compu {phys=raw}, range phys 0..255
          signal StatusCPDData1FBD_HM_CIRData39: start 344, 8 bit, little-endian, data-type-policy=OVERRIDE, base-type=uint8, compu {phys=raw}, range phys 0..255
          signal StatusCPDData1FBD_HM_CIRData40: start 352, 8 bit, little-endian, data-type-policy=OVERRIDE, base-type=uint8, compu {phys=raw}, range phys 0..255
          signal StatusCPDData1FBD_HM_CIRData41: start 360, 8 bit, little-endian, data-type-policy=OVERRIDE, base-type=uint8, compu {phys=raw}, range phys 0..255
          signal StatusCPDData1FBD_HM_CIRData42: start 368, 8 bit, little-endian, data-type-policy=OVERRIDE, base-type=uint8, compu {phys=raw}, range phys 0..255
          signal StatusCPDData1FBD_HM_CIRData43: start 376, 8 bit, little-endian, data-type-policy=OVERRIDE, base-type=uint8, compu {phys=raw}, range phys 0..255
          signal StatusCPDData1FBD_HM_CIRData44: start 384, 8 bit, little-endian, data-type-policy=OVERRIDE, base-type=uint8, compu {phys=raw}, range phys 0..255
          signal StatusCPDData1FBD_HM_CIRData45: start 392, 8 bit, little-endian, data-type-policy=OVERRIDE, base-type=uint8, compu {phys=raw}, range phys 0..255
          signal StatusCPDData1FBD_HM_CIRData46: start 400, 8 bit, little-endian, data-type-policy=OVERRIDE, base-type=uint8, compu {phys=raw}, range phys 0..255
          signal StatusCPDData1FBD_HM_CIRData47: start 408, 8 bit, little-endian, data-type-policy=OVERRIDE, base-type=uint8, compu {phys=raw}, range phys 0..255
          signal StatusCPDData1FBD_HM_CIRData48: start 416, 8 bit, little-endian, data-type-policy=OVERRIDE, base-type=uint8, compu {phys=raw}, range phys 0..255
          signal StatusCPDData1FBD_HM_CIRData49: start 424, 8 bit, little-endian, data-type-policy=OVERRIDE, base-type=uint8, compu {phys=raw}, range phys 0..255
          signal StatusCPDData1FBD_HM_CIRData50: start 432, 8 bit, little-endian, data-type-policy=OVERRIDE, base-type=uint8, compu {phys=raw}, range phys 0..255
          signal StatusCPDData1FBD_HM_CIRData51: start 440, 8 bit, little-endian, data-type-policy=OVERRIDE, base-type=uint8, compu {phys=raw}, range phys 0..255
          signal StatusCPDData1FBD_HM_CIRData52: start 448, 8 bit, little-endian, data-type-policy=OVERRIDE, base-type=uint8, compu {phys=raw}, range phys 0..255
          signal StatusCPDData1FBD_HM_CIRData53: start 456, 8 bit, little-endian, data-type-policy=OVERRIDE, base-type=uint8, compu {phys=raw}, range phys 0..255
          signal StatusCPDData1FBD_HM_CIRData54: start 464, 8 bit, little-endian, data-type-policy=OVERRIDE, base-type=uint8, compu {phys=raw}, range phys 0..255
          signal StatusCPDData1FBD_HM_CIRData55: start 472, 8 bit, little-endian, data-type-policy=OVERRIDE, base-type=uint8, compu {phys=raw}, range phys 0..255
          signal StatusCPDData1FBD_HM_CIRData56: start 480, 8 bit, little-endian, data-type-policy=OVERRIDE, base-type=uint8, compu {phys=raw}, range phys 0..255
          signal StatusCPDData1FBD_HM_CIRData57: start 488, 8 bit, little-endian, data-type-policy=OVERRIDE, base-type=uint8, compu {phys=raw}, range phys 0..255
          signal StatusCPDData1FBD_HM_CIRData58: start 496, 8 bit, little-endian, data-type-policy=OVERRIDE, base-type=uint8, compu {phys=raw}, range phys 0..255
          signal StatusCPDData1FBD_HM_CIRData59: start 504, 8 bit, little-endian, data-type-policy=OVERRIDE, base-type=uint8, compu {phys=raw}, range phys 0..255
      frame StatusCPDData1FBD_HR: id 0x151, frame-length=64, can-addressing-mode=STANDARD, can-frame-rx-behavior=CAN-FD, can-frame-tx-behavior=CAN-FD
        pdu StatusCPDData1FBD_HR: length=64, unused-bit-pattern=0
          signal StatusCPDData1FBD_HR_MsgCounter: start 0, 8 bit, little-endian, data-type-policy=OVERRIDE, base-type=uint8, compu {phys=raw}, range phys 0..252
          signal StatusCPDData1FBD_HR_LinkID: start 8, 8 bit, little-endian, data-type-policy=OVERRIDE, base-type=uint8, compu {phys=raw}, range phys 0..252
          signal StatusCPDData1FBD_HR_AGCValue: start 16, 8 bit, little-endian, data-type-policy=OVERRIDE, base-type=uint8, compu {phys=raw}, range phys 0..252
          signal StatusCPDData1FBD_HR_Channel: start 24, 8 bit, little-endian, data-type-policy=OVERRIDE, base-type=uint8, compu {phys=raw}, range phys 0..252
          signal StatusCPDData1FBD_HR_CIRData00: start 32, 8 bit, little-endian, data-type-policy=OVERRIDE, base-type=uint8, compu {phys=raw}, range phys 0..255
          signal StatusCPDData1FBD_HR_CIRData01: start 40, 8 bit, little-endian, data-type-policy=OVERRIDE, base-type=uint8, compu {phys=raw}, range phys 0..255
          signal StatusCPDData1FBD_HR_CIRData02: start 48, 8 bit, little-endian, data-type-policy=OVERRIDE, base-type=uint8, compu {phys=raw}, range phys 0..255
          signal StatusCPDData1FBD_HR_CIRData03: start 56, 8 bit, little-endian, data-type-policy=OVERRIDE, base-type=uint8, compu {phys=raw}, range phys 0..255
          signal StatusCPDData1FBD_HR_CIRData04: start 64, 8 bit, little-endian, data-type-policy=OVERRIDE, base-type=uint8, compu {phys=raw}, range phys 0..255
          signal StatusCPDData1FBD_HR_CIRData05: start 72, 8 bit, little-endian, data-type-policy=OVERRIDE, base-type=uint8, compu {phys=raw}, range phys 0..255
          signal StatusCPDData1FBD_HR_CIRData06: start 80, 8 bit, little-endian, data-type-policy=OVERRIDE, base-type=uint8, compu {phys=raw}, range phys 0..255
          signal StatusCPDData1FBD_HR_CIRData07: start 88, 8 bit, little-endian, data-type-policy=OVERRIDE, base-type=uint8, compu {phys=raw}, range phys 0..255
          signal StatusCPDData1FBD_HR_CIRData08: start 96, 8 bit, little-endian, data-type-policy=OVERRIDE, base-type=uint8, compu {phys=raw}, range phys 0..255
          signal StatusCPDData1FBD_HR_CIRData09: start 104, 8 bit, little-endian, data-type-policy=OVERRIDE, base-type=uint8, compu {phys=raw}, range phys 0..255
          signal StatusCPDData1FBD_HR_CIRData10: start 112, 8 bit, little-endian, data-type-policy=OVERRIDE, base-type=uint8, compu {phys=raw}, range phys 0..255
          signal StatusCPDData1FBD_HR_CIRData11: start 120, 8 bit, little-endian, data-type-policy=OVERRIDE, base-type=uint8, compu {phys=raw}, range phys 0..255
          signal StatusCPDData1FBD_HR_CIRData12: start 128, 8 bit, little-endian, data-type-policy=OVERRIDE, base-type=uint8, compu {phys=raw}, range phys 0..255
          signal StatusCPDData1FBD_HR_CIRData13: start 136, 8 bit, little-endian, data-type-policy=OVERRIDE, base-type=uint8, compu {phys=raw}, range phys 0..255
          signal StatusCPDData1FBD_HR_CIRData14: start 144, 8 bit, little-endian, data-type-policy=OVERRIDE, base-type=uint8, compu {phys=raw}, range phys 0..255
          signal StatusCPDData1FBD_HR_CIRData15: start 152, 8 bit, little-endian, data-type-policy=OVERRIDE, base-type=uint8, compu {phys=raw}, range phys 0..255
          signal StatusCPDData1FBD_HR_CIRData16: start 160, 8 bit, little-endian, data-type-policy=OVERRIDE, base-type=uint8, compu {phys=raw}, range phys 0..255
          signal StatusCPDData1FBD_HR_CIRData17: start 168, 8 bit, little-endian, data-type-policy=OVERRIDE, base-type=uint8, compu {phys=raw}, range phys 0..255
          signal StatusCPDData1FBD_HR_CIRData18: start 176, 8 bit, little-endian, data-type-policy=OVERRIDE, base-type=uint8, compu {phys=raw}, range phys 0..255
          signal StatusCPDData1FBD_HR_CIRData19: start 184, 8 bit, little-endian, data-type-policy=OVERRIDE, base-type=uint8, compu {phys=raw}, range phys 0..255
          signal StatusCPDData1FBD_HR_CIRData20: start 192, 8 bit, little-endian, data-type-policy=OVERRIDE, base-type=uint8, compu {phys=raw}, range phys 0..255
          signal StatusCPDData1FBD_HR_CIRData21: start 200, 8 bit, little-endian, data-type-policy=OVERRIDE, base-type=uint8, compu {phys=raw}, range phys 0..255
          signal StatusCPDData1FBD_HR_CIRData22: start 208, 8 bit, little-endian, data-type-policy=OVERRIDE, base-type=uint8, compu {phys=raw}, range phys 0..255
          signal StatusCPDData1FBD_HR_CIRData23: start 216, 8 bit, little-endian, data-type-policy=OVERRIDE, base-type=uint8, compu {phys=raw}, range phys 0..255
          signal StatusCPDData1FBD_HR_CIRData24: start 224, 8 bit, little-endian, data-type-policy=OVERRIDE, base-type=uint8, compu {phys=raw}, range phys 0..255
          signal StatusCPDData1FBD_HR_CIRData25: start 232, 8 bit, little-endian, data-type-policy=OVERRIDE, base-type=uint8, compu {phys=raw}, range phys 0..255
          signal StatusCPDData1FBD_HR_CIRData26: start 240, 8 bit, little-endian, data-type-policy=OVERRIDE, base-type=uint8, compu {phys=raw}, range phys 0..255
          signal StatusCPDData1FBD_HR_CIRData27: start 248, 8 bit, little-endian, data-type-policy=OVERRIDE, base-type=uint8, compu {phys=raw}, range phys 0..255
          signal StatusCPDData1FBD_HR_CIRData28: start 256, 8 bit, little-endian, data-type-policy=OVERRIDE, base-type=uint8, compu {phys=raw}, range phys 0..255
          signal StatusCPDData1FBD_HR_CIRData29: start 264, 8 bit, little-endian, data-type-policy=OVERRIDE, base-type=uint8, compu {phys=raw}, range phys 0..255
          signal StatusCPDData1FBD_HR_CIRData30: start 272, 8 bit, little-endian, data-type-policy=OVERRIDE, base-type=uint8, compu {phys=raw}, range phys 0..255
          signal StatusCPDData1FBD_HR_CIRData31: start 280, 8 bit, little-endian, data-type-policy=OVERRIDE, base-type=uint8, compu {phys=raw}, range phys 0..255
          signal StatusCPDData1FBD_HR_CIRData32: start 288, 8 bit, little-endian, data-type-policy=OVERRIDE, base-type=uint8, compu {phys=raw}, range phys 0..255
          signal StatusCPDData1FBD_HR_CIRData33: start 296, 8 bit, little-endian, data-type-policy=OVERRIDE, base-type=uint8, compu {phys=raw}, range phys 0..255
          signal StatusCPDData1FBD_HR_CIRData34: start 304, 8 bit, little-endian, data-type-policy=OVERRIDE, base-type=uint8, compu {phys=raw}, range phys 0..255
          signal StatusCPDData1FBD_HR_CIRData35: start 312, 8 bit, little-endian, data-type-policy=OVERRIDE, base-type=uint8, compu {phys=raw}, range phys 0..255
          signal StatusCPDData1FBD_HR_CIRData36: start 320, 8 bit, little-endian, data-type-policy=OVERRIDE, base-type=uint8, compu {phys=raw}, range phys 0..255
          signal StatusCPDData1FBD_HR_CIRData37: start 328, 8 bit, little-endian, data-type-policy=OVERRIDE, base-type=uint8, compu {phys=raw}, range phys 0..255
          signal StatusCPDData1FBD_HR_CIRData38: start 336, 8 bit, little-endian, data-type-policy=OVERRIDE, base-type=uint8, compu {phys=raw}, range phys 0..255
          signal StatusCPDData1FBD_HR_CIRData39: start 344, 8 bit, little-endian, data-type-policy=OVERRIDE, base-type=uint8, compu {phys=raw}, range phys 0..255
          signal StatusCPDData1FBD_HR_CIRData40: start 352, 8 bit, little-endian, data-type-policy=OVERRIDE, base-type=uint8, compu {phys=raw}, range phys 0..255
          signal StatusCPDData1FBD_HR_CIRData41: start 360, 8 bit, little-endian, data-type-policy=OVERRIDE, base-type=uint8, compu {phys=raw}, range phys 0..255
          signal StatusCPDData1FBD_HR_CIRData42: start 368, 8 bit, little-endian, data-type-policy=OVERRIDE, base-type=uint8, compu {phys=raw}, range phys 0..255
          signal StatusCPDData1FBD_HR_CIRData43: start 376, 8 bit, little-endian, data-type-policy=OVERRIDE, base-type=uint8, compu {phys=raw}, range phys 0..255
          signal StatusCPDData1FBD_HR_CIRData44: start 384, 8 bit, little-endian, data-type-policy=OVERRIDE, base-type=uint8, compu {phys=raw}, range phys 0..255
          signal StatusCPDData1FBD_HR_CIRData45: start 392, 8 bit, little-endian, data-type-policy=OVERRIDE, base-type=uint8, compu {phys=raw}, range phys 0..255
          signal StatusCPDData1FBD_HR_CIRData46: start 400, 8 bit, little-endian, data-type-policy=OVERRIDE, base-type=uint8, compu {phys=raw}, range phys 0..255
          signal StatusCPDData1FBD_HR_CIRData47: start 408, 8 bit, little-endian, data-type-policy=OVERRIDE, base-type=uint8, compu {phys=raw}, range phys 0..255
          signal StatusCPDData1FBD_HR_CIRData48: start 416, 8 bit, little-endian, data-type-policy=OVERRIDE, base-type=uint8, compu {phys=raw}, range phys 0..255
          signal StatusCPDData1FBD_HR_CIRData49: start 424, 8 bit, little-endian, data-type-policy=OVERRIDE, base-type=uint8, compu {phys=raw}, range phys 0..255
          signal StatusCPDData1FBD_HR_CIRData50: start 432, 8 bit, little-endian, data-type-policy=OVERRIDE, base-type=uint8, compu {phys=raw}, range phys 0..255
          signal StatusCPDData1FBD_HR_CIRData51: start 440, 8 bit, little-endian, data-type-policy=OVERRIDE, base-type=uint8, compu {phys=raw}, range phys 0..255
          signal StatusCPDData1FBD_HR_CIRData52: start 448, 8 bit, little-endian, data-type-policy=OVERRIDE, base-type=uint8, compu {phys=raw}, range phys 0..255
          signal StatusCPDData1FBD_HR_CIRData53: start 456, 8 bit, little-endian, data-type-policy=OVERRIDE, base-type=uint8, compu {phys=raw}, range phys 0..255
          signal StatusCPDData1FBD_HR_CIRData54: start 464, 8 bit, little-endian, data-type-policy=OVERRIDE, base-type=uint8, compu {phys=raw}, range phys 0..255
          signal StatusCPDData1FBD_HR_CIRData55: start 472, 8 bit, little-endian, data-type-policy=OVERRIDE, base-type=uint8, compu {phys=raw}, range phys 0..255
          signal StatusCPDData1FBD_HR_CIRData56: start 480, 8 bit, little-endian, data-type-policy=OVERRIDE, base-type=uint8, compu {phys=raw}, range phys 0..255
          signal StatusCPDData1FBD_HR_CIRData57: start 488, 8 bit, little-endian, data-type-policy=OVERRIDE, base-type=uint8, compu {phys=raw}, range phys 0..255
          signal StatusCPDData1FBD_HR_CIRData58: start 496, 8 bit, little-endian, data-type-policy=OVERRIDE, base-type=uint8, compu {phys=raw}, range phys 0..255
          signal StatusCPDData1FBD_HR_CIRData59: start 504, 8 bit, little-endian, data-type-policy=OVERRIDE, base-type=uint8, compu {phys=raw}, range phys 0..255
      frame StatusCPDData1FBD_Miko: id 0x14C, frame-length=64, can-addressing-mode=STANDARD, can-frame-rx-behavior=CAN-FD, can-frame-tx-behavior=CAN-FD
        pdu StatusCPDData1FBD_Miko: length=64, unused-bit-pattern=0
          signal StatusCPDData1FBD_Miko_MsgCounter: start 0, 8 bit, little-endian, data-type-policy=OVERRIDE, base-type=uint8, compu {phys=raw}, range phys 0..252
          signal StatusCPDData1FBD_Miko_LinkID: start 8, 8 bit, little-endian, data-type-policy=OVERRIDE, base-type=uint8, compu {phys=raw}, range phys 0..252
          signal StatusCPDData1FBD_Miko_AGCValue: start 16, 8 bit, little-endian, data-type-policy=OVERRIDE, base-type=uint8, compu {phys=raw}, range phys 0..252
          signal StatusCPDData1FBD_Miko_Channel: start 24, 8 bit, little-endian, data-type-policy=OVERRIDE, base-type=uint8, compu {phys=raw}, range phys 0..252
          signal StatusCPDData1FBD_Miko_CIRData00: start 32, 8 bit, little-endian, data-type-policy=OVERRIDE, base-type=uint8, compu {phys=raw}, range phys 0..255
          signal StatusCPDData1FBD_Miko_CIRData01: start 40, 8 bit, little-endian, data-type-policy=OVERRIDE, base-type=uint8, compu {phys=raw}, range phys 0..255
          signal StatusCPDData1FBD_Miko_CIRData02: start 48, 8 bit, little-endian, data-type-policy=OVERRIDE, base-type=uint8, compu {phys=raw}, range phys 0..255
          signal StatusCPDData1FBD_Miko_CIRData03: start 56, 8 bit, little-endian, data-type-policy=OVERRIDE, base-type=uint8, compu {phys=raw}, range phys 0..255
          signal StatusCPDData1FBD_Miko_CIRData04: start 64, 8 bit, little-endian, data-type-policy=OVERRIDE, base-type=uint8, compu {phys=raw}, range phys 0..255
          signal StatusCPDData1FBD_Miko_CIRData05: start 72, 8 bit, little-endian, data-type-policy=OVERRIDE, base-type=uint8, compu {phys=raw}, range phys 0..255
          signal StatusCPDData1FBD_Miko_CIRData06: start 80, 8 bit, little-endian, data-type-policy=OVERRIDE, base-type=uint8, compu {phys=raw}, range phys 0..255
          signal StatusCPDData1FBD_Miko_CIRData07: start 88, 8 bit, little-endian, data-type-policy=OVERRIDE, base-type=uint8, compu {phys=raw}, range phys 0..255
          signal StatusCPDData1FBD_Miko_CIRData08: start 96, 8 bit, little-endian, data-type-policy=OVERRIDE, base-type=uint8, compu {phys=raw}, range phys 0..255
          signal StatusCPDData1FBD_Miko_CIRData09: start 104, 8 bit, little-endian, data-type-policy=OVERRIDE, base-type=uint8, compu {phys=raw}, range phys 0..255
          signal StatusCPDData1FBD_Miko_CIRData10: start 112, 8 bit, little-endian, data-type-policy=OVERRIDE, base-type=uint8, compu {phys=raw}, range phys 0..255
          signal StatusCPDData1FBD_Miko_CIRData11: start 120, 8 bit, little-endian, data-type-policy=OVERRIDE, base-type=uint8, compu {phys=raw}, range phys 0..255
          signal StatusCPDData1FBD_Miko_CIRData12: start 128, 8 bit, little-endian, data-type-policy=OVERRIDE, base-type=uint8, compu {phys=raw}, range phys 0..255
          signal StatusCPDData1FBD_Miko_CIRData13: start 136, 8 bit, little-endian, data-type-policy=OVERRIDE, base-type=uint8, compu {phys=raw}, range phys 0..255
          signal StatusCPDData1FBD_Miko_CIRData14: start 144, 8 bit, little-endian, data-type-policy=OVERRIDE, base-type=uint8, compu {phys=raw}, range phys 0..255
          signal StatusCPDData1FBD_Miko_CIRData15: start 152, 8 bit, little-endian, data-type-policy=OVERRIDE, base-type=uint8, compu {phys=raw}, range phys 0..255
          signal StatusCPDData1FBD_Miko_CIRData16: start 160, 8 bit, little-endian, data-type-policy=OVERRIDE, base-type=uint8, compu {phys=raw}, range phys 0..255
          signal StatusCPDData1FBD_Miko_CIRData17: start 168, 8 bit, little-endian, data-type-policy=OVERRIDE, base-type=uint8, compu {phys=raw}, range phys 0..255
          signal StatusCPDData1FBD_Miko_CIRData18: start 176, 8 bit, little-endian, data-type-policy=OVERRIDE, base-type=uint8, compu {phys=raw}, range phys 0..255
          signal StatusCPDData1FBD_Miko_CIRData19: start 184, 8 bit, little-endian, data-type-policy=OVERRIDE, base-type=uint8, compu {phys=raw}, range phys 0..255
          signal StatusCPDData1FBD_Miko_CIRData20: start 192, 8 bit, little-endian, data-type-policy=OVERRIDE, base-type=uint8, compu {phys=raw}, range phys 0..255
          signal StatusCPDData1FBD_Miko_CIRData21: start 200, 8 bit, little-endian, data-type-policy=OVERRIDE, base-type=uint8, compu {phys=raw}, range phys 0..255
          signal StatusCPDData1FBD_Miko_CIRData22: start 208, 8 bit, little-endian, data-type-policy=OVERRIDE, base-type=uint8, compu {phys=raw}, range phys 0..255
          signal StatusCPDData1FBD_Miko_CIRData23: start 216, 8 bit, little-endian, data-type-policy=OVERRIDE, base-type=uint8, compu {phys=raw}, range phys 0..255
          signal StatusCPDData1FBD_Miko_CIRData24: start 224, 8 bit, little-endian, data-type-policy=OVERRIDE, base-type=uint8, compu {phys=raw}, range phys 0..255
          signal StatusCPDData1FBD_Miko_CIRData25: start 232, 8 bit, little-endian, data-type-policy=OVERRIDE, base-type=uint8, compu {phys=raw}, range phys 0..255
          signal StatusCPDData1FBD_Miko_CIRData26: start 240, 8 bit, little-endian, data-type-policy=OVERRIDE, base-type=uint8, compu {phys=raw}, range phys 0..255
          signal StatusCPDData1FBD_Miko_CIRData27: start 248, 8 bit, little-endian, data-type-policy=OVERRIDE, base-type=uint8, compu {phys=raw}, range phys 0..255
          signal StatusCPDData1FBD_Miko_CIRData28: start 256, 8 bit, little-endian, data-type-policy=OVERRIDE, base-type=uint8, compu {phys=raw}, range phys 0..255
          signal StatusCPDData1FBD_Miko_CIRData29: start 264, 8 bit, little-endian, data-type-policy=OVERRIDE, base-type=uint8, compu {phys=raw}, range phys 0..255
          signal StatusCPDData1FBD_Miko_CIRData30: start 272, 8 bit, little-endian, data-type-policy=OVERRIDE, base-type=uint8, compu {phys=raw}, range phys 0..255
          signal StatusCPDData1FBD_Miko_CIRData31: start 280, 8 bit, little-endian, data-type-policy=OVERRIDE, base-type=uint8, compu {phys=raw}, range phys 0..255
          signal StatusCPDData1FBD_Miko_CIRData32: start 288, 8 bit, little-endian, data-type-policy=OVERRIDE, base-type=uint8, compu {phys=raw}, range phys 0..255
          signal StatusCPDData1FBD_Miko_CIRData33: start 296, 8 bit, little-endian, data-type-policy=OVERRIDE, base-type=uint8, compu {phys=raw}, range phys 0..255
          signal StatusCPDData1FBD_Miko_CIRData34: start 304, 8 bit, little-endian, data-type-policy=OVERRIDE, base-type=uint8, compu {phys=raw}, range phys 0..255
          signal StatusCPDData1FBD_Miko_CIRData35: start 312, 8 bit, little-endian, data-type-policy=OVERRIDE, base-type=uint8, compu {phys=raw}, range phys 0..255
          signal StatusCPDData1FBD_Miko_CIRData36: start 320, 8 bit, little-endian, data-type-policy=OVERRIDE, base-type=uint8, compu {phys=raw}, range phys 0..255
          signal StatusCPDData1FBD_Miko_CIRData37: start 328, 8 bit, little-endian, data-type-policy=OVERRIDE, base-type=uint8, compu {phys=raw}, range phys 0..255
          signal StatusCPDData1FBD_Miko_CIRData38: start 336, 8 bit, little-endian, data-type-policy=OVERRIDE, base-type=uint8, compu {phys=raw}, range phys 0..255
          signal StatusCPDData1FBD_Miko_CIRData39: start 344, 8 bit, little-endian, data-type-policy=OVERRIDE, base-type=uint8, compu {phys=raw}, range phys 0..255
          signal StatusCPDData1FBD_Miko_CIRData40: start 352, 8 bit, little-endian, data-type-policy=OVERRIDE, base-type=uint8, compu {phys=raw}, range phys 0..255
          signal StatusCPDData1FBD_Miko_CIRData41: start 360, 8 bit, little-endian, data-type-policy=OVERRIDE, base-type=uint8, compu {phys=raw}, range phys 0..255
          signal StatusCPDData1FBD_Miko_CIRData42: start 368, 8 bit, little-endian, data-type-policy=OVERRIDE, base-type=uint8, compu {phys=raw}, range phys 0..255
          signal StatusCPDData1FBD_Miko_CIRData43: start 376, 8 bit, little-endian, data-type-policy=OVERRIDE, base-type=uint8, compu {phys=raw}, range phys 0..255
          signal StatusCPDData1FBD_Miko_CIRData44: start 384, 8 bit, little-endian, data-type-policy=OVERRIDE, base-type=uint8, compu {phys=raw}, range phys 0..255
          signal StatusCPDData1FBD_Miko_CIRData45: start 392, 8 bit, little-endian, data-type-policy=OVERRIDE, base-type=uint8, compu {phys=raw}, range phys 0..255
          signal StatusCPDData1FBD_Miko_CIRData46: start 400, 8 bit, little-endian, data-type-policy=OVERRIDE, base-type=uint8, compu {phys=raw}, range phys 0..255
          signal StatusCPDData1FBD_Miko_CIRData47: start 408, 8 bit, little-endian, data-type-policy=OVERRIDE, base-type=uint8, compu {phys=raw}, range phys 0..255
          signal StatusCPDData1FBD_Miko_CIRData48: start 416, 8 bit, little-endian, data-type-policy=OVERRIDE, base-type=uint8, compu {phys=raw}, range phys 0..255
          signal StatusCPDData1FBD_Miko_CIRData49: start 424, 8 bit, little-endian, data-type-policy=OVERRIDE, base-type=uint8, compu {phys=raw}, range phys 0..255
          signal StatusCPDData1FBD_Miko_CIRData50: start 432, 8 bit, little-endian, data-type-policy=OVERRIDE, base-type=uint8, compu {phys=raw}, range phys 0..255
          signal StatusCPDData1FBD_Miko_CIRData51: start 440, 8 bit, little-endian, data-type-policy=OVERRIDE, base-type=uint8, compu {phys=raw}, range phys 0..255
          signal StatusCPDData1FBD_Miko_CIRData52: start 448, 8 bit, little-endian, data-type-policy=OVERRIDE, base-type=uint8, compu {phys=raw}, range phys 0..255
          signal StatusCPDData1FBD_Miko_CIRData53: start 456, 8 bit, little-endian, data-type-policy=OVERRIDE, base-type=uint8, compu {phys=raw}, range phys 0..255
          signal StatusCPDData1FBD_Miko_CIRData54: start 464, 8 bit, little-endian, data-type-policy=OVERRIDE, base-type=uint8, compu {phys=raw}, range phys 0..255
          signal StatusCPDData1FBD_Miko_CIRData55: start 472, 8 bit, little-endian, data-type-policy=OVERRIDE, base-type=uint8, compu {phys=raw}, range phys 0..255
          signal StatusCPDData1FBD_Miko_CIRData56: start 480, 8 bit, little-endian, data-type-policy=OVERRIDE, base-type=uint8, compu {phys=raw}, range phys 0..255
          signal StatusCPDData1FBD_Miko_CIRData57: start 488, 8 bit, little-endian, data-type-policy=OVERRIDE, base-type=uint8, compu {phys=raw}, range phys 0..255
          signal StatusCPDData1FBD_Miko_CIRData58: start 496, 8 bit, little-endian, data-type-policy=OVERRIDE, base-type=uint8, compu {phys=raw}, range phys 0..255
          signal StatusCPDData1FBD_Miko_CIRData59: start 504, 8 bit, little-endian, data-type-policy=OVERRIDE, base-type=uint8, compu {phys=raw}, range phys 0..255
      frame StatusCPDData1FBD_MM: id 0x341, frame-length=64, can-addressing-mode=STANDARD, can-frame-rx-behavior=CAN-FD, can-frame-tx-behavior=CAN-FD
        pdu StatusCPDData1FBD_MM: length=64, unused-bit-pattern=0
          signal StatusCPDData1FBD_MM_MsgCounter: start 0, 8 bit, little-endian, data-type-policy=OVERRIDE, base-type=uint8, compu {phys=raw}, range phys 0..252
          signal StatusCPDData1FBD_MM_LinkID: start 8, 8 bit, little-endian, data-type-policy=OVERRIDE, base-type=uint8, compu {phys=raw}, range phys 0..252
          signal StatusCPDData1FBD_MM_AGCValue: start 16, 8 bit, little-endian, data-type-policy=OVERRIDE, base-type=uint8, compu {phys=raw}, range phys 0..252
          signal StatusCPDData1FBD_MM_Channel: start 24, 8 bit, little-endian, data-type-policy=OVERRIDE, base-type=uint8, compu {phys=raw}, range phys 0..252
          signal StatusCPDData1FBD_MM_CIRData00: start 32, 8 bit, little-endian, data-type-policy=OVERRIDE, base-type=uint8, compu {phys=raw}, range phys 0..255
          signal StatusCPDData1FBD_MM_CIRData01: start 40, 8 bit, little-endian, data-type-policy=OVERRIDE, base-type=uint8, compu {phys=raw}, range phys 0..255
          signal StatusCPDData1FBD_MM_CIRData02: start 48, 8 bit, little-endian, data-type-policy=OVERRIDE, base-type=uint8, compu {phys=raw}, range phys 0..255
          signal StatusCPDData1FBD_MM_CIRData03: start 56, 8 bit, little-endian, data-type-policy=OVERRIDE, base-type=uint8, compu {phys=raw}, range phys 0..255
          signal StatusCPDData1FBD_MM_CIRData04: start 64, 8 bit, little-endian, data-type-policy=OVERRIDE, base-type=uint8, compu {phys=raw}, range phys 0..255
          signal StatusCPDData1FBD_MM_CIRData05: start 72, 8 bit, little-endian, data-type-policy=OVERRIDE, base-type=uint8, compu {phys=raw}, range phys 0..255
          signal StatusCPDData1FBD_MM_CIRData06: start 80, 8 bit, little-endian, data-type-policy=OVERRIDE, base-type=uint8, compu {phys=raw}, range phys 0..255
          signal StatusCPDData1FBD_MM_CIRData07: start 88, 8 bit, little-endian, data-type-policy=OVERRIDE, base-type=uint8, compu {phys=raw}, range phys 0..255
          signal StatusCPDData1FBD_MM_CIRData08: start 96, 8 bit, little-endian, data-type-policy=OVERRIDE, base-type=uint8, compu {phys=raw}, range phys 0..255
          signal StatusCPDData1FBD_MM_CIRData09: start 104, 8 bit, little-endian, data-type-policy=OVERRIDE, base-type=uint8, compu {phys=raw}, range phys 0..255
          signal StatusCPDData1FBD_MM_CIRData10: start 112, 8 bit, little-endian, data-type-policy=OVERRIDE, base-type=uint8, compu {phys=raw}, range phys 0..255
          signal StatusCPDData1FBD_MM_CIRData11: start 120, 8 bit, little-endian, data-type-policy=OVERRIDE, base-type=uint8, compu {phys=raw}, range phys 0..255
          signal StatusCPDData1FBD_MM_CIRData12: start 128, 8 bit, little-endian, data-type-policy=OVERRIDE, base-type=uint8, compu {phys=raw}, range phys 0..255
          signal StatusCPDData1FBD_MM_CIRData13: start 136, 8 bit, little-endian, data-type-policy=OVERRIDE, base-type=uint8, compu {phys=raw}, range phys 0..255
          signal StatusCPDData1FBD_MM_CIRData14: start 144, 8 bit, little-endian, data-type-policy=OVERRIDE, base-type=uint8, compu {phys=raw}, range phys 0..255
          signal StatusCPDData1FBD_MM_CIRData15: start 152, 8 bit, little-endian, data-type-policy=OVERRIDE, base-type=uint8, compu {phys=raw}, range phys 0..255
          signal StatusCPDData1FBD_MM_CIRData16: start 160, 8 bit, little-endian, data-type-policy=OVERRIDE, base-type=uint8, compu {phys=raw}, range phys 0..255
          signal StatusCPDData1FBD_MM_CIRData17: start 168, 8 bit, little-endian, data-type-policy=OVERRIDE, base-type=uint8, compu {phys=raw}, range phys 0..255
          signal StatusCPDData1FBD_MM_CIRData18: start 176, 8 bit, little-endian, data-type-policy=OVERRIDE, base-type=uint8, compu {phys=raw}, range phys 0..255
          signal StatusCPDData1FBD_MM_CIRData19: start 184, 8 bit, little-endian, data-type-policy=OVERRIDE, base-type=uint8, compu {phys=raw}, range phys 0..255
          signal StatusCPDData1FBD_MM_CIRData20: start 192, 8 bit, little-endian, data-type-policy=OVERRIDE, base-type=uint8, compu {phys=raw}, range phys 0..255
          signal StatusCPDData1FBD_MM_CIRData21: start 200, 8 bit, little-endian, data-type-policy=OVERRIDE, base-type=uint8, compu {phys=raw}, range phys 0..255
          signal StatusCPDData1FBD_MM_CIRData22: start 208, 8 bit, little-endian, data-type-policy=OVERRIDE, base-type=uint8, compu {phys=raw}, range phys 0..255
          signal StatusCPDData1FBD_MM_CIRData23: start 216, 8 bit, little-endian, data-type-policy=OVERRIDE, base-type=uint8, compu {phys=raw}, range phys 0..255
          signal StatusCPDData1FBD_MM_CIRData24: start 224, 8 bit, little-endian, data-type-policy=OVERRIDE, base-type=uint8, compu {phys=raw}, range phys 0..255
          signal StatusCPDData1FBD_MM_CIRData25: start 232, 8 bit, little-endian, data-type-policy=OVERRIDE, base-type=uint8, compu {phys=raw}, range phys 0..255
          signal StatusCPDData1FBD_MM_CIRData26: start 240, 8 bit, little-endian, data-type-policy=OVERRIDE, base-type=uint8, compu {phys=raw}, range phys 0..255
          signal StatusCPDData1FBD_MM_CIRData27: start 248, 8 bit, little-endian, data-type-policy=OVERRIDE, base-type=uint8, compu {phys=raw}, range phys 0..255
          signal StatusCPDData1FBD_MM_CIRData28: start 256, 8 bit, little-endian, data-type-policy=OVERRIDE, base-type=uint8, compu {phys=raw}, range phys 0..255
          signal StatusCPDData1FBD_MM_CIRData29: start 264, 8 bit, little-endian, data-type-policy=OVERRIDE, base-type=uint8, compu {phys=raw}, range phys 0..255
          signal StatusCPDData1FBD_MM_CIRData30: start 272, 8 bit, little-endian, data-type-policy=OVERRIDE, base-type=uint8, compu {phys=raw}, range phys 0..255
          signal StatusCPDData1FBD_MM_CIRData31: start 280, 8 bit, little-endian, data-type-policy=OVERRIDE, base-type=uint8, compu {phys=raw}, range phys 0..255
          signal StatusCPDData1FBD_MM_CIRData32: start 288, 8 bit, little-endian, data-type-policy=OVERRIDE, base-type=uint8, compu {phys=raw}, range phys 0..255
          signal StatusCPDData1FBD_MM_CIRData33: start 296, 8 bit, little-endian, data-type-policy=OVERRIDE, base-type=uint8, compu {phys=raw}, range phys 0..255
          signal StatusCPDData1FBD_MM_CIRData34: start 304, 8 bit, little-endian, data-type-policy=OVERRIDE, base-type=uint8, compu {phys=raw}, range phys 0..255
          signal StatusCPDData1FBD_MM_CIRData35: start 312, 8 bit, little-endian, data-type-policy=OVERRIDE, base-type=uint8, compu {phys=raw}, range phys 0..255
          signal StatusCPDData1FBD_MM_CIRData36: start 320, 8 bit, little-endian, data-type-policy=OVERRIDE, base-type=uint8, compu {phys=raw}, range phys 0..255
          signal StatusCPDData1FBD_MM_CIRData37: start 328, 8 bit, little-endian, data-type-policy=OVERRIDE, base-type=uint8, compu {phys=raw}, range phys 0..255
          signal StatusCPDData1FBD_MM_CIRData38: start 336, 8 bit, little-endian, data-type-policy=OVERRIDE, base-type=uint8, compu {phys=raw}, range phys 0..255
          signal StatusCPDData1FBD_MM_CIRData39: start 344, 8 bit, little-endian, data-type-policy=OVERRIDE, base-type=uint8, compu {phys=raw}, range phys 0..255
          signal StatusCPDData1FBD_MM_CIRData40: start 352, 8 bit, little-endian, data-type-policy=OVERRIDE, base-type=uint8, compu {phys=raw}, range phys 0..255
          signal StatusCPDData1FBD_MM_CIRData41: start 360, 8 bit, little-endian, data-type-policy=OVERRIDE, base-type=uint8, compu {phys=raw}, range phys 0..255
          signal StatusCPDData1FBD_MM_CIRData42: start 368, 8 bit, little-endian, data-type-policy=OVERRIDE, base-type=uint8, compu {phys=raw}, range phys 0..255
          signal StatusCPDData1FBD_MM_CIRData43: start 376, 8 bit, little-endian, data-type-policy=OVERRIDE, base-type=uint8, compu {phys=raw}, range phys 0..255
          signal StatusCPDData1FBD_MM_CIRData44: start 384, 8 bit, little-endian, data-type-policy=OVERRIDE, base-type=uint8, compu {phys=raw}, range phys 0..255
          signal StatusCPDData1FBD_MM_CIRData45: start 392, 8 bit, little-endian, data-type-policy=OVERRIDE, base-type=uint8, compu {phys=raw}, range phys 0..255
          signal StatusCPDData1FBD_MM_CIRData46: start 400, 8 bit, little-endian, data-type-policy=OVERRIDE, base-type=uint8, compu {phys=raw}, range phys 0..255
          signal StatusCPDData1FBD_MM_CIRData47: start 408, 8 bit, little-endian, data-type-policy=OVERRIDE, base-type=uint8, compu {phys=raw}, range phys 0..255
          signal StatusCPDData1FBD_MM_CIRData48: start 416, 8 bit, little-endian, data-type-policy=OVERRIDE, base-type=uint8, compu {phys=raw}, range phys 0..255
          signal StatusCPDData1FBD_MM_CIRData49: start 424, 8 bit, little-endian, data-type-policy=OVERRIDE, base-type=uint8, compu {phys=raw}, range phys 0..255
          signal StatusCPDData1FBD_MM_CIRData50: start 432, 8 bit, little-endian, data-type-policy=OVERRIDE, base-type=uint8, compu {phys=raw}, range phys 0..255
          signal StatusCPDData1FBD_MM_CIRData51: start 440, 8 bit, little-endian, data-type-policy=OVERRIDE, base-type=uint8, compu {phys=raw}, range phys 0..255
          signal StatusCPDData1FBD_MM_CIRData52: start 448, 8 bit, little-endian, data-type-policy=OVERRIDE, base-type=uint8, compu {phys=raw}, range phys 0..255
          signal StatusCPDData1FBD_MM_CIRData53: start 456, 8 bit, little-endian, data-type-policy=OVERRIDE, base-type=uint8, compu {phys=raw}, range phys 0..255
          signal StatusCPDData1FBD_MM_CIRData54: start 464, 8 bit, little-endian, data-type-policy=OVERRIDE, base-type=uint8, compu {phys=raw}, range phys 0..255
          signal StatusCPDData1FBD_MM_CIRData55: start 472, 8 bit, little-endian, data-type-policy=OVERRIDE, base-type=uint8, compu {phys=raw}, range phys 0..255
          signal StatusCPDData1FBD_MM_CIRData56: start 480, 8 bit, little-endian, data-type-policy=OVERRIDE, base-type=uint8, compu {phys=raw}, range phys 0..255
          signal StatusCPDData1FBD_MM_CIRData57: start 488, 8 bit, little-endian, data-type-policy=OVERRIDE, base-type=uint8, compu {phys=raw}, range phys 0..255
          signal StatusCPDData1FBD_MM_CIRData58: start 496, 8 bit, little-endian, data-type-policy=OVERRIDE, base-type=uint8, compu {phys=raw}, range phys 0..255
          signal StatusCPDData1FBD_MM_CIRData59: start 504, 8 bit, little-endian, data-type-policy=OVERRIDE, base-type=uint8, compu {phys=raw}, range phys 0..255
      frame StatusCPDData1FBD_Trunk: id 0x14D, frame-length=64, can-addressing-mode=STANDARD, can-frame-rx-behavior=CAN-FD, can-frame-tx-behavior=CAN-FD
        pdu StatusCPDData1FBD_Trunk: length=64, unused-bit-pattern=0
          signal StatusCPDData1FBD_Trunk_MsgCounter: start 0, 8 bit, little-endian, data-type-policy=OVERRIDE, base-type=uint8, compu {phys=raw}, range phys 0..252
          signal StatusCPDData1FBD_Trunk_LinkID: start 8, 8 bit, little-endian, data-type-policy=OVERRIDE, base-type=uint8, compu {phys=raw}, range phys 0..252
          signal StatusCPDData1FBD_Trunk_AGCValue: start 16, 8 bit, little-endian, data-type-policy=OVERRIDE, base-type=uint8, compu {phys=raw}, range phys 0..252
          signal StatusCPDData1FBD_Trunk_Channel: start 24, 8 bit, little-endian, data-type-policy=OVERRIDE, base-type=uint8, compu {phys=raw}, range phys 0..252
          signal StatusCPDData1FBD_Trunk_CIRData00: start 32, 8 bit, little-endian, data-type-policy=OVERRIDE, base-type=uint8, compu {phys=raw}, range phys 0..255
          signal StatusCPDData1FBD_Trunk_CIRData01: start 40, 8 bit, little-endian, data-type-policy=OVERRIDE, base-type=uint8, compu {phys=raw}, range phys 0..255
          signal StatusCPDData1FBD_Trunk_CIRData02: start 48, 8 bit, little-endian, data-type-policy=OVERRIDE, base-type=uint8, compu {phys=raw}, range phys 0..255
          signal StatusCPDData1FBD_Trunk_CIRData03: start 56, 8 bit, little-endian, data-type-policy=OVERRIDE, base-type=uint8, compu {phys=raw}, range phys 0..255
          signal StatusCPDData1FBD_Trunk_CIRData04: start 64, 8 bit, little-endian, data-type-policy=OVERRIDE, base-type=uint8, compu {phys=raw}, range phys 0..255
          signal StatusCPDData1FBD_Trunk_CIRData05: start 72, 8 bit, little-endian, data-type-policy=OVERRIDE, base-type=uint8, compu {phys=raw}, range phys 0..255
          signal StatusCPDData1FBD_Trunk_CIRData06: start 80, 8 bit, little-endian, data-type-policy=OVERRIDE, base-type=uint8, compu {phys=raw}, range phys 0..255
          signal StatusCPDData1FBD_Trunk_CIRData07: start 88, 8 bit, little-endian, data-type-policy=OVERRIDE, base-type=uint8, compu {phys=raw}, range phys 0..255
          signal StatusCPDData1FBD_Trunk_CIRData08: start 96, 8 bit, little-endian, data-type-policy=OVERRIDE, base-type=uint8, compu {phys=raw}, range phys 0..255
          signal StatusCPDData1FBD_Trunk_CIRData09: start 104, 8 bit, little-endian, data-type-policy=OVERRIDE, base-type=uint8, compu {phys=raw}, range phys 0..255
          signal StatusCPDData1FBD_Trunk_CIRData10: start 112, 8 bit, little-endian, data-type-policy=OVERRIDE, base-type=uint8, compu {phys=raw}, range phys 0..255
          signal StatusCPDData1FBD_Trunk_CIRData11: start 120, 8 bit, little-endian, data-type-policy=OVERRIDE, base-type=uint8, compu {phys=raw}, range phys 0..255
          signal StatusCPDData1FBD_Trunk_CIRData12: start 128, 8 bit, little-endian, data-type-policy=OVERRIDE, base-type=uint8, compu {phys=raw}, range phys 0..255
          signal StatusCPDData1FBD_Trunk_CIRData13: start 136, 8 bit, little-endian, data-type-policy=OVERRIDE, base-type=uint8, compu {phys=raw}, range phys 0..255
          signal StatusCPDData1FBD_Trunk_CIRData14: start 144, 8 bit, little-endian, data-type-policy=OVERRIDE, base-type=uint8, compu {phys=raw}, range phys 0..255
          signal StatusCPDData1FBD_Trunk_CIRData15: start 152, 8 bit, little-endian, data-type-policy=OVERRIDE, base-type=uint8, compu {phys=raw}, range phys 0..255
          signal StatusCPDData1FBD_Trunk_CIRData16: start 160, 8 bit, little-endian, data-type-policy=OVERRIDE, base-type=uint8, compu {phys=raw}, range phys 0..255
          signal StatusCPDData1FBD_Trunk_CIRData17: start 168, 8 bit, little-endian, data-type-policy=OVERRIDE, base-type=uint8, compu {phys=raw}, range phys 0..255
          signal StatusCPDData1FBD_Trunk_CIRData18: start 176, 8 bit, little-endian, data-type-policy=OVERRIDE, base-type=uint8, compu {phys=raw}, range phys 0..255
          signal StatusCPDData1FBD_Trunk_CIRData19: start 184, 8 bit, little-endian, data-type-policy=OVERRIDE, base-type=uint8, compu {phys=raw}, range phys 0..255
          signal StatusCPDData1FBD_Trunk_CIRData20: start 192, 8 bit, little-endian, data-type-policy=OVERRIDE, base-type=uint8, compu {phys=raw}, range phys 0..255
          signal StatusCPDData1FBD_Trunk_CIRData21: start 200, 8 bit, little-endian, data-type-policy=OVERRIDE, base-type=uint8, compu {phys=raw}, range phys 0..255
          signal StatusCPDData1FBD_Trunk_CIRData22: start 208, 8 bit, little-endian, data-type-policy=OVERRIDE, base-type=uint8, compu {phys=raw}, range phys 0..255
          signal StatusCPDData1FBD_Trunk_CIRData23: start 216, 8 bit, little-endian, data-type-policy=OVERRIDE, base-type=uint8, compu {phys=raw}, range phys 0..255
          signal StatusCPDData1FBD_Trunk_CIRData24: start 224, 8 bit, little-endian, data-type-policy=OVERRIDE, base-type=uint8, compu {phys=raw}, range phys 0..255
          signal StatusCPDData1FBD_Trunk_CIRData25: start 232, 8 bit, little-endian, data-type-policy=OVERRIDE, base-type=uint8, compu {phys=raw}, range phys 0..255
          signal StatusCPDData1FBD_Trunk_CIRData26: start 240, 8 bit, little-endian, data-type-policy=OVERRIDE, base-type=uint8, compu {phys=raw}, range phys 0..255
          signal StatusCPDData1FBD_Trunk_CIRData27: start 248, 8 bit, little-endian, data-type-policy=OVERRIDE, base-type=uint8, compu {phys=raw}, range phys 0..255
          signal StatusCPDData1FBD_Trunk_CIRData28: start 256, 8 bit, little-endian, data-type-policy=OVERRIDE, base-type=uint8, compu {phys=raw}, range phys 0..255
          signal StatusCPDData1FBD_Trunk_CIRData29: start 264, 8 bit, little-endian, data-type-policy=OVERRIDE, base-type=uint8, compu {phys=raw}, range phys 0..255
          signal StatusCPDData1FBD_Trunk_CIRData30: start 272, 8 bit, little-endian, data-type-policy=OVERRIDE, base-type=uint8, compu {phys=raw}, range phys 0..255
          signal StatusCPDData1FBD_Trunk_CIRData31: start 280, 8 bit, little-endian, data-type-policy=OVERRIDE, base-type=uint8, compu {phys=raw}, range phys 0..255
          signal StatusCPDData1FBD_Trunk_CIRData32: start 288, 8 bit, little-endian, data-type-policy=OVERRIDE, base-type=uint8, compu {phys=raw}, range phys 0..255
          signal StatusCPDData1FBD_Trunk_CIRData33: start 296, 8 bit, little-endian, data-type-policy=OVERRIDE, base-type=uint8, compu {phys=raw}, range phys 0..255
          signal StatusCPDData1FBD_Trunk_CIRData34: start 304, 8 bit, little-endian, data-type-policy=OVERRIDE, base-type=uint8, compu {phys=raw}, range phys 0..255
          signal StatusCPDData1FBD_Trunk_CIRData35: start 312, 8 bit, little-endian, data-type-policy=OVERRIDE, base-type=uint8, compu {phys=raw}, range phys 0..255
          signal StatusCPDData1FBD_Trunk_CIRData36: start 320, 8 bit, little-endian, data-type-policy=OVERRIDE, base-type=uint8, compu {phys=raw}, range phys 0..255
          signal StatusCPDData1FBD_Trunk_CIRData37: start 328, 8 bit, little-endian, data-type-policy=OVERRIDE, base-type=uint8, compu {phys=raw}, range phys 0..255
          signal StatusCPDData1FBD_Trunk_CIRData38: start 336, 8 bit, little-endian, data-type-policy=OVERRIDE, base-type=uint8, compu {phys=raw}, range phys 0..255
          signal StatusCPDData1FBD_Trunk_CIRData39: start 344, 8 bit, little-endian, data-type-policy=OVERRIDE, base-type=uint8, compu {phys=raw}, range phys 0..255
          signal StatusCPDData1FBD_Trunk_CIRData40: start 352, 8 bit, little-endian, data-type-policy=OVERRIDE, base-type=uint8, compu {phys=raw}, range phys 0..255
          signal StatusCPDData1FBD_Trunk_CIRData41: start 360, 8 bit, little-endian, data-type-policy=OVERRIDE, base-type=uint8, compu {phys=raw}, range phys 0..255
          signal StatusCPDData1FBD_Trunk_CIRData42: start 368, 8 bit, little-endian, data-type-policy=OVERRIDE, base-type=uint8, compu {phys=raw}, range phys 0..255
          signal StatusCPDData1FBD_Trunk_CIRData43: start 376, 8 bit, little-endian, data-type-policy=OVERRIDE, base-type=uint8, compu {phys=raw}, range phys 0..255
          signal StatusCPDData1FBD_Trunk_CIRData44: start 384, 8 bit, little-endian, data-type-policy=OVERRIDE, base-type=uint8, compu {phys=raw}, range phys 0..255
          signal StatusCPDData1FBD_Trunk_CIRData45: start 392, 8 bit, little-endian, data-type-policy=OVERRIDE, base-type=uint8, compu {phys=raw}, range phys 0..255
          signal StatusCPDData1FBD_Trunk_CIRData46: start 400, 8 bit, little-endian, data-type-policy=OVERRIDE, base-type=uint8, compu {phys=raw}, range phys 0..255
          signal StatusCPDData1FBD_Trunk_CIRData47: start 408, 8 bit, little-endian, data-type-policy=OVERRIDE, base-type=uint8, compu {phys=raw}, range phys 0..255
          signal StatusCPDData1FBD_Trunk_CIRData48: start 416, 8 bit, little-endian, data-type-policy=OVERRIDE, base-type=uint8, compu {phys=raw}, range phys 0..255
          signal StatusCPDData1FBD_Trunk_CIRData49: start 424, 8 bit, little-endian, data-type-policy=OVERRIDE, base-type=uint8, compu {phys=raw}, range phys 0..255
          signal StatusCPDData1FBD_Trunk_CIRData50: start 432, 8 bit, little-endian, data-type-policy=OVERRIDE, base-type=uint8, compu {phys=raw}, range phys 0..255
          signal StatusCPDData1FBD_Trunk_CIRData51: start 440, 8 bit, little-endian, data-type-policy=OVERRIDE, base-type=uint8, compu {phys=raw}, range phys 0..255
          signal StatusCPDData1FBD_Trunk_CIRData52: start 448, 8 bit, little-endian, data-type-policy=OVERRIDE, base-type=uint8, compu {phys=raw}, range phys 0..255
          signal StatusCPDData1FBD_Trunk_CIRData53: start 456, 8 bit, little-endian, data-type-policy=OVERRIDE, base-type=uint8, compu {phys=raw}, range phys 0..255
          signal StatusCPDData1FBD_Trunk_CIRData54: start 464, 8 bit, little-endian, data-type-policy=OVERRIDE, base-type=uint8, compu {phys=raw}, range phys 0..255
          signal StatusCPDData1FBD_Trunk_CIRData55: start 472, 8 bit, little-endian, data-type-policy=OVERRIDE, base-type=uint8, compu {phys=raw}, range phys 0..255
          signal StatusCPDData1FBD_Trunk_CIRData56: start 480, 8 bit, little-endian, data-type-policy=OVERRIDE, base-type=uint8, compu {phys=raw}, range phys 0..255
          signal StatusCPDData1FBD_Trunk_CIRData57: start 488, 8 bit, little-endian, data-type-policy=OVERRIDE, base-type=uint8, compu {phys=raw}, range phys 0..255
          signal StatusCPDData1FBD_Trunk_CIRData58: start 496, 8 bit, little-endian, data-type-policy=OVERRIDE, base-type=uint8, compu {phys=raw}, range phys 0..255
          signal StatusCPDData1FBD_Trunk_CIRData59: start 504, 8 bit, little-endian, data-type-policy=OVERRIDE, base-type=uint8, compu {phys=raw}, range phys 0..255
